VERSION ""

NS_ :

BS_:

BU_:

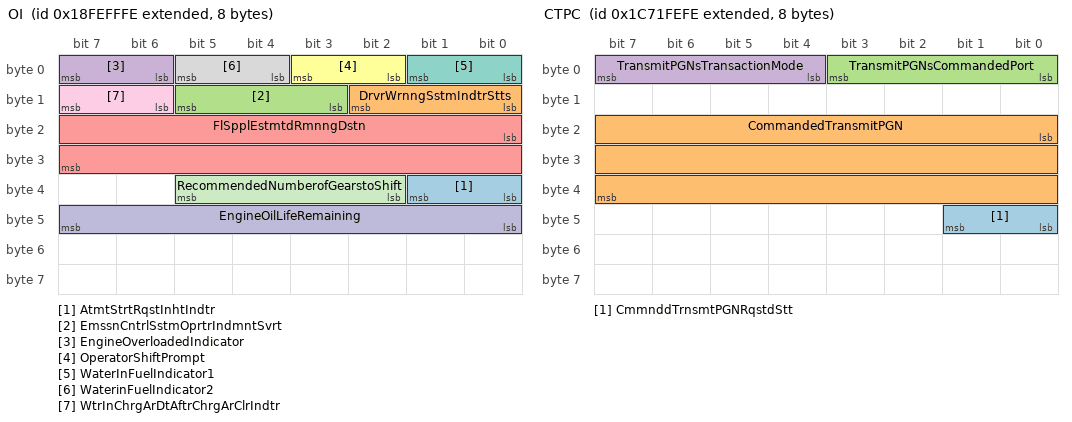
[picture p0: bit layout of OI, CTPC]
BO_ 2566848510 OI: 8 Vector__XXX
 SG_ AtmtStrtRqstInhtIndtr : 32|2@1+ (1,0) [0|3] "" Vector__XXX
 SG_ DrvrWrnngSstmIndtrStts : 8|3@1+ (1,0) [0|7] "" Vector__XXX
 SG_ EmssnCntrlSstmOprtrIndmntSvrt : 11|3@1+ (1,0) [0|7] "" Vector__XXX
 SG_ EngineOverloadedIndicator : 6|2@1+ (1,0) [0|3] "" Vector__XXX
 SG_ FlSpplEstmtdRmnngDstn : 16|16@1+ (1,0) [0|64255] "km" Vector__XXX
 SG_ OperatorShiftPrompt : 2|2@1+ (1,0) [0|3] "" Vector__XXX
 SG_ WaterInFuelIndicator1 : 0|2@1+ (1,0) [0|3] "" Vector__XXX
 SG_ WaterinFuelIndicator2 : 4|2@1+ (1,0) [0|3] "" Vector__XXX
 SG_ WtrInChrgArDtAftrChrgArClrIndtr : 14|2@1+ (1,0) [0|3] "" Vector__XXX
 SG_ EngineOilLifeRemaining : 40|8@1+ (0.4,0) [0|100] "%" Vector__XXX
 SG_ RecommendedNumberofGearstoShift : 34|4@1+ (1,0) [0|13] "count" Vector__XXX

BO_ 2624716542 CTPC: 8 Vector__XXX
 SG_ CmmnddTrnsmtPGNRqstdStt : 40|2@1+ (1,0) [0|3] "" Vector__XXX
 SG_ CommandedTransmitPGN : 16|24@1+ (1,0) [0|16777215] "binary" Vector__XXX
 SG_ TransmitPGNsCommandedPort : 0|4@1+ (1,0) [0|15] "" Vector__XXX
 SG_ TransmitPGNsTransactionMode : 4|4@1+ (1,0) [0|15] "" Vector__XXX

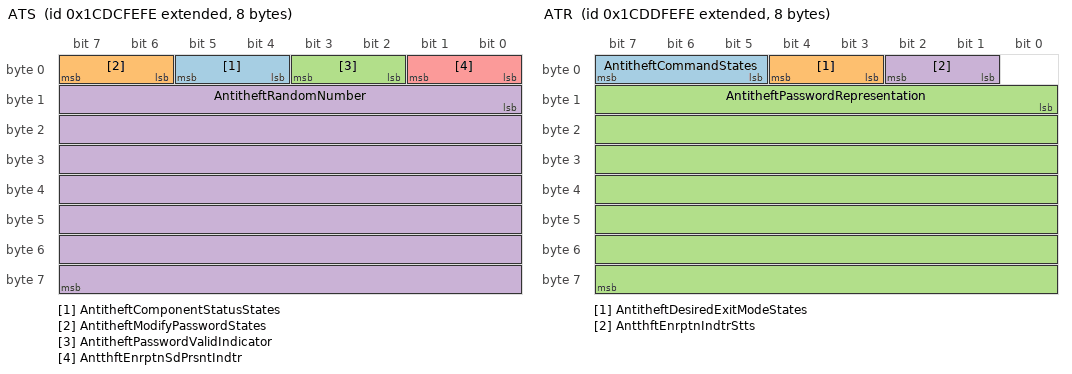
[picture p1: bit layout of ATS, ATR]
BO_ 2631728894 ATS: 8 Vector__XXX
 SG_ AntitheftComponentStatusStates : 4|2@1+ (1,0) [0|3] "" Vector__XXX
 SG_ AntitheftModifyPasswordStates : 6|2@1+ (1,0) [0|3] "" Vector__XXX
 SG_ AntitheftPasswordValidIndicator : 2|2@1+ (1,0) [0|3] "" Vector__XXX
 SG_ AntitheftRandomNumber : 8|56@1+ (1,0) [0|255] "ASCII" Vector__XXX
 SG_ AntthftEnrptnSdPrsntIndtr : 0|2@1+ (1,0) [0|3] "" Vector__XXX

BO_ 2631794430 ATR: 8 Vector__XXX
 SG_ AntitheftCommandStates : 5|3@1+ (1,0) [0|7] "" Vector__XXX
 SG_ AntitheftDesiredExitModeStates : 3|2@1+ (1,0) [0|3] "" Vector__XXX
 SG_ AntitheftPasswordRepresentation : 8|56@1+ (1,0) [0|255] "ASCII" Vector__XXX
 SG_ AntthftEnrptnIndtrStts : 1|2@1+ (1,0) [0|3] "" Vector__XXX

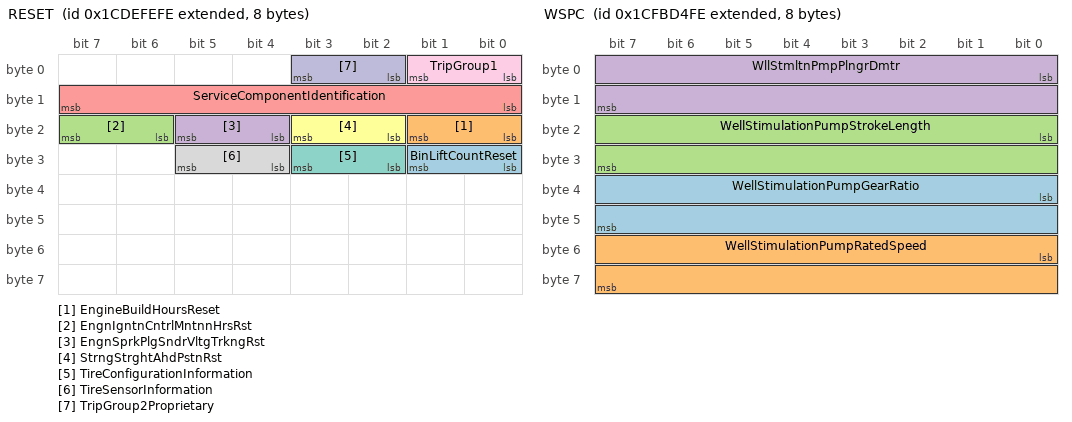
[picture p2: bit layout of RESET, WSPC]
BO_ 2631859966 RESET: 8 Vector__XXX
 SG_ BinLiftCountReset : 24|2@1+ (1,0) [0|3] "" Vector__XXX
 SG_ EngineBuildHoursReset : 16|2@1+ (1,0) [0|3] "" Vector__XXX
 SG_ EngnIgntnCntrlMntnnHrsRst : 22|2@1+ (1,0) [0|3] "" Vector__XXX
 SG_ EngnSprkPlgSndrVltgTrkngRst : 20|2@1+ (1,0) [0|3] "" Vector__XXX
 SG_ ServiceComponentIdentification : 8|8@1+ (1,0) [0|250] "ID" Vector__XXX
 SG_ StrngStrghtAhdPstnRst : 18|2@1+ (1,0) [0|3] "" Vector__XXX
 SG_ TireConfigurationInformation : 26|2@1+ (1,0) [0|3] "" Vector__XXX
 SG_ TireSensorInformation : 28|2@1+ (1,0) [0|3] "" Vector__XXX
 SG_ TripGroup1 : 0|2@1+ (1,0) [0|3] "" Vector__XXX
 SG_ TripGroup2Proprietary : 2|2@1+ (1,0) [0|3] "" Vector__XXX

BO_ 2633734398 EO2: 8 Vector__XXX
 SG_ EngineActualExhaust2Oxygen : 0|16@1+ (0.0025,0) [0|160.6375] "%" Vector__XXX

BO_ 2633749502 WSPT: 16 Vector__XXX
 SG_ WellStimulationPumpCycleCount : 96|32@1+ (1,0) [0|4211081215] "count" Vector__XXX
 SG_ WellStimulationPumpWorkingHours : 64|32@1+ (1,0) [0|4211081215] "s" Vector__XXX
 SG_ WllStmltnPmpFldEndWrkngHrs : 0|32@1+ (1,0) [0|4211081215] "s" Vector__XXX
 SG_ WllStmltnPmpPwrEndWrkngHrs : 32|32@1+ (1,0) [0|4211081215] "s" Vector__XXX

BO_ 2633749758 WSPC: 8 Vector__XXX
 SG_ WellStimulationPumpGearRatio : 32|16@1+ (0.001,0) [0|64.255] "Ratio" Vector__XXX
 SG_ WellStimulationPumpRatedSpeed : 48|16@1+ (0.125,0) [0|8031.875] "rpm" Vector__XXX
 SG_ WellStimulationPumpStrokeLength : 16|16@1+ (1,0) [0|64255] "mm" Vector__XXX
 SG_ WllStmltnPmpPlngrDmtr : 0|16@1+ (1,0) [0|64255] "mm" Vector__XXX

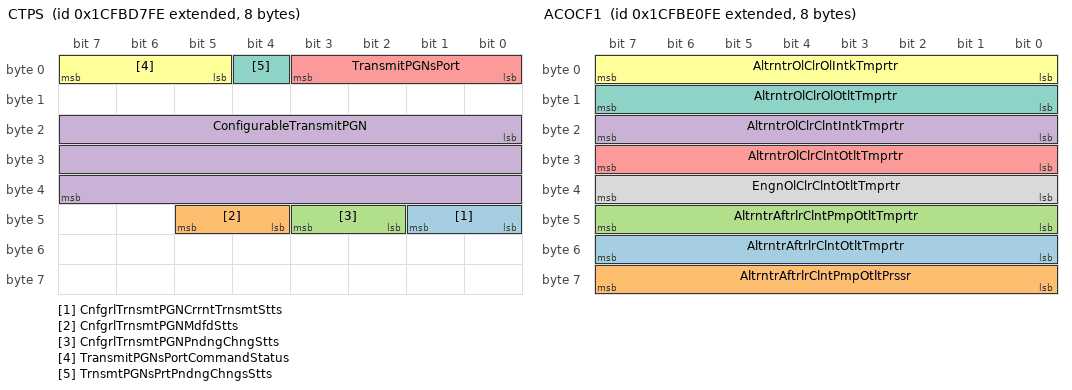
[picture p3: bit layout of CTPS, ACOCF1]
BO_ 2633750526 CTPS: 8 Vector__XXX
 SG_ CnfgrlTrnsmtPGNCrrntTrnsmtStts : 40|2@1+ (1,0) [0|3] "" Vector__XXX
 SG_ CnfgrlTrnsmtPGNMdfdStts : 44|2@1+ (1,0) [0|3] "" Vector__XXX
 SG_ CnfgrlTrnsmtPGNPndngChngStts : 42|2@1+ (1,0) [0|3] "" Vector__XXX
 SG_ ConfigurableTransmitPGN : 16|24@1+ (1,0) [0|16777215] "binary" Vector__XXX
 SG_ TransmitPGNsPort : 0|4@1+ (1,0) [0|15] "" Vector__XXX
 SG_ TransmitPGNsPortCommandStatus : 5|3@1+ (1,0) [0|7] "" Vector__XXX
 SG_ TrnsmtPGNsPrtPndngChngsStts : 4|1@1+ (1,0) [0|1] "" Vector__XXX

BO_ 2633752830 ACOCF1: 8 Vector__XXX
 SG_ AltrntrAftrlrClntOtltTmprtr : 48|8@1+ (1,-40) [-40|210] "degC" Vector__XXX
 SG_ AltrntrAftrlrClntPmpOtltPrssr : 56|8@1+ (2,0) [0|500] "kPa" Vector__XXX
 SG_ AltrntrAftrlrClntPmpOtltTmprtr : 40|8@1+ (1,-40) [-40|210] "degC" Vector__XXX
 SG_ AltrntrOlClrClntIntkTmprtr : 16|8@1+ (1,-40) [-40|210] "degC" Vector__XXX
 SG_ AltrntrOlClrClntOtltTmprtr : 24|8@1+ (1,-40) [-40|210] "degC" Vector__XXX
 SG_ AltrntrOlClrOlIntkTmprtr : 0|8@1+ (1,-40) [-40|210] "degC" Vector__XXX
 SG_ AltrntrOlClrOlOtltTmprtr : 8|8@1+ (1,-40) [-40|210] "degC" Vector__XXX
 SG_ EngnOlClrClntOtltTmprtr : 32|8@1+ (1,-40) [-40|210] "degC" Vector__XXX

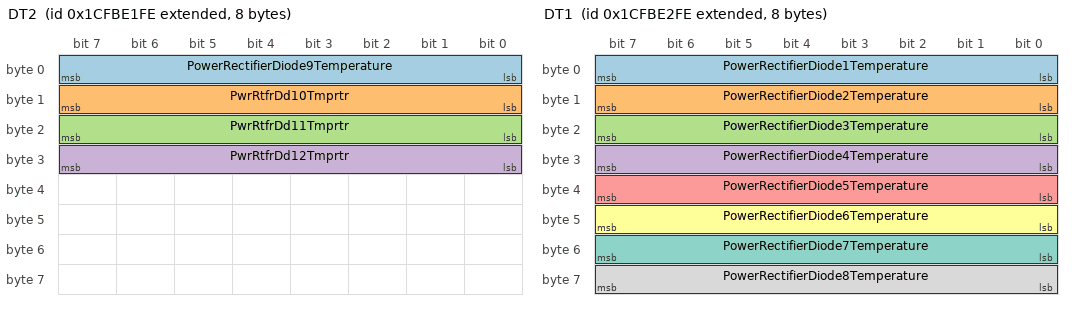
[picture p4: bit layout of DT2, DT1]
BO_ 2633753086 DT2: 8 Vector__XXX
 SG_ PowerRectifierDiode9Temperature : 0|8@1+ (1,-40) [-40|210] "degC" Vector__XXX
 SG_ PwrRtfrDd10Tmprtr : 8|8@1+ (1,-40) [-40|210] "degC" Vector__XXX
 SG_ PwrRtfrDd11Tmprtr : 16|8@1+ (1,-40) [-40|210] "degC" Vector__XXX
 SG_ PwrRtfrDd12Tmprtr : 24|8@1+ (1,-40) [-40|210] "degC" Vector__XXX

BO_ 2633753342 DT1: 8 Vector__XXX
 SG_ PowerRectifierDiode1Temperature : 0|8@1+ (1,-40) [-40|210] "degC" Vector__XXX
 SG_ PowerRectifierDiode2Temperature : 8|8@1+ (1,-40) [-40|210] "degC" Vector__XXX
 SG_ PowerRectifierDiode3Temperature : 16|8@1+ (1,-40) [-40|210] "degC" Vector__XXX
 SG_ PowerRectifierDiode4Temperature : 24|8@1+ (1,-40) [-40|210] "degC" Vector__XXX
 SG_ PowerRectifierDiode5Temperature : 32|8@1+ (1,-40) [-40|210] "degC" Vector__XXX
 SG_ PowerRectifierDiode6Temperature : 40|8@1+ (1,-40) [-40|210] "degC" Vector__XXX
 SG_ PowerRectifierDiode7Temperature : 48|8@1+ (1,-40) [-40|210] "degC" Vector__XXX
 SG_ PowerRectifierDiode8Temperature : 56|8@1+ (1,-40) [-40|210] "degC" Vector__XXX

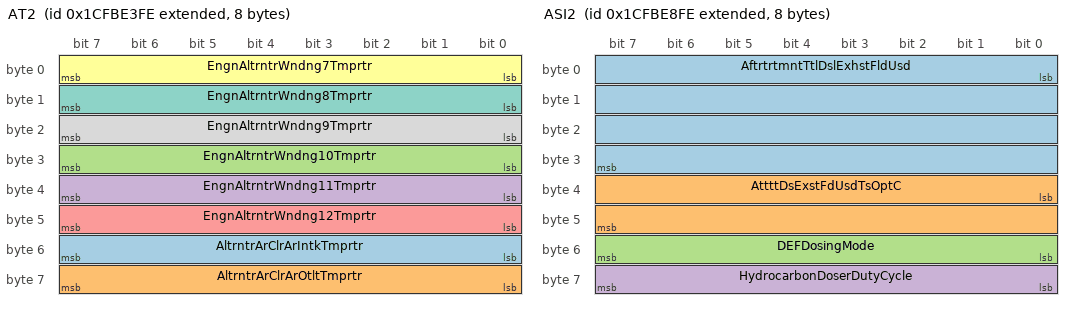
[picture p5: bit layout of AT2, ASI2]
BO_ 2633753598 AT2: 8 Vector__XXX
 SG_ AltrntrArClrArIntkTmprtr : 48|8@1+ (1,-40) [-40|210] "degC" Vector__XXX
 SG_ AltrntrArClrArOtltTmprtr : 56|8@1+ (1,-40) [-40|210] "degC" Vector__XXX
 SG_ EngnAltrntrWndng10Tmprtr : 24|8@1+ (1,-40) [-40|210] "degC" Vector__XXX
 SG_ EngnAltrntrWndng11Tmprtr : 32|8@1+ (1,-40) [-40|210] "degC" Vector__XXX
 SG_ EngnAltrntrWndng12Tmprtr : 40|8@1+ (1,-40) [-40|210] "degC" Vector__XXX
 SG_ EngnAltrntrWndng7Tmprtr : 0|8@1+ (1,-40) [-40|210] "degC" Vector__XXX
 SG_ EngnAltrntrWndng8Tmprtr : 8|8@1+ (1,-40) [-40|210] "degC" Vector__XXX
 SG_ EngnAltrntrWndng9Tmprtr : 16|8@1+ (1,-40) [-40|210] "degC" Vector__XXX

BO_ 2633754622 SCROII5: 8 Vector__XXX
 SG_ Aftrtrtmnt1SCRIntkHghTmprtrTm : 0|32@1+ (1,0) [0|4211081215] "s" Vector__XXX
 SG_ SCROptIdtEOvdTtAtvtT : 32|32@1+ (1,0) [0|4211081215] "s" Vector__XXX

BO_ 2633754878 ASI2: 8 Vector__XXX
 SG_ AftrtrtmntTtlDslExhstFldUsd : 0|32@1+ (0.5,0) [0|2105540607.5] "l" Vector__XXX
 SG_ AttttDsExstFdUsdTsOptC : 32|16@1+ (0.1,0) [0|6425.5] "l" Vector__XXX
 SG_ DEFDosingMode : 48|8@1+ (1,0) [0|250] "count" Vector__XXX
 SG_ HydrocarbonDoserDutyCycle : 56|8@1+ (0.4,0) [0|100] "%" Vector__XXX

BO_ 2633755390 E1NET1: 19 Vector__XXX
 SG_ DefaultGatewayOctet1 : 72|8@1+ (1,0) [0|255] "count" Vector__XXX
 SG_ DefaultGatewayOctet2 : 80|8@1+ (1,0) [0|255] "count" Vector__XXX
 SG_ DefaultGatewayOctet3 : 88|8@1+ (1,0) [0|255] "count" Vector__XXX
 SG_ DefaultGatewayOctet4 : 96|8@1+ (1,0) [0|255] "count" Vector__XXX
 SG_ DHCPStatus : 0|4@1+ (1,0) [0|15] "" Vector__XXX
 SG_ EthernetLinkStatus : 4|2@1+ (1,0) [0|3] "" Vector__XXX
 SG_ IPv4AddressOctet1 : 8|8@1+ (1,0) [0|255] "count" Vector__XXX
 SG_ IPv4AddressOctet2 : 16|8@1+ (1,0) [0|255] "count" Vector__XXX
 SG_ IPv4AddressOctet3 : 24|8@1+ (1,0) [0|255] "count" Vector__XXX
 SG_ IPv4AddressOctet4 : 32|8@1+ (1,0) [0|255] "count" Vector__XXX
 SG_ MACAddressOctet1 : 104|8@1+ (1,0) [0|255] "count" Vector__XXX
 SG_ MACAddressOctet2 : 112|8@1+ (1,0) [0|255] "count" Vector__XXX
 SG_ MACAddressOctet3 : 120|8@1+ (1,0) [0|255] "count" Vector__XXX
 SG_ MACAddressOctet4 : 128|8@1+ (1,0) [0|255] "count" Vector__XXX
 SG_ MACAddressOctet5 : 136|8@1+ (1,0) [0|255] "count" Vector__XXX
 SG_ MACAddressOctet6 : 144|8@1+ (1,0) [0|255] "count" Vector__XXX
 SG_ SubnetMaskOctet1 : 40|8@1+ (1,0) [0|255] "count" Vector__XXX
 SG_ SubnetMaskOctet2 : 48|8@1+ (1,0) [0|255] "count" Vector__XXX
 SG_ SubnetMaskOctet3 : 56|8@1+ (1,0) [0|255] "count" Vector__XXX
 SG_ SubnetMaskOctet4 : 64|8@1+ (1,0) [0|255] "count" Vector__XXX

BO_ 2633764094 EVAP2: 4 Vector__XXX
 SG_ CanisterPurgeValveCommand : 8|8@1+ (0.4,0) [0|100] "%" Vector__XXX
 SG_ CanisterVentValve : 0|2@1+ (1,0) [0|3] "" Vector__XXX
 SG_ GasolineFuelTankPressure : 16|16@1+ (0.1,-3212.7) [-3212.7|3212.8] "kPa" Vector__XXX

BO_ 2633764350 FPS1: 8 Vector__XXX
 SG_ FirePumpEngagementCycles : 32|16@1+ (1,0) [0|64255] "count" Vector__XXX
 SG_ FirePumpOperationTime : 0|32@1+ (1,0) [0|4211081215] "s" Vector__XXX

BO_ 2633769726 EEC19: 8 Vector__XXX
 SG_ EngnExhstFlwRtExtnddRng : 32|32@1+ (0.001,0) [0|4211081.215] "kg/h" Vector__XXX
 SG_ TotalEngineEnergy : 0|32@1+ (1,0) [0|4211081215] "kWh" Vector__XXX

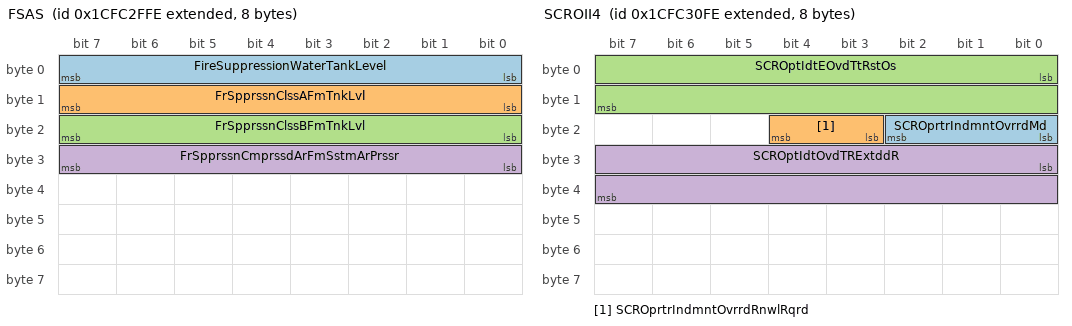
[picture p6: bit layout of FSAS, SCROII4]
BO_ 2633773054 FSAS: 8 Vector__XXX
 SG_ FireSuppressionWaterTankLevel : 0|8@1+ (0.4,0) [0|100] "%" Vector__XXX
 SG_ FrSpprssnClssAFmTnkLvl : 8|8@1+ (0.4,0) [0|100] "%" Vector__XXX
 SG_ FrSpprssnClssBFmTnkLvl : 16|8@1+ (0.4,0) [0|100] "%" Vector__XXX
 SG_ FrSpprssnCmprssdArFmSstmArPrssr : 24|8@1+ (8,0) [0|2000] "kPa" Vector__XXX

BO_ 2633773310 SCROII4: 8 Vector__XXX
 SG_ SCROprtrIndmntOvrrdMd : 16|3@1+ (1,0) [0|7] "" Vector__XXX
 SG_ SCROprtrIndmntOvrrdRnwlRqrd : 19|2@1+ (1,0) [0|3] "" Vector__XXX
 SG_ SCROptIdtEOvdTtRstOs : 0|16@1+ (1,0) [0|64255] "count" Vector__XXX
 SG_ SCROptIdtOvdTRExtddR : 24|16@1+ (1,0) [0|64255] "min" Vector__XXX

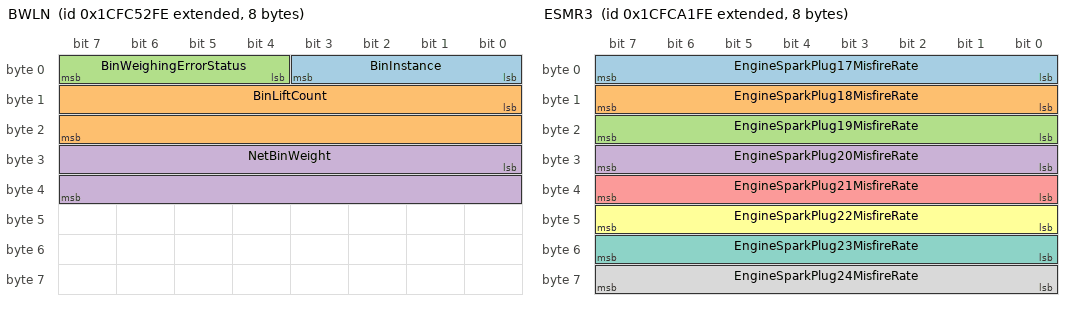
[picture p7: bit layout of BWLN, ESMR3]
BO_ 2633782014 BWLN: 8 Vector__XXX
 SG_ BinInstance : 0|4@1+ (1,0) [0|15] "count" Vector__XXX
 SG_ BinLiftCount : 8|16@1+ (1,0) [0|64255] "count" Vector__XXX
 SG_ BinWeighingErrorStatus : 4|4@1+ (1,0) [0|15] "" Vector__XXX
 SG_ NetBinWeight : 24|16@1+ (2,0) [0|128510] "kg" Vector__XXX

BO_ 2633785086 HVESSHIST: 19 Vector__XXX
 SG_ HVESSStateofHealth : 0|8@1+ (0.4,0) [0|100] "%" Vector__XXX
 SG_ HVESSCnttrOpnUndrLdCnt : 8|16@1+ (1,0) [0|64255] "count" Vector__XXX
 SG_ HVESSTotalEnergyThroughput : 24|32@1+ (100,0) [0|421108121500] "Watt-hour" Vector__XXX
 SG_ HVESSTotalAccumulatedCharge : 56|32@1+ (100,0) [0|421108121500] "Ah" Vector__XXX
 SG_ HVESSTotalLifetimeEnergyInput : 88|32@1+ (1,0) [0|4211081215] "kWh" Vector__XXX
 SG_ HVESSTotalLifetimeEnergyOutput : 120|32@1+ (1,0) [0|4211081215] "kWh" Vector__XXX

BO_ 2633801982 MFEH: 8 Vector__XXX
 SG_ EngnTtlHrsfDslFlOprtn : 32|32@1+ (0.05,0) [0|210554060.75] "h" Vector__XXX
 SG_ EngnTtlHrsfGssFlOprtn : 0|32@1+ (0.05,0) [0|210554060.75] "h" Vector__XXX

BO_ 2633802238 ESMR3: 8 Vector__XXX
 SG_ EngineSparkPlug17MisfireRate : 0|8@1+ (0.4,0) [0|100] "%" Vector__XXX
 SG_ EngineSparkPlug18MisfireRate : 8|8@1+ (0.4,0) [0|100] "%" Vector__XXX
 SG_ EngineSparkPlug19MisfireRate : 16|8@1+ (0.4,0) [0|100] "%" Vector__XXX
 SG_ EngineSparkPlug20MisfireRate : 24|8@1+ (0.4,0) [0|100] "%" Vector__XXX
 SG_ EngineSparkPlug21MisfireRate : 32|8@1+ (0.4,0) [0|100] "%" Vector__XXX
 SG_ EngineSparkPlug22MisfireRate : 40|8@1+ (0.4,0) [0|100] "%" Vector__XXX
 SG_ EngineSparkPlug23MisfireRate : 48|8@1+ (0.4,0) [0|100] "%" Vector__XXX
 SG_ EngineSparkPlug24MisfireRate : 56|8@1+ (0.4,0) [0|100] "%" Vector__XXX

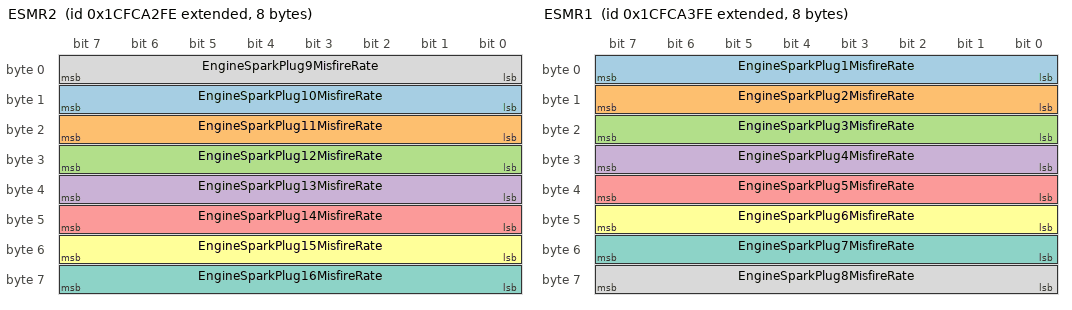
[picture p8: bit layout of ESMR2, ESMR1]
BO_ 2633802494 ESMR2: 8 Vector__XXX
 SG_ EngineSparkPlug10MisfireRate : 8|8@1+ (0.4,0) [0|100] "%" Vector__XXX
 SG_ EngineSparkPlug11MisfireRate : 16|8@1+ (0.4,0) [0|100] "%" Vector__XXX
 SG_ EngineSparkPlug12MisfireRate : 24|8@1+ (0.4,0) [0|100] "%" Vector__XXX
 SG_ EngineSparkPlug13MisfireRate : 32|8@1+ (0.4,0) [0|100] "%" Vector__XXX
 SG_ EngineSparkPlug14MisfireRate : 40|8@1+ (0.4,0) [0|100] "%" Vector__XXX
 SG_ EngineSparkPlug15MisfireRate : 48|8@1+ (0.4,0) [0|100] "%" Vector__XXX
 SG_ EngineSparkPlug16MisfireRate : 56|8@1+ (0.4,0) [0|100] "%" Vector__XXX
 SG_ EngineSparkPlug9MisfireRate : 0|8@1+ (0.4,0) [0|100] "%" Vector__XXX

BO_ 2633802750 ESMR1: 8 Vector__XXX
 SG_ EngineSparkPlug1MisfireRate : 0|8@1+ (0.4,0) [0|100] "%" Vector__XXX
 SG_ EngineSparkPlug2MisfireRate : 8|8@1+ (0.4,0) [0|100] "%" Vector__XXX
 SG_ EngineSparkPlug3MisfireRate : 16|8@1+ (0.4,0) [0|100] "%" Vector__XXX
 SG_ EngineSparkPlug4MisfireRate : 24|8@1+ (0.4,0) [0|100] "%" Vector__XXX
 SG_ EngineSparkPlug5MisfireRate : 32|8@1+ (0.4,0) [0|100] "%" Vector__XXX
 SG_ EngineSparkPlug6MisfireRate : 40|8@1+ (0.4,0) [0|100] "%" Vector__XXX
 SG_ EngineSparkPlug7MisfireRate : 48|8@1+ (0.4,0) [0|100] "%" Vector__XXX
 SG_ EngineSparkPlug8MisfireRate : 56|8@1+ (0.4,0) [0|100] "%" Vector__XXX

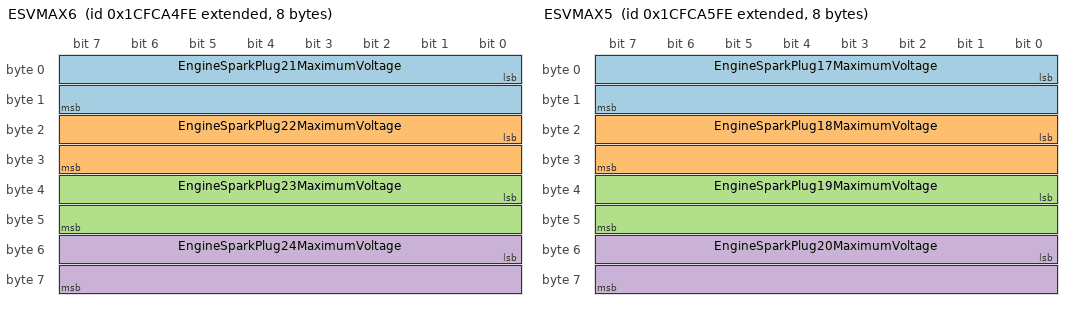
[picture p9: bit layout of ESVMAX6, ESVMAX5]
BO_ 2633803006 ESVMAX6: 8 Vector__XXX
 SG_ EngineSparkPlug21MaximumVoltage : 0|16@1+ (1,0) [0|64255] "V" Vector__XXX
 SG_ EngineSparkPlug22MaximumVoltage : 16|16@1+ (1,0) [0|64255] "V" Vector__XXX
 SG_ EngineSparkPlug23MaximumVoltage : 32|16@1+ (1,0) [0|64255] "V" Vector__XXX
 SG_ EngineSparkPlug24MaximumVoltage : 48|16@1+ (1,0) [0|64255] "V" Vector__XXX

BO_ 2633803262 ESVMAX5: 8 Vector__XXX
 SG_ EngineSparkPlug17MaximumVoltage : 0|16@1+ (1,0) [0|64255] "V" Vector__XXX
 SG_ EngineSparkPlug18MaximumVoltage : 16|16@1+ (1,0) [0|64255] "V" Vector__XXX
 SG_ EngineSparkPlug19MaximumVoltage : 32|16@1+ (1,0) [0|64255] "V" Vector__XXX
 SG_ EngineSparkPlug20MaximumVoltage : 48|16@1+ (1,0) [0|64255] "V" Vector__XXX

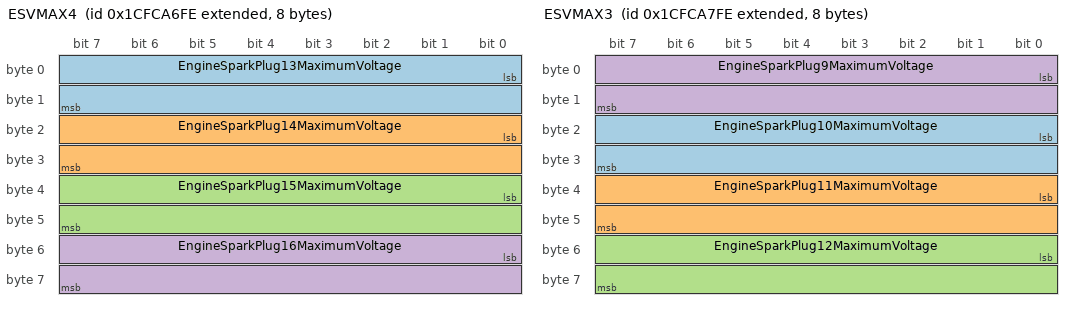
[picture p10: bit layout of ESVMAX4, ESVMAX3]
BO_ 2633803518 ESVMAX4: 8 Vector__XXX
 SG_ EngineSparkPlug13MaximumVoltage : 0|16@1+ (1,0) [0|64255] "V" Vector__XXX
 SG_ EngineSparkPlug14MaximumVoltage : 16|16@1+ (1,0) [0|64255] "V" Vector__XXX
 SG_ EngineSparkPlug15MaximumVoltage : 32|16@1+ (1,0) [0|64255] "V" Vector__XXX
 SG_ EngineSparkPlug16MaximumVoltage : 48|16@1+ (1,0) [0|64255] "V" Vector__XXX

BO_ 2633803774 ESVMAX3: 8 Vector__XXX
 SG_ EngineSparkPlug10MaximumVoltage : 16|16@1+ (1,0) [0|64255] "V" Vector__XXX
 SG_ EngineSparkPlug11MaximumVoltage : 32|16@1+ (1,0) [0|64255] "V" Vector__XXX
 SG_ EngineSparkPlug12MaximumVoltage : 48|16@1+ (1,0) [0|64255] "V" Vector__XXX
 SG_ EngineSparkPlug9MaximumVoltage : 0|16@1+ (1,0) [0|64255] "V" Vector__XXX

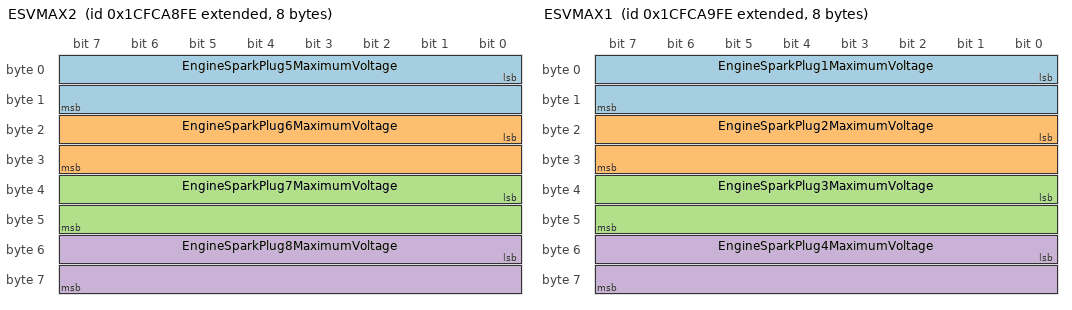
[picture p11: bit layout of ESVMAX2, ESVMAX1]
BO_ 2633804030 ESVMAX2: 8 Vector__XXX
 SG_ EngineSparkPlug5MaximumVoltage : 0|16@1+ (1,0) [0|64255] "V" Vector__XXX
 SG_ EngineSparkPlug6MaximumVoltage : 16|16@1+ (1,0) [0|64255] "V" Vector__XXX
 SG_ EngineSparkPlug7MaximumVoltage : 32|16@1+ (1,0) [0|64255] "V" Vector__XXX
 SG_ EngineSparkPlug8MaximumVoltage : 48|16@1+ (1,0) [0|64255] "V" Vector__XXX

BO_ 2633804286 ESVMAX1: 8 Vector__XXX
 SG_ EngineSparkPlug1MaximumVoltage : 0|16@1+ (1,0) [0|64255] "V" Vector__XXX
 SG_ EngineSparkPlug2MaximumVoltage : 16|16@1+ (1,0) [0|64255] "V" Vector__XXX
 SG_ EngineSparkPlug3MaximumVoltage : 32|16@1+ (1,0) [0|64255] "V" Vector__XXX
 SG_ EngineSparkPlug4MaximumVoltage : 48|16@1+ (1,0) [0|64255] "V" Vector__XXX

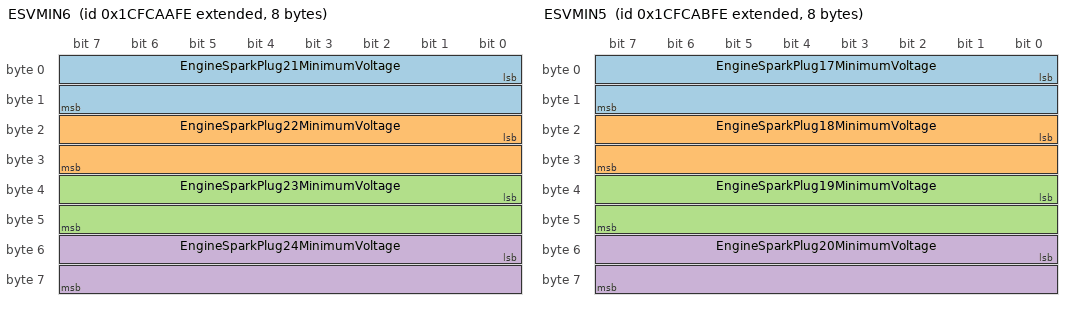
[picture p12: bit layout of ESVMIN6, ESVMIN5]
BO_ 2633804542 ESVMIN6: 8 Vector__XXX
 SG_ EngineSparkPlug21MinimumVoltage : 0|16@1+ (1,0) [0|64255] "V" Vector__XXX
 SG_ EngineSparkPlug22MinimumVoltage : 16|16@1+ (1,0) [0|64255] "V" Vector__XXX
 SG_ EngineSparkPlug23MinimumVoltage : 32|16@1+ (1,0) [0|64255] "V" Vector__XXX
 SG_ EngineSparkPlug24MinimumVoltage : 48|16@1+ (1,0) [0|64255] "V" Vector__XXX

BO_ 2633804798 ESVMIN5: 8 Vector__XXX
 SG_ EngineSparkPlug17MinimumVoltage : 0|16@1+ (1,0) [0|64255] "V" Vector__XXX
 SG_ EngineSparkPlug18MinimumVoltage : 16|16@1+ (1,0) [0|64255] "V" Vector__XXX
 SG_ EngineSparkPlug19MinimumVoltage : 32|16@1+ (1,0) [0|64255] "V" Vector__XXX
 SG_ EngineSparkPlug20MinimumVoltage : 48|16@1+ (1,0) [0|64255] "V" Vector__XXX

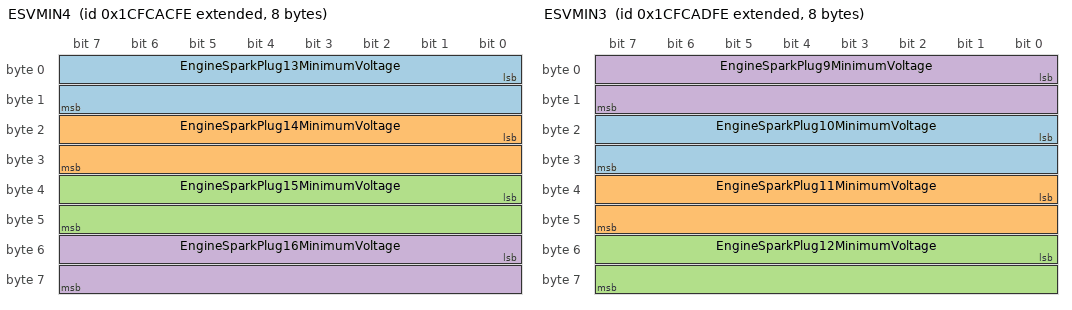
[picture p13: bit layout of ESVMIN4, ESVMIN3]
BO_ 2633805054 ESVMIN4: 8 Vector__XXX
 SG_ EngineSparkPlug13MinimumVoltage : 0|16@1+ (1,0) [0|64255] "V" Vector__XXX
 SG_ EngineSparkPlug14MinimumVoltage : 16|16@1+ (1,0) [0|64255] "V" Vector__XXX
 SG_ EngineSparkPlug15MinimumVoltage : 32|16@1+ (1,0) [0|64255] "V" Vector__XXX
 SG_ EngineSparkPlug16MinimumVoltage : 48|16@1+ (1,0) [0|64255] "V" Vector__XXX

BO_ 2633805310 ESVMIN3: 8 Vector__XXX
 SG_ EngineSparkPlug10MinimumVoltage : 16|16@1+ (1,0) [0|64255] "V" Vector__XXX
 SG_ EngineSparkPlug11MinimumVoltage : 32|16@1+ (1,0) [0|64255] "V" Vector__XXX
 SG_ EngineSparkPlug12MinimumVoltage : 48|16@1+ (1,0) [0|64255] "V" Vector__XXX
 SG_ EngineSparkPlug9MinimumVoltage : 0|16@1+ (1,0) [0|64255] "V" Vector__XXX

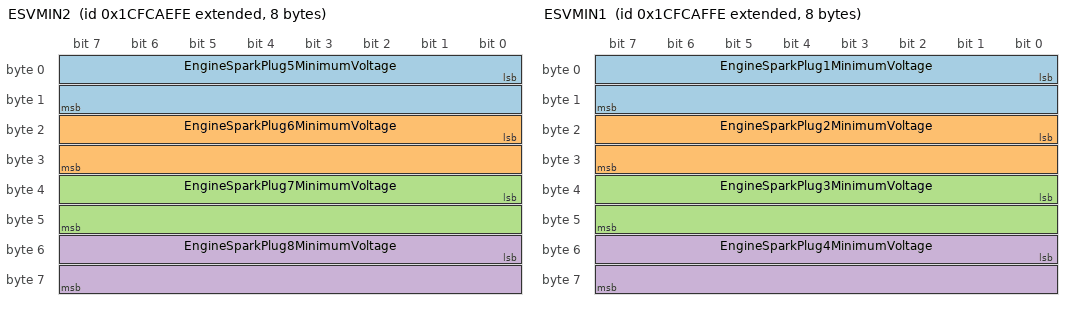
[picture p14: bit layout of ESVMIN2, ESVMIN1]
BO_ 2633805566 ESVMIN2: 8 Vector__XXX
 SG_ EngineSparkPlug5MinimumVoltage : 0|16@1+ (1,0) [0|64255] "V" Vector__XXX
 SG_ EngineSparkPlug6MinimumVoltage : 16|16@1+ (1,0) [0|64255] "V" Vector__XXX
 SG_ EngineSparkPlug7MinimumVoltage : 32|16@1+ (1,0) [0|64255] "V" Vector__XXX
 SG_ EngineSparkPlug8MinimumVoltage : 48|16@1+ (1,0) [0|64255] "V" Vector__XXX

BO_ 2633805822 ESVMIN1: 8 Vector__XXX
 SG_ EngineSparkPlug1MinimumVoltage : 0|16@1+ (1,0) [0|64255] "V" Vector__XXX
 SG_ EngineSparkPlug2MinimumVoltage : 16|16@1+ (1,0) [0|64255] "V" Vector__XXX
 SG_ EngineSparkPlug3MinimumVoltage : 32|16@1+ (1,0) [0|64255] "V" Vector__XXX
 SG_ EngineSparkPlug4MinimumVoltage : 48|16@1+ (1,0) [0|64255] "V" Vector__XXX

BO_ 2633806078 EICMH: 8 Vector__XXX
 SG_ EngnIgntnCntrlMdl1TmRmnng : 0|32@1+ (0.05,0) [0|210554060.75] "h" Vector__XXX
 SG_ EngnIgntnCntrlMdl2TmRmnng : 32|32@1+ (0.05,0) [0|210554060.75] "h" Vector__XXX

BO_ 2633825022 EEC11: 8 Vector__XXX
 SG_ EngnExhstGsRrltn2Vlv1Cntrl : 0|16@1+ (0.0025,0) [0|160.6375] "%" Vector__XXX
 SG_ EngnExhstGsRrltn2Vlv1PstnErrr : 32|16@1+ (0.004,-125) [-125|132.02] "%" Vector__XXX
 SG_ EngnExhstGsRrltn2Vlv2Cntrl : 16|16@1+ (0.0025,0) [0|160.6375] "%" Vector__XXX
 SG_ EngnExhstGsRrltn2Vlv2PstnErrr : 48|16@1+ (0.004,-125) [-125|132.02] "%" Vector__XXX

BO_ 2633825534 EMAC: 8 Vector__XXX
 SG_ EExstMdB1FwBVvAttCt : 0|16@1+ (0.0025,0) [0|160.6375] "%" Vector__XXX
 SG_ EExstMdB2FwBVvAttCt : 16|16@1+ (0.0025,0) [0|160.6375] "%" Vector__XXX

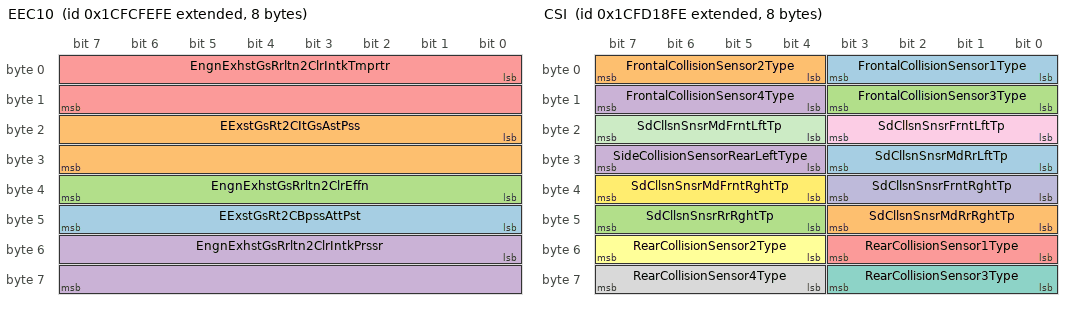
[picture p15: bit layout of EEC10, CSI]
BO_ 2633826046 EEC10: 8 Vector__XXX
 SG_ EExstGsRt2CBpssAttPst : 40|8@1+ (0.4,0) [0|100] "%" Vector__XXX
 SG_ EExstGsRt2CItGsAstPss : 16|16@1+ (0.5,0) [0|32127.5] "kPa" Vector__XXX
 SG_ EngnExhstGsRrltn2ClrEffn : 32|8@1+ (0.4,0) [0|100] "%" Vector__XXX
 SG_ EngnExhstGsRrltn2ClrIntkPrssr : 48|16@1+ (5,0) [0|321275] "kPa" Vector__XXX
 SG_ EngnExhstGsRrltn2ClrIntkTmprtr : 0|16@1+ (0.03125,-273) [-273|1734.96875] "degC" Vector__XXX

BO_ 2633828606 EOM: 8 Vector__XXX
 SG_ EngineOilDensity : 16|16@1+ (0.00003052,0) [0|1.961] "g/cc" Vector__XXX
 SG_ EngineOilTemperature3 : 48|16@1+ (0.03125,-273) [-273|1734.96875] "degC" Vector__XXX
 SG_ EngineOilViscosity : 0|16@1+ (0.015625,0) [0|1003.984375] "Cp" Vector__XXX
 SG_ EngnOlRltvDltrtHghRsltn : 32|16@1+ (0.0001220703125,0) [0|7.844] "" Vector__XXX

BO_ 2633832702 CSI: 8 Vector__XXX
 SG_ FrontalCollisionSensor1Type : 0|4@1+ (1,0) [0|15] "" Vector__XXX
 SG_ FrontalCollisionSensor2Type : 4|4@1+ (1,0) [0|15] "" Vector__XXX
 SG_ FrontalCollisionSensor3Type : 8|4@1+ (1,0) [0|15] "" Vector__XXX
 SG_ FrontalCollisionSensor4Type : 12|4@1+ (1,0) [0|15] "" Vector__XXX
 SG_ RearCollisionSensor1Type : 48|4@1+ (1,0) [0|15] "" Vector__XXX
 SG_ RearCollisionSensor2Type : 52|4@1+ (1,0) [0|15] "" Vector__XXX
 SG_ RearCollisionSensor3Type : 56|4@1+ (1,0) [0|15] "" Vector__XXX
 SG_ RearCollisionSensor4Type : 60|4@1+ (1,0) [0|15] "" Vector__XXX
 SG_ SdCllsnSnsrFrntLftTp : 16|4@1+ (1,0) [0|15] "" Vector__XXX
 SG_ SdCllsnSnsrFrntRghtTp : 32|4@1+ (1,0) [0|15] "" Vector__XXX
 SG_ SdCllsnSnsrMdFrntLftTp : 20|4@1+ (1,0) [0|15] "" Vector__XXX
 SG_ SdCllsnSnsrMdFrntRghtTp : 36|4@1+ (1,0) [0|15] "" Vector__XXX
 SG_ SdCllsnSnsrMdRrLftTp : 24|4@1+ (1,0) [0|15] "" Vector__XXX
 SG_ SdCllsnSnsrMdRrRghtTp : 40|4@1+ (1,0) [0|15] "" Vector__XXX
 SG_ SdCllsnSnsrRrRghtTp : 44|4@1+ (1,0) [0|15] "" Vector__XXX
 SG_ SideCollisionSensorRearLeftType : 28|4@1+ (1,0) [0|15] "" Vector__XXX

BO_ 2633832958 ILI: 200 Vector__XXX
 SG_ DrvrArgIgntrLp1stStgRsstn : 0|16@1+ (0.1,0) [0|6425.5] "ohm" Vector__XXX
 SG_ DrvrArgIgntrLp2ndStgRsstn : 32|16@1+ (0.1,0) [0|6425.5] "ohm" Vector__XXX
 SG_ DrvrBltTnsnrIgntrLpRsstn : 64|16@1+ (0.1,0) [0|6425.5] "ohm" Vector__XXX
 SG_ PssngrArgIgntrLp1stStgRsstn : 16|16@1+ (0.1,0) [0|6425.5] "ohm" Vector__XXX
 SG_ PssngrArgIgntrLp2ndStgRsstn : 48|16@1+ (0.1,0) [0|6425.5] "ohm" Vector__XXX
 SG_ PssngrBltTnsnrIgntrLpRsstn : 80|16@1+ (0.1,0) [0|6425.5] "ohm" Vector__XXX
 SG_ SdBgIgntrLp1LftRsstn : 96|16@1+ (0.1,0) [0|6425.5] "ohm" Vector__XXX
 SG_ SdBgIgntrLp1RghtRsstn : 128|16@1+ (0.1,0) [0|6425.5] "ohm" Vector__XXX
 SG_ SdBgIgntrLp2LftRsstn : 112|16@1+ (0.1,0) [0|6425.5] "ohm" Vector__XXX
 SG_ SdBgIgntrLp2RghtRsstn : 144|16@1+ (0.1,0) [0|6425.5] "ohm" Vector__XXX
 SG_ SpecialIgnitorLoop10Resistance : 304|16@1+ (0.1,0) [0|6425.5] "ohm" Vector__XXX
 SG_ SpecialIgnitorLoop11Resistance : 320|16@1+ (0.1,0) [0|6425.5] "ohm" Vector__XXX
 SG_ SpecialIgnitorLoop12Resistance : 336|16@1+ (0.1,0) [0|6425.5] "ohm" Vector__XXX
 SG_ SpecialIgnitorLoop13Resistance : 352|16@1+ (0.1,0) [0|6425.5] "ohm" Vector__XXX
 SG_ SpecialIgnitorLoop14Resistance : 368|16@1+ (0.1,0) [0|6425.5] "ohm" Vector__XXX
 SG_ SpecialIgnitorLoop15Resistance : 384|16@1+ (0.1,0) [0|6425.5] "ohm" Vector__XXX
 SG_ SpecialIgnitorLoop16Resistance : 400|16@1+ (0.1,0) [0|6425.5] "ohm" Vector__XXX
 SG_ SpecialIgnitorLoop17Resistance : 416|16@1+ (0.1,0) [0|6425.5] "ohm" Vector__XXX
 SG_ SpecialIgnitorLoop18Resistance : 432|16@1+ (0.1,0) [0|6425.5] "ohm" Vector__XXX
 SG_ SpecialIgnitorLoop19Resistance : 448|16@1+ (0.1,0) [0|6425.5] "ohm" Vector__XXX
 SG_ SpecialIgnitorLoop1Resistance : 160|16@1+ (0.1,0) [0|6425.5] "ohm" Vector__XXX
 SG_ SpecialIgnitorLoop20Resistance : 464|16@1+ (0.1,0) [0|6425.5] "ohm" Vector__XXX
 SG_ SpecialIgnitorLoop21Resistance : 480|16@1+ (0.1,0) [0|6425.5] "ohm" Vector__XXX
 SG_ SpecialIgnitorLoop22Resistance : 496|16@1+ (0.1,0) [0|6425.5] "ohm" Vector__XXX
 SG_ SpecialIgnitorLoop23Resistance : 512|16@1+ (0.1,0) [0|6425.5] "ohm" Vector__XXX
 SG_ SpecialIgnitorLoop24Resistance : 528|16@1+ (0.1,0) [0|6425.5] "ohm" Vector__XXX
 SG_ SpecialIgnitorLoop25Resistance : 544|16@1+ (0.1,0) [0|6425.5] "ohm" Vector__XXX
 SG_ SpecialIgnitorLoop26Resistance : 560|16@1+ (0.1,0) [0|6425.5] "ohm" Vector__XXX
 SG_ SpecialIgnitorLoop27Resistance : 576|16@1+ (0.1,0) [0|6425.5] "ohm" Vector__XXX
 SG_ SpecialIgnitorLoop28Resistance : 592|16@1+ (0.1,0) [0|6425.5] "ohm" Vector__XXX
 SG_ SpecialIgnitorLoop29Resistance : 608|16@1+ (0.1,0) [0|6425.5] "ohm" Vector__XXX
 SG_ SpecialIgnitorLoop2Resistance : 176|16@1+ (0.1,0) [0|6425.5] "ohm" Vector__XXX
 SG_ SpecialIgnitorLoop30Resistance : 624|16@1+ (0.1,0) [0|6425.5] "ohm" Vector__XXX
 SG_ SpecialIgnitorLoop31Resistance : 640|16@1+ (0.1,0) [0|6425.5] "ohm" Vector__XXX
 SG_ SpecialIgnitorLoop32Resistance : 656|16@1+ (0.1,0) [0|6425.5] "ohm" Vector__XXX
 SG_ SpecialIgnitorLoop33Resistance : 672|16@1+ (0.1,0) [0|6425.5] "ohm" Vector__XXX
 SG_ SpecialIgnitorLoop34Resistance : 688|16@1+ (0.1,0) [0|6425.5] "ohm" Vector__XXX
 SG_ SpecialIgnitorLoop35Resistance : 704|16@1+ (0.1,0) [0|6425.5] "ohm" Vector__XXX
 SG_ SpecialIgnitorLoop36Resistance : 720|16@1+ (0.1,0) [0|6425.5] "ohm" Vector__XXX
 SG_ SpecialIgnitorLoop37Resistance : 736|16@1+ (0.1,0) [0|6425.5] "ohm" Vector__XXX
 SG_ SpecialIgnitorLoop38Resistance : 752|16@1+ (0.1,0) [0|6425.5] "ohm" Vector__XXX
 SG_ SpecialIgnitorLoop39Resistance : 768|16@1+ (0.1,0) [0|6425.5] "ohm" Vector__XXX
 SG_ SpecialIgnitorLoop3Resistance : 192|16@1+ (0.1,0) [0|6425.5] "ohm" Vector__XXX
 SG_ SpecialIgnitorLoop40Resistance : 784|16@1+ (0.1,0) [0|6425.5] "ohm" Vector__XXX
 SG_ SpecialIgnitorLoop41Resistance : 800|16@1+ (0.1,0) [0|6425.5] "ohm" Vector__XXX
 SG_ SpecialIgnitorLoop42Resistance : 816|16@1+ (0.1,0) [0|6425.5] "ohm" Vector__XXX
 SG_ SpecialIgnitorLoop43Resistance : 832|16@1+ (0.1,0) [0|6425.5] "ohm" Vector__XXX
 SG_ SpecialIgnitorLoop44Resistance : 848|16@1+ (0.1,0) [0|6425.5] "ohm" Vector__XXX
 SG_ SpecialIgnitorLoop45Resistance : 864|16@1+ (0.1,0) [0|6425.5] "ohm" Vector__XXX
 SG_ SpecialIgnitorLoop46Resistance : 880|16@1+ (0.1,0) [0|6425.5] "ohm" Vector__XXX
 SG_ SpecialIgnitorLoop47Resistance : 896|16@1+ (0.1,0) [0|6425.5] "ohm" Vector__XXX
 SG_ SpecialIgnitorLoop48Resistance : 912|16@1+ (0.1,0) [0|6425.5] "ohm" Vector__XXX
 SG_ SpecialIgnitorLoop49Resistance : 928|16@1+ (0.1,0) [0|6425.5] "ohm" Vector__XXX
 SG_ SpecialIgnitorLoop4Resistance : 208|16@1+ (0.1,0) [0|6425.5] "ohm" Vector__XXX
 SG_ SpecialIgnitorLoop50Resistance : 944|16@1+ (0.1,0) [0|6425.5] "ohm" Vector__XXX
 SG_ SpecialIgnitorLoop51Resistance : 960|16@1+ (0.1,0) [0|6425.5] "ohm" Vector__XXX
 SG_ SpecialIgnitorLoop52Resistance : 976|16@1+ (0.1,0) [0|6425.5] "ohm" Vector__XXX
 SG_ SpecialIgnitorLoop53Resistance : 992|16@1+ (0.1,0) [0|6425.5] "ohm" Vector__XXX
 SG_ SpecialIgnitorLoop54Resistance : 1008|16@1+ (0.1,0) [0|6425.5] "ohm" Vector__XXX
 SG_ SpecialIgnitorLoop55Resistance : 1024|16@1+ (0.1,0) [0|6425.5] "ohm" Vector__XXX
 SG_ SpecialIgnitorLoop56Resistance : 1040|16@1+ (0.1,0) [0|6425.5] "ohm" Vector__XXX
 SG_ SpecialIgnitorLoop57Resistance : 1056|16@1+ (0.1,0) [0|6425.5] "ohm" Vector__XXX
 SG_ SpecialIgnitorLoop58Resistance : 1072|16@1+ (0.1,0) [0|6425.5] "ohm" Vector__XXX
 SG_ SpecialIgnitorLoop59Resistance : 1088|16@1+ (0.1,0) [0|6425.5] "ohm" Vector__XXX
 SG_ SpecialIgnitorLoop5Resistance : 224|16@1+ (0.1,0) [0|6425.5] "ohm" Vector__XXX
 SG_ SpecialIgnitorLoop60Resistance : 1104|16@1+ (0.1,0) [0|6425.5] "ohm" Vector__XXX
 SG_ SpecialIgnitorLoop61Resistance : 1120|16@1+ (0.1,0) [0|6425.5] "ohm" Vector__XXX
 SG_ SpecialIgnitorLoop62Resistance : 1136|16@1+ (0.1,0) [0|6425.5] "ohm" Vector__XXX
 SG_ SpecialIgnitorLoop63Resistance : 1152|16@1+ (0.1,0) [0|6425.5] "ohm" Vector__XXX
 SG_ SpecialIgnitorLoop64Resistance : 1168|16@1+ (0.1,0) [0|6425.5] "ohm" Vector__XXX
 SG_ SpecialIgnitorLoop65Resistance : 1184|16@1+ (0.1,0) [0|6425.5] "ohm" Vector__XXX
 SG_ SpecialIgnitorLoop66Resistance : 1200|16@1+ (0.1,0) [0|6425.5] "ohm" Vector__XXX
 SG_ SpecialIgnitorLoop67Resistance : 1216|16@1+ (0.1,0) [0|6425.5] "ohm" Vector__XXX
 SG_ SpecialIgnitorLoop68Resistance : 1232|16@1+ (0.1,0) [0|6425.5] "ohm" Vector__XXX
 SG_ SpecialIgnitorLoop69Resistance : 1248|16@1+ (0.1,0) [0|6425.5] "ohm" Vector__XXX
 SG_ SpecialIgnitorLoop6Resistance : 240|16@1+ (0.1,0) [0|6425.5] "ohm" Vector__XXX
 SG_ SpecialIgnitorLoop70Resistance : 1264|16@1+ (0.1,0) [0|6425.5] "ohm" Vector__XXX
 SG_ SpecialIgnitorLoop71Resistance : 1280|16@1+ (0.1,0) [0|6425.5] "ohm" Vector__XXX
 SG_ SpecialIgnitorLoop72Resistance : 1296|16@1+ (0.1,0) [0|6425.5] "ohm" Vector__XXX
 SG_ SpecialIgnitorLoop73Resistance : 1312|16@1+ (0.1,0) [0|6425.5] "ohm" Vector__XXX
 SG_ SpecialIgnitorLoop74Resistance : 1328|16@1+ (0.1,0) [0|6425.5] "ohm" Vector__XXX
 SG_ SpecialIgnitorLoop75Resistance : 1344|16@1+ (0.1,0) [0|6425.5] "ohm" Vector__XXX
 SG_ SpecialIgnitorLoop76Resistance : 1360|16@1+ (0.1,0) [0|6425.5] "ohm" Vector__XXX
 SG_ SpecialIgnitorLoop77Resistance : 1376|16@1+ (0.1,0) [0|6425.5] "ohm" Vector__XXX
 SG_ SpecialIgnitorLoop78Resistance : 1392|16@1+ (0.1,0) [0|6425.5] "ohm" Vector__XXX
 SG_ SpecialIgnitorLoop79Resistance : 1408|16@1+ (0.1,0) [0|6425.5] "ohm" Vector__XXX
 SG_ SpecialIgnitorLoop7Resistance : 256|16@1+ (0.1,0) [0|6425.5] "ohm" Vector__XXX
 SG_ SpecialIgnitorLoop80Resistance : 1424|16@1+ (0.1,0) [0|6425.5] "ohm" Vector__XXX
 SG_ SpecialIgnitorLoop81Resistance : 1440|16@1+ (0.1,0) [0|6425.5] "ohm" Vector__XXX
 SG_ SpecialIgnitorLoop82Resistance : 1456|16@1+ (0.1,0) [0|6425.5] "ohm" Vector__XXX
 SG_ SpecialIgnitorLoop83Resistance : 1472|16@1+ (0.1,0) [0|6425.5] "ohm" Vector__XXX
 SG_ SpecialIgnitorLoop84Resistance : 1488|16@1+ (0.1,0) [0|6425.5] "ohm" Vector__XXX
 SG_ SpecialIgnitorLoop85Resistance : 1504|16@1+ (0.1,0) [0|6425.5] "ohm" Vector__XXX
 SG_ SpecialIgnitorLoop86Resistance : 1520|16@1+ (0.1,0) [0|6425.5] "ohm" Vector__XXX
 SG_ SpecialIgnitorLoop87Resistance : 1536|16@1+ (0.1,0) [0|6425.5] "ohm" Vector__XXX
 SG_ SpecialIgnitorLoop88Resistance : 1552|16@1+ (0.1,0) [0|6425.5] "ohm" Vector__XXX
 SG_ SpecialIgnitorLoop89Resistance : 1568|16@1+ (0.1,0) [0|6425.5] "ohm" Vector__XXX
 SG_ SpecialIgnitorLoop8Resistance : 272|16@1+ (0.1,0) [0|6425.5] "ohm" Vector__XXX
 SG_ SpecialIgnitorLoop90Resistance : 1584|16@1+ (0.1,0) [0|6425.5] "ohm" Vector__XXX
 SG_ SpecialIgnitorLoop9Resistance : 288|16@1+ (0.1,0) [0|6425.5] "ohm" Vector__XXX

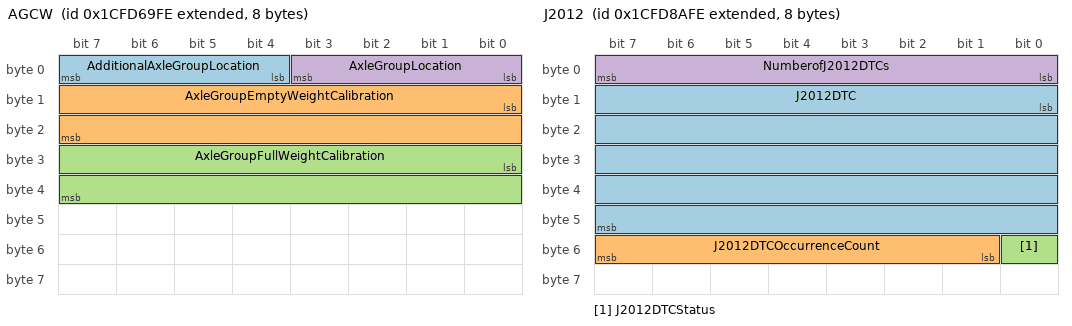
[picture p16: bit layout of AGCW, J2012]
BO_ 2633853438 AGCW: 8 Vector__XXX
 SG_ AdditionalAxleGroupLocation : 4|4@1+ (1,0) [0|15] "" Vector__XXX
 SG_ AxleGroupEmptyWeightCalibration : 8|16@1+ (2,0) [0|128510] "kg" Vector__XXX
 SG_ AxleGroupFullWeightCalibration : 24|16@1+ (2,0) [0|128510] "kg" Vector__XXX
 SG_ AxleGroupLocation : 0|4@1+ (1,0) [0|15] "" Vector__XXX

BO_ 2633861886 J2012: 8 Vector__XXX
 SG_ J2012DTC : 8|40@1+ (1,0) [0|255] "ASCII" Vector__XXX
 SG_ J2012DTCOccurrenceCount : 49|7@1+ (1,0) [0|127] "count" Vector__XXX
 SG_ J2012DTCStatus : 48|1@1+ (1,0) [0|1] "" Vector__XXX
 SG_ NumberofJ2012DTCs : 0|8@1+ (1,0) [0|250] "count" Vector__XXX

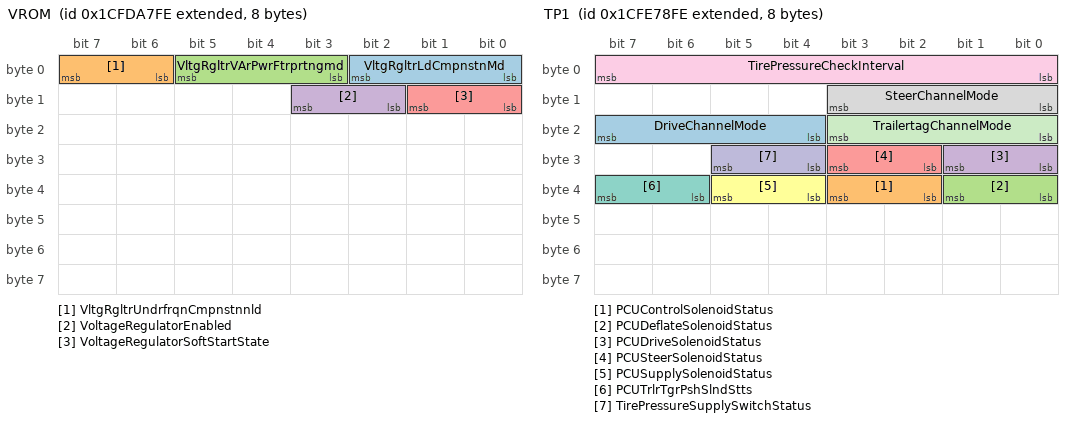
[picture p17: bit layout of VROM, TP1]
BO_ 2633869310 VROM: 8 Vector__XXX
 SG_ VltgRgltrLdCmpnstnMd : 0|3@1+ (1,0) [0|7] "" Vector__XXX
 SG_ VltgRgltrUndrfrqnCmpnstnnld : 6|2@1+ (1,0) [0|3] "" Vector__XXX
 SG_ VltgRgltrVArPwrFtrprtngmd : 3|3@1+ (1,0) [0|7] "" Vector__XXX
 SG_ VoltageRegulatorEnabled : 10|2@1+ (1,0) [0|3] "" Vector__XXX
 SG_ VoltageRegulatorSoftStartState : 8|2@1+ (1,0) [0|3] "" Vector__XXX

BO_ 2633878014 CMI: 8 Vector__XXX
 SG_ TtlCntfCnfgrtnChngsMd : 0|16@1+ (1,0) [0|64255] "count" Vector__XXX

BO_ 2633880062 FMS: 8 Vector__XXX
 SG_ FMSstandardDiagnosticsSupported : 0|2@1+ (1,0) [0|3] "" Vector__XXX
 SG_ FMSstandardRequestsSupported : 2|2@1+ (1,0) [0|3] "" Vector__XXX
 SG_ FMSstandardSWversionsupported : 8|32@1+ (1,0) [0|255] "ASCII" Vector__XXX

BO_ 2633883646 FWD: 8 Vector__XXX
 SG_ FrontWheelDriveActuatorStatus : 0|2@1+ (1,0) [0|3] "" Vector__XXX

BO_ 2633911806 TAVG: 8 Vector__XXX
 SG_ EngineTotalAverageFuelEconomy : 16|16@1+ (0.001953125,0) [0|125.498046875] "km/L" Vector__XXX
 SG_ EngineTotalAverageFuelRate : 0|16@1+ (0.05,0) [0|3212.75] "l/h" Vector__XXX

BO_ 2633922558 AP: 8 Vector__XXX
 SG_ AuxiliaryGagePressureReading1 : 16|16@1+ (0.5,0) [0|32127.5] "kPa" Vector__XXX
 SG_ AuxiliaryVacuumPressureReading : 0|16@1+ (0.5,0) [0|32127.5] "kPa" Vector__XXX
 SG_ AxlrAsltPrssrRdng : 32|16@1+ (0.5,0) [0|32127.5] "kPa" Vector__XXX

BO_ 2633922814 TP1: 8 Vector__XXX
 SG_ DriveChannelMode : 20|4@1+ (1,0) [0|15] "" Vector__XXX
 SG_ PCUControlSolenoidStatus : 34|2@1+ (1,0) [0|3] "" Vector__XXX
 SG_ PCUDeflateSolenoidStatus : 32|2@1+ (1,0) [0|3] "" Vector__XXX
 SG_ PCUDriveSolenoidStatus : 24|2@1+ (1,0) [0|3] "" Vector__XXX
 SG_ PCUSteerSolenoidStatus : 26|2@1+ (1,0) [0|3] "" Vector__XXX
 SG_ PCUSupplySolenoidStatus : 36|2@1+ (1,0) [0|3] "" Vector__XXX
 SG_ PCUTrlrTgrPshSlndStts : 38|2@1+ (1,0) [0|3] "" Vector__XXX
 SG_ SteerChannelMode : 8|4@1+ (1,0) [0|15] "" Vector__XXX
 SG_ TirePressureCheckInterval : 0|8@1+ (1,0) [0|250] "min" Vector__XXX
 SG_ TirePressureSupplySwitchStatus : 28|2@1+ (1,0) [0|3] "" Vector__XXX
 SG_ TrailertagChannelMode : 16|4@1+ (1,0) [0|15] "" Vector__XXX

BO_ 2633923070 TP2: 8 Vector__XXX
 SG_ DriveChannelTirePressureTarget : 16|16@1+ (0.5,0) [0|32127.5] "kPa" Vector__XXX
 SG_ SteerChannelTirePressureTarget : 32|16@1+ (0.5,0) [0|32127.5] "kPa" Vector__XXX
 SG_ TrlrTgOrPshChnnlTrPrssrTrgt : 0|16@1+ (0.5,0) [0|32127.5] "kPa" Vector__XXX

BO_ 2633923326 TP3: 8 Vector__XXX
 SG_ DriveChannelTirePressure : 16|16@1+ (0.5,0) [0|32127.5] "kPa" Vector__XXX
 SG_ SteerChannelTirePressure : 32|16@1+ (0.5,0) [0|32127.5] "kPa" Vector__XXX
 SG_ TrlrTgOrPshChnnlTrPrssr : 0|16@1+ (0.5,0) [0|32127.5] "kPa" Vector__XXX

BO_ 2633923582 CT1: 8 Vector__XXX
 SG_ EngineCylinder1CombustionTime : 0|16@1+ (0.01,0) [0|642.55] "ms" Vector__XXX
 SG_ EngineCylinder2CombustionTime : 16|16@1+ (0.01,0) [0|642.55] "ms" Vector__XXX
 SG_ EngineCylinder3CombustionTime : 32|16@1+ (0.01,0) [0|642.55] "ms" Vector__XXX
 SG_ EngineCylinder4CombustionTime : 48|16@1+ (0.01,0) [0|642.55] "ms" Vector__XXX

BO_ 2633923838 CT2: 8 Vector__XXX
 SG_ EngineCylinder5CombustionTime : 0|16@1+ (0.01,0) [0|642.55] "ms" Vector__XXX
 SG_ EngineCylinder6CombustionTime : 16|16@1+ (0.01,0) [0|642.55] "ms" Vector__XXX
 SG_ EngineCylinder7CombustionTime : 32|16@1+ (0.01,0) [0|642.55] "ms" Vector__XXX
 SG_ EngineCylinder8CombustionTime : 48|16@1+ (0.01,0) [0|642.55] "ms" Vector__XXX

BO_ 2633924094 CT3: 8 Vector__XXX
 SG_ EngineCylinder10CombustionTime : 16|16@1+ (0.01,0) [0|642.55] "ms" Vector__XXX
 SG_ EngineCylinder11CombustionTime : 32|16@1+ (0.01,0) [0|642.55] "ms" Vector__XXX
 SG_ EngineCylinder12CombustionTime : 48|16@1+ (0.01,0) [0|642.55] "ms" Vector__XXX
 SG_ EngineCylinder9CombustionTime : 0|16@1+ (0.01,0) [0|642.55] "ms" Vector__XXX

BO_ 2633924350 CT4: 8 Vector__XXX
 SG_ EngineCylinder13CombustionTime : 0|16@1+ (0.01,0) [0|642.55] "ms" Vector__XXX
 SG_ EngineCylinder14CombustionTime : 16|16@1+ (0.01,0) [0|642.55] "ms" Vector__XXX
 SG_ EngineCylinder15CombustionTime : 32|16@1+ (0.01,0) [0|642.55] "ms" Vector__XXX
 SG_ EngineCylinder16CombustionTime : 48|16@1+ (0.01,0) [0|642.55] "ms" Vector__XXX

BO_ 2633924606 CT5: 8 Vector__XXX
 SG_ EngineCylinder17CombustionTime : 0|16@1+ (0.01,0) [0|642.55] "ms" Vector__XXX
 SG_ EngineCylinder18CombustionTime : 16|16@1+ (0.01,0) [0|642.55] "ms" Vector__XXX
 SG_ EngineCylinder19CombustionTime : 32|16@1+ (0.01,0) [0|642.55] "ms" Vector__XXX
 SG_ EngineCylinder20CombustionTime : 48|16@1+ (0.01,0) [0|642.55] "ms" Vector__XXX

BO_ 2633924862 CT6: 8 Vector__XXX
 SG_ EngineAverageCombustionTime : 16|16@1+ (0.01,0) [0|642.55] "ms" Vector__XXX
 SG_ EngineDesiredCombustionTime : 0|16@1+ (0.01,0) [0|642.55] "ms" Vector__XXX

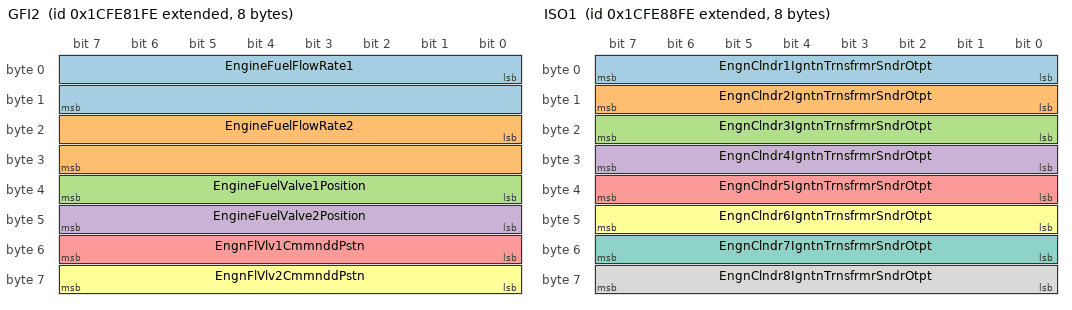
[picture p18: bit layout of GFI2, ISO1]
BO_ 2633925118 GFI2: 8 Vector__XXX
 SG_ EngineFuelFlowRate1 : 0|16@1+ (0.1,0) [0|6425.5] "(m*m*m)/h" Vector__XXX
 SG_ EngineFuelFlowRate2 : 16|16@1+ (0.1,0) [0|6425.5] "(m*m*m)/h" Vector__XXX
 SG_ EngineFuelValve1Position : 32|8@1+ (0.4,0) [0|100] "%" Vector__XXX
 SG_ EngineFuelValve2Position : 40|8@1+ (0.4,0) [0|100] "%" Vector__XXX
 SG_ EngnFlVlv1CmmnddPstn : 48|8@1+ (0.4,0) [0|100] "%" Vector__XXX
 SG_ EngnFlVlv2CmmnddPstn : 56|8@1+ (0.4,0) [0|100] "%" Vector__XXX

BO_ 2633925374 IT1: 8 Vector__XXX
 SG_ EngineCylinder1IgnitionTiming : 0|16@1+ (0.0078125,-200) [-200|301.99] "deg" Vector__XXX
 SG_ EngineCylinder2IgnitionTiming : 16|16@1+ (0.0078125,-200) [-200|301.99] "deg" Vector__XXX
 SG_ EngineCylinder3IgnitionTiming : 32|16@1+ (0.0078125,-200) [-200|301.99] "deg" Vector__XXX
 SG_ EngineCylinder4IgnitionTiming : 48|16@1+ (0.0078125,-200) [-200|301.99] "deg" Vector__XXX

BO_ 2633925630 IT2: 8 Vector__XXX
 SG_ EngineCylinder5IgnitionTiming : 0|16@1+ (0.0078125,-200) [-200|301.99] "deg" Vector__XXX
 SG_ EngineCylinder6IgnitionTiming : 16|16@1+ (0.0078125,-200) [-200|301.99] "deg" Vector__XXX
 SG_ EngineCylinder7IgnitionTiming : 32|16@1+ (0.0078125,-200) [-200|301.99] "deg" Vector__XXX
 SG_ EngineCylinder8IgnitionTiming : 48|16@1+ (0.0078125,-200) [-200|301.99] "deg" Vector__XXX

BO_ 2633925886 IT3: 8 Vector__XXX
 SG_ EngineCylinder10IgnitionTiming : 16|16@1+ (0.0078125,-200) [-200|301.99] "deg" Vector__XXX
 SG_ EngineCylinder11IgnitionTiming : 32|16@1+ (0.0078125,-200) [-200|301.99] "deg" Vector__XXX
 SG_ EngineCylinder12IgnitionTiming : 48|16@1+ (0.0078125,-200) [-200|301.99] "deg" Vector__XXX
 SG_ EngineCylinder9IgnitionTiming : 0|16@1+ (0.0078125,-200) [-200|301.99] "deg" Vector__XXX

BO_ 2633926142 IT4: 8 Vector__XXX
 SG_ EngineCylinder13IgnitionTiming : 0|16@1+ (0.0078125,-200) [-200|301.99] "deg" Vector__XXX
 SG_ EngineCylinder14IgnitionTiming : 16|16@1+ (0.0078125,-200) [-200|301.99] "deg" Vector__XXX
 SG_ EngineCylinder15IgnitionTiming : 32|16@1+ (0.0078125,-200) [-200|301.99] "deg" Vector__XXX
 SG_ EngineCylinder16IgnitionTiming : 48|16@1+ (0.0078125,-200) [-200|301.99] "deg" Vector__XXX

BO_ 2633926398 IT5: 8 Vector__XXX
 SG_ EngineCylinder17IgnitionTiming : 0|16@1+ (0.0078125,-200) [-200|301.99] "deg" Vector__XXX
 SG_ EngineCylinder18IgnitionTiming : 16|16@1+ (0.0078125,-200) [-200|301.99] "deg" Vector__XXX
 SG_ EngineCylinder19IgnitionTiming : 32|16@1+ (0.0078125,-200) [-200|301.99] "deg" Vector__XXX
 SG_ EngineCylinder20IgnitionTiming : 48|16@1+ (0.0078125,-200) [-200|301.99] "deg" Vector__XXX

BO_ 2633926654 IT6: 8 Vector__XXX
 SG_ EngineActualIgnitionTiming : 48|16@1+ (0.0078125,-200) [-200|301.99] "deg" Vector__XXX
 SG_ EngineDesiredIgnitionTiming1 : 0|16@1+ (0.0078125,-200) [-200|301.99] "deg" Vector__XXX
 SG_ EngineDesiredIgnitionTiming2 : 16|16@1+ (0.0078125,-200) [-200|301.99] "deg" Vector__XXX
 SG_ EngineDesiredIgnitionTiming3 : 32|16@1+ (0.0078125,-200) [-200|301.99] "deg" Vector__XXX

BO_ 2633926910 ISO1: 8 Vector__XXX
 SG_ EngnClndr1IgntnTrnsfrmrSndrOtpt : 0|8@1+ (1,-125) [-125|125] "%" Vector__XXX
 SG_ EngnClndr2IgntnTrnsfrmrSndrOtpt : 8|8@1+ (1,-125) [-125|125] "%" Vector__XXX
 SG_ EngnClndr3IgntnTrnsfrmrSndrOtpt : 16|8@1+ (1,-125) [-125|125] "%" Vector__XXX
 SG_ EngnClndr4IgntnTrnsfrmrSndrOtpt : 24|8@1+ (1,-125) [-125|125] "%" Vector__XXX
 SG_ EngnClndr5IgntnTrnsfrmrSndrOtpt : 32|8@1+ (1,-125) [-125|125] "%" Vector__XXX
 SG_ EngnClndr6IgntnTrnsfrmrSndrOtpt : 40|8@1+ (1,-125) [-125|125] "%" Vector__XXX
 SG_ EngnClndr7IgntnTrnsfrmrSndrOtpt : 48|8@1+ (1,-125) [-125|125] "%" Vector__XXX
 SG_ EngnClndr8IgntnTrnsfrmrSndrOtpt : 56|8@1+ (1,-125) [-125|125] "%" Vector__XXX

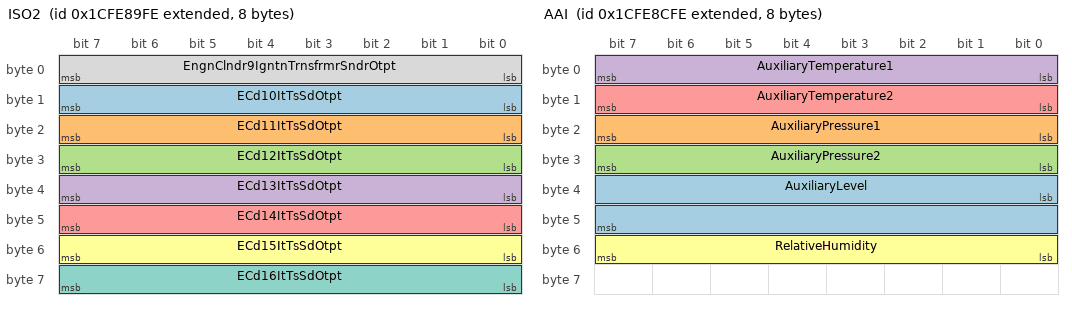
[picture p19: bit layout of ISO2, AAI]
BO_ 2633927166 ISO2: 8 Vector__XXX
 SG_ ECd10ItTsSdOtpt : 8|8@1+ (1,-125) [-125|125] "%" Vector__XXX
 SG_ ECd11ItTsSdOtpt : 16|8@1+ (1,-125) [-125|125] "%" Vector__XXX
 SG_ ECd12ItTsSdOtpt : 24|8@1+ (1,-125) [-125|125] "%" Vector__XXX
 SG_ ECd13ItTsSdOtpt : 32|8@1+ (1,-125) [-125|125] "%" Vector__XXX
 SG_ ECd14ItTsSdOtpt : 40|8@1+ (1,-125) [-125|125] "%" Vector__XXX
 SG_ ECd15ItTsSdOtpt : 48|8@1+ (1,-125) [-125|125] "%" Vector__XXX
 SG_ ECd16ItTsSdOtpt : 56|8@1+ (1,-125) [-125|125] "%" Vector__XXX
 SG_ EngnClndr9IgntnTrnsfrmrSndrOtpt : 0|8@1+ (1,-125) [-125|125] "%" Vector__XXX

BO_ 2633927422 ISO3: 8 Vector__XXX
 SG_ ECd17ItTsSdOtpt : 0|8@1+ (1,-125) [-125|125] "%" Vector__XXX
 SG_ ECd18ItTsSdOtpt : 8|8@1+ (1,-125) [-125|125] "%" Vector__XXX
 SG_ ECd19ItTsSdOtpt : 16|8@1+ (1,-125) [-125|125] "%" Vector__XXX
 SG_ ECd20ItTsSdOtpt : 24|8@1+ (1,-125) [-125|125] "%" Vector__XXX

BO_ 2633927678 GFP1: 8 Vector__XXX
 SG_ EngnArtFlDffrntlPrssr : 32|16@1+ (0.1,0) [0|6425.5] "kPa" Vector__XXX
 SG_ EngnFlVlv1DffrntlPrssr : 16|16@1+ (0.1,0) [0|6425.5] "kPa" Vector__XXX
 SG_ EngnFlVlv1IntkAsltPrssr : 0|16@1+ (0.1,0) [0|6425.5] "kPa" Vector__XXX
 SG_ EngnFlVlv1OtltAsltPrssr : 48|16@1+ (0.1,0) [0|6425.5] "kPa" Vector__XXX

BO_ 2633927934 AAI: 8 Vector__XXX
 SG_ AuxiliaryLevel : 32|16@1+ (0.1,0) [0|6425.5] "mm" Vector__XXX
 SG_ AuxiliaryPressure1 : 16|8@1+ (16,0) [0|4000] "kPa" Vector__XXX
 SG_ AuxiliaryPressure2 : 24|8@1+ (16,0) [0|4000] "kPa" Vector__XXX
 SG_ AuxiliaryTemperature1 : 0|8@1+ (1,-40) [-40|210] "degC" Vector__XXX
 SG_ AuxiliaryTemperature2 : 8|8@1+ (1,-40) [-40|210] "degC" Vector__XXX
 SG_ RelativeHumidity : 48|8@1+ (0.4,0) [0|100] "%" Vector__XXX

BO_ 2633928446 S2: 8 Vector__XXX
 SG_ ServiceComponentIdentification : 0|8@1+ (1,0) [0|250] "ID" Vector__XXX
 SG_ TimeSinceLastService : 8|16@1+ (1,-32127) [-32127|32128] "h" Vector__XXX

BO_ 2633929214 FL: 8 Vector__XXX
 SG_ EngineFluidBundLevel : 8|8@1+ (0.4,0) [0|100] "%" Vector__XXX
 SG_ EngineFuelLeakage1 : 0|2@1+ (1,0) [0|3] "" Vector__XXX
 SG_ EngineFuelLeakage2 : 2|2@1+ (1,0) [0|3] "" Vector__XXX

CM_ BO_ 2566848510 "Operator indicators";
CM_ SG_ 2566848510 AtmtStrtRqstInhtIndtr "Automatic Start Request Inhibit Indicator: State signal indicating an engine request for the Automatic Start Request Inhibit Indicator to be active or inactive. The start inhibit indicator can be of lamp or text form, located on (but not limited to) ...";
CM_ SG_ 2566848510 DrvrWrnngSstmIndtrStts "Driver Warning System Indicator Status: The desired illumination of the Euro VI defined driver warning system indicator for relevant malfunctions and diesel exhaust fluid (reagent) tank low level.  Used for Euro VI implementations.  See Euro VI imple...";
CM_ SG_ 2566848510 EmssnCntrlSstmOprtrIndmntSvrt "Emission Control System Operator Inducement Severity: Severity status of the operator inducement system for anomalies with the emission control system, such as tampering, low diesel exhaust fluid (reagent) quality, diesel exhaust fluid (reagent) tank...";
CM_ SG_ 2566848510 EngineOverloadedIndicator "Engine Overloaded Indicator: Signal which indicates that the engine is overloaded.00b = No01b = Yes10b = Error11b = Not available";
CM_ SG_ 2566848510 FlSpplEstmtdRmnngDstn "Fuel Supply Estimated Remaining Distance: Estimated remaining distance based on existing fuel supply.";
CM_ SG_ 2566848510 OperatorShiftPrompt "Operator Shift Prompt: Command to activate an indicator that advises the operator to shift to a different gear.  Typically this would be used as part of a fuel economy improvement or drivability aid.00b = indicator(s) inactive01b = upshift indicator ...";
CM_ SG_ 2566848510 WaterInFuelIndicator1 "Water In Fuel Indicator 1: Signal which indicates the presence of water in the fuel.00b = No01b = Yes10b = Error11b = Not available";
CM_ SG_ 2566848510 WaterinFuelIndicator2 "Water in Fuel Indicator 2: A second indicator of the presense of water in the fuel.  See also SPN 97.00b = No01b = Yes10b = Error11b = Not available";
CM_ SG_ 2566848510 WtrInChrgArDtAftrChrgArClrIndtr "Water In Charge Air Duct After Charge Air Cooler Indicator: Signal which indicates the presence of water in charge air duct after charge air cooler.00b = No01b = Yes10b = Error11b = Not available";
CM_ SG_ 2566848510 EngineOilLifeRemaining "Engine Oil Life Remaining: Signal which indicates the actual oil life remaining in percent. 100% means the engine oil is brand new, and 0% means the engine oil is at the end of its life.";
CM_ SG_ 2566848510 RecommendedNumberofGearstoShift "Recommended Number of Gears to Shift: Recommended number of gears to shift relative to current gear. Operator Shift Prompt (SPN 5675) indicates whether to shift up or down.";
CM_ BO_ 2624716542 "Configurable Transmit PGNs Command";
CM_ SG_ 2624716542 CmmnddTrnsmtPGNRqstdStt "Commanded Transmit PGN Requested State: Identifies the transmit enable state being commanded for the specified PG on the port identified in SPN 8595.  This parameter is only valid when SPN 8596 is set to 'Configure Port Transmit State' (1).  For tran...";
CM_ SG_ 2624716542 CommandedTransmitPGN "Commanded Transmit PGN: Identifies the PG to be acted on by the associated SPN 8598.";
CM_ SG_ 2624716542 TransmitPGNsCommandedPort "Transmit PGNs Commanded Port: Identifies the ECU communication port of the target Configurable ECU for this instance of PGN 28928.  The identification of each ECU communication port is ECU specific.  The correlation of ECU communication port to a phy...";
CM_ SG_ 2624716542 TransmitPGNsTransactionMode "Transmit PGNs Transaction Mode: Identifies the command or action being commanded to the target Configurable ECU of this instance of PGN 28928.0000b = Request Port Transmit Status – Identifies the message as a request for the list of configurable tran...";
CM_ BO_ 2631728894 "Anti-theft Status";
CM_ SG_ 2631728894 AntitheftComponentStatusStates "Anti-theft Component Status States: Indicates whether or not the component can be started.  00b = Unlocked01b = Locked10b = Blocked11b = Not defined00b -  Unlocked = This state indicates that the component can be started without the end user being re...";
CM_ SG_ 2631728894 AntitheftModifyPasswordStates "Anti-theft Modify Password States: This parameter is used to indicate whether a password request was successfully performed, or if the request could not be perform due to system constraints or if the request was not a valid request.  00b = Ok01b = Fu...";
CM_ SG_ 2631728894 AntitheftPasswordValidIndicator "Anti-theft Password Valid Indicator: Indicates the presence of a validated password.00b = Password is not a validated password01b = Password is a validated password10b = Error11b = Not available";
CM_ SG_ 2631728894 AntitheftRandomNumber "Anti-theft Random Number: A seven byte random numeric code provided by the component in response to an anti-theft request.  This parameter is sent as a numeric value utilizing the full range of 0 to FFFFFFFFFFFFFFh.  The most significant byte is sent...";
CM_ SG_ 2631728894 AntthftEnrptnSdPrsntIndtr "Anti-theft Encryption Seed Present Indicator: Indicates the presence of the encryption seed random number.00b = Random number is not present01b = Random number is present10b = Error11b = Not available";
CM_ BO_ 2631794430 "Anti-theft Request";
CM_ SG_ 2631794430 AntitheftCommandStates "Anti-theft Command States: This parameter is used to identify the specific requests being sent to the component. 000b = Add_Password001b = Delete_Password010b = Change_Password011b = Lock_or_Unlock100b = Check_Status101b = Login110b = Not defined111b...";
CM_ SG_ 2631794430 AntitheftDesiredExitModeStates "Anti-theft Desired Exit Mode States: This parameter is used to specify the desired triggers that are to be used by the component in deciding when to transition to the Locked state. 00b = Lock_Upon_Operator_Request01b = Lock_When_Key_Off10b = Not defi...";
CM_ SG_ 2631794430 AntitheftPasswordRepresentation "Anti-theft Password Representation: This parameter is the seven byte numeric code (i.e., 'encrypted password' or 'key') that is generated based on the encryption algorithm, the password supplied by the end user, and the random number seed given by th...";
CM_ SG_ 2631794430 AntthftEnrptnIndtrStts "Anti-theft Encryption Indicator States: This parameter is used to indicate if a random number seed is being requested, or if an encrypted password is being provided to the component. 00b = Encryption_Seed_Request01b = Encrypted_Code_Present10b = Not ...";
CM_ BO_ 2631859966 "Reset";
CM_ SG_ 2631859966 BinLiftCountReset "Bin Lift Count Reset: Used to reset the bin lift count as reported in PGN 64594.00b = Do not reset01b = Reset10b = Reserved11b = Take no action";
CM_ SG_ 2631859966 EngineBuildHoursReset "Engine Build Hours Reset: Command signal used to reset the engine rebuild hours.00b = Do not reset01b = Reset10b = Reserved11b = Take no action";
CM_ SG_ 2631859966 EngnIgntnCntrlMntnnHrsRst "Engine Ignition Control Maintenance Hours Reset: Used to reset the maintenance hour counter for an engine ignition control module.  The hours remaining until required maintenance is performed are reported in PGN 64688.00b = Do not reset01b = Reset10b...";
CM_ SG_ 2631859966 EngnSprkPlgSndrVltgTrkngRst "Engine Spark Plug Secondary Voltage Tracking Reset: Command signal used to reset the ignition controller average, maximum, and minimum level tracking of the spark plug secondary voltages and to reset the learned misfire rate.  Average secondary volta...";
CM_ SG_ 2631859966 ServiceComponentIdentification "Service Component Identification: Identification of component needing service.  See Table SPN911_A.";
CM_ SG_ 2631859966 StrngStrghtAhdPstnRst "Steering Straight Ahead Position Reset: Used to reset the straight ahead position for a steering sensor in the steering column or a steering controller's straight ahead position on any steerable axle.00b = Take no action - Do not Reset01b = Reset10b ...";
CM_ SG_ 2631859966 TireConfigurationInformation "Tire Configuration Information: Command signal used to initiate change in the tire configuration of the vehicle system. On receipt of this reset, necessary changes will be made in the tire configuration command information.00b = Take No Action01b = R...";
CM_ SG_ 2631859966 TireSensorInformation "Tire Sensor Information: Command signal used to initiate change in the tire sensor identification information.00b = Take no action01b = Reset10b = Reserved11b = Not applicable";
CM_ SG_ 2631859966 TripGroup1 "Trip Group 1: Command signal used to reset the PGs and parameters as defined in Table SPN988_A.00b = Take no action01b = Reset10b = Reserved11b = Not applicable";
CM_ SG_ 2631859966 TripGroup2Proprietary "Trip Group 2 - Proprietary: Command signal used to reset proprietary parameters associated with a trip but not defined within this document.00b = Take no action01b = Reset10b = Reserved11b = Not applicable";
CM_ BO_ 2633734398 "Exhaust Oxygen 2";
CM_ SG_ 2633734398 EngineActualExhaust2Oxygen "Engine Actual Exhaust 2 Oxygen: The actual amount of oxygen in the second exhaust represented as a percentage by volume with respect to the total volume of exhaust gases leaving the engine.";
CM_ BO_ 2633749502 "Well Stimulation Pump System Lifetime Totals";
CM_ SG_ 2633749502 WellStimulationPumpCycleCount "Well Stimulation Pump Cycle Count: The total number of cycles on the well stimulation pump. A cycle is defined as a working stage from start to finish.";
CM_ SG_ 2633749502 WellStimulationPumpWorkingHours "Well Stimulation Pump Working Hours: The accumulated amount of time the Well Stimulation Pump has spent working.";
CM_ SG_ 2633749502 WllStmltnPmpFldEndWrkngHrs "Well Stimulation Pump Fluid End Working Hours: The accumulated time of operation of the fluid end of the pump while under operating conditions.";
CM_ SG_ 2633749502 WllStmltnPmpPwrEndWrkngHrs "Well Stimulation Pump Power End Working Hours: The accumulated time of operation of the power end of the pump while under operating conditions.";
CM_ BO_ 2633749758 "Well Stimulation Pump System Configuration";
CM_ SG_ 2633749758 WellStimulationPumpGearRatio "Well Stimulation Pump Gear Ratio: Actual ratio of input shaft speed to output shaft speed.";
CM_ SG_ 2633749758 WellStimulationPumpRatedSpeed "Well Stimulation Pump Rated Speed: The rated speed of the well stimulation pump.";
CM_ SG_ 2633749758 WellStimulationPumpStrokeLength "Well Stimulation Pump Stroke Length: The stroke length of the plunger in a well stimulation pump.";
CM_ SG_ 2633749758 WllStmltnPmpPlngrDmtr "Well Stimulation Pump Plunger Diameter: The diameter of the well stimulation pump plungers";
CM_ BO_ 2633750526 "Configurable Transmit PGNs Status";
CM_ SG_ 2633750526 CnfgrlTrnsmtPGNCrrntTrnsmtStts "Configurable Transmit PGN Current Transmit Status: Indicates the current transmit status of the associated PG on the port identified in SPN 8599.00b = PG is currently configured for transmit on the port identified in SPN 8599.01b = PG is not currentl...";
CM_ SG_ 2633750526 CnfgrlTrnsmtPGNMdfdStts "Configurable Transmit PGN Modified Status: Indicates if able to honor the transmit status change request issued in the triggering PGN 28928 message for the associated PG on the port identified in SPN 8595.  This parameter is reported as '0' only if t...";
CM_ SG_ 2633750526 CnfgrlTrnsmtPGNPndngChngStts "Configurable Transmit PGN Pending Change Status: Indicates if there is a pending change to the transmit capability of the associated PG on the port identified in SPN 8599.00b = Pending transmit change to disable for the port identified in SPN 8599.01...";
CM_ SG_ 2633750526 ConfigurableTransmitPGN "Configurable Transmit PGN: Identifies the PG for which the associated SPNs 8603, 8604, & 8605 apply.";
CM_ SG_ 2633750526 TransmitPGNsPort "Transmit PGNs Port: Identifies the ECU communications port of the responding Configurable ECU that is in context for this instance of PGN 64471.  If changes are accepted by the Configurable ECU, then this is the port affected.  The identification of ...";
CM_ SG_ 2633750526 TransmitPGNsPortCommandStatus "Transmit PGNs Port Command Status: Indicates the overall success in performing the commanded transaction in PGN 28928.  000b = Positive Acknowledgment – PGN 28928 commanded transaction was processed without issue.001b = Negative Acknowledgment – PGN ...";
CM_ SG_ 2633750526 TrnsmtPGNsPrtPndngChngsStts "Transmit PGNs Port Pending Changes Status: Indicates if there are any pending transmit changes for the specified ECU communication port. 0b = No pending changes to the transmit status for any supported PGs for the port identified in SPN 8599.1b = Tra...";
CM_ BO_ 2633752830 "Aftercooler and Oil Cooler Fluids 1";
CM_ SG_ 2633752830 AltrntrAftrlrClntOtltTmprtr "Alternator Aftercooler Coolant Outlet Temperature: Temperature of liquid at the aftercooler outlet.";
CM_ SG_ 2633752830 AltrntrAftrlrClntPmpOtltPrssr "Alternator Aftercooler Coolant Pump Outlet Pressure: Pressure of liquid at the aftercooler pump outlet";
CM_ SG_ 2633752830 AltrntrAftrlrClntPmpOtltTmprtr "Alternator Aftercooler Coolant Pump Outlet Temperature: Temperature of liquid at the aftercooler coolant pump outlet.";
CM_ SG_ 2633752830 AltrntrOlClrClntIntkTmprtr "Alternator Oil Cooler Coolant Intake Temperature: Temperature of liquid as it enters the oil cooler of an alternator.";
CM_ SG_ 2633752830 AltrntrOlClrClntOtltTmprtr "Alternator Oil Cooler Coolant Outlet Temperature: Temperature of liquid after it exits the oil cooler of an alternator.";
CM_ SG_ 2633752830 AltrntrOlClrOlIntkTmprtr "Alternator Oil Cooler Oil Intake Temperature: Temperature of lubricant as it enters the oil cooler of an alternator.";
CM_ SG_ 2633752830 AltrntrOlClrOlOtltTmprtr "Alternator Oil Cooler Oil Outlet Temperature: Temperature of lubricant after it exits the oil cooler of an alternator.";
CM_ SG_ 2633752830 EngnOlClrClntOtltTmprtr "Engine Oil Cooler Coolant Outlet Temperature: Temperature of liquid after it exits the engine oil cooler.";
CM_ BO_ 2633753086 "Diode Temperature 2";
CM_ SG_ 2633753086 PowerRectifierDiode9Temperature "Power Rectifier Diode 9 Temperature: Temperature of this diode used in power rectifier.";
CM_ SG_ 2633753086 PwrRtfrDd10Tmprtr "Power Rectifier Diode 10 Temperature: Temperature of this diode used in power rectifier.";
CM_ SG_ 2633753086 PwrRtfrDd11Tmprtr "Power Rectifier Diode 11 Temperature: Temperature of this diode used in power rectifier.";
CM_ SG_ 2633753086 PwrRtfrDd12Tmprtr "Power Rectifier Diode 12 Temperature: Temperature of this diode used in power rectifier.";
CM_ BO_ 2633753342 "Diode Temperature 1";
CM_ SG_ 2633753342 PowerRectifierDiode1Temperature "Power Rectifier Diode 1 Temperature: Temperature of this diode used in power rectifier.";
CM_ SG_ 2633753342 PowerRectifierDiode2Temperature "Power Rectifier Diode 2 Temperature: Temperature of this diode used in power rectifier.";
CM_ SG_ 2633753342 PowerRectifierDiode3Temperature "Power Rectifier Diode 3 Temperature: Temperature of this diode used in power rectifier.";
CM_ SG_ 2633753342 PowerRectifierDiode4Temperature "Power Rectifier Diode 4 Temperature: Temperature of this diode used in power rectifier.";
CM_ SG_ 2633753342 PowerRectifierDiode5Temperature "Power Rectifier Diode 5 Temperature: Temperature of this diode used in power rectifier.";
CM_ SG_ 2633753342 PowerRectifierDiode6Temperature "Power Rectifier Diode 6 Temperature: Temperature of this diode used in power rectifier.";
CM_ SG_ 2633753342 PowerRectifierDiode7Temperature "Power Rectifier Diode 7 Temperature: Temperature of this diode used in power rectifier.";
CM_ SG_ 2633753342 PowerRectifierDiode8Temperature "Power Rectifier Diode 8 Temperature: Temperature of this diode used in power rectifier.";
CM_ BO_ 2633753598 "Alternator Temperature 2";
CM_ SG_ 2633753598 AltrntrArClrArIntkTmprtr "Alternator Air Cooler Air Intake Temperature: Temperature of air entering the air cooler in an alternator";
CM_ SG_ 2633753598 AltrntrArClrArOtltTmprtr "Alternator Air Cooler Air Outlet Temperature: Temperature of air after it exits from the air cooler in an alternator.";
CM_ SG_ 2633753598 EngnAltrntrWndng10Tmprtr "Engine Alternator Winding 10 Temperature: Temperature of this winding inside the alternator.";
CM_ SG_ 2633753598 EngnAltrntrWndng11Tmprtr "Engine Alternator Winding 11 Temperature: Temperature of this winding inside the alternator.";
CM_ SG_ 2633753598 EngnAltrntrWndng12Tmprtr "Engine Alternator Winding 12 Temperature: Temperature of this winding inside the alternator.";
CM_ SG_ 2633753598 EngnAltrntrWndng7Tmprtr "Engine Alternator Winding 7 Temperature: Temperature of this winding inside the alternator.";
CM_ SG_ 2633753598 EngnAltrntrWndng8Tmprtr "Engine Alternator Winding 8 Temperature: Temperature of this winding inside the alternator.";
CM_ SG_ 2633753598 EngnAltrntrWndng9Tmprtr "Engine Alternator Winding 9 Temperature: Temperature of this winding inside the alternator.";
CM_ BO_ 2633754622 "SCR Operator Inducement Information 5";
CM_ SG_ 2633754622 Aftrtrtmnt1SCRIntkHghTmprtrTm "Aftertreatment 1 SCR Intake High Temperature Time: Indicates the time the aftertreatment 1 SCR intake temperature is above a manufacturer specified threshold. This is the temperature of engine combustion byproducts entering the SCR in exhaust bank 1....";
CM_ SG_ 2633754622 SCROptIdtEOvdTtAtvtT "SCR Operator Inducement Emergency Override Total Activation Time: The total time duration the SCR Operator Inducement Override Mode (SPN 7342) has been active.Note:  Euro Stage V states this timer can not be reset.";
CM_ BO_ 2633754878 "Aftertreatment System Information 2";
CM_ SG_ 2633754878 AftrtrtmntTtlDslExhstFldUsd "Aftertreatment Total Diesel Exhaust Fluid Used: Total amount of DEF used by aftertreatment device 1 and aftertreatment device 2 over the lifetime of the system.See SPNs 5963 and 5964 for individual device accumulation.";
CM_ SG_ 2633754878 AttttDsExstFdUsdTsOptC "Aftertreatment Diesel Exhaust Fluid Used This Operating Cycle: Total amount of DEF used by aftertreatment device 1 and aftertreatment device 2 over the current operating cycle (from engine start to engine start).  See SPNs 5963 and 5964 for individua...";
CM_ SG_ 2633754878 DEFDosingMode "DEF Dosing Mode : The present operating state of the DEF doser as described by the appropriate regulatory body with the Manufacturer.00h = Off, not dosing01h - Fah = Manufacturer Defined, assign from 1 up or from 250 down.FBh = ReservedFCh = Reserved...";
CM_ SG_ 2633754878 HydrocarbonDoserDutyCycle "Hydrocarbon Doser Duty Cycle: The commanded relative postion of the proportioning valve in the Hydrocarbon (HC) Doser System controlling the delivery of fuel to the aftertreatment system.  This SP does not apply to system designs that employ shuttle ...";
CM_ BO_ 2633755390 "Ethernet 1 Connection Information 1";
CM_ SG_ 2633755390 DefaultGatewayOctet1 "Default Gateway Octet 1: This value is the first of 4 octets in the ECU's configured or assigned Default Gateway IP address.  The Default Gateway IP address is separated into 4 bytes, 1 per octet of the address Byte 1 is the first octet of the addres...";
CM_ SG_ 2633755390 DefaultGatewayOctet2 "Default Gateway Octet 2: This value is the second of 4 octets in the ECU's configured or assigned Default Gateway IP address.  The Default Gateway IP address is separated into 4 bytes, 1 per octet of the address Byte 1 is the first octet of the addre...";
CM_ SG_ 2633755390 DefaultGatewayOctet3 "Default Gateway Octet 3: This value is the third of 4 octets in the ECU's configured or assigned Default Gateway IP address.  The Default Gateway IP address is separated into 4 bytes, 1 per octet of the address Byte 1 is the first octet of the addres...";
CM_ SG_ 2633755390 DefaultGatewayOctet4 "Default Gateway Octet 4: This value is the fourth of 4 octets in the ECU's configured or assigned Default Gateway IP address.  The Default Gateway IP address is separated into 4 bytes, 1 per octet of the address Byte 1 is the first octet of the addre...";
CM_ SG_ 2633755390 DHCPStatus "DHCP Status: DHCP Client Status. This parameter is intended to provide feedback on the status of obtaining an IP address. When no physical link is available and DHCP is enabled, an Error response is appropriate.0000b = Not Configured (static IP)0001b...";
CM_ SG_ 2633755390 EthernetLinkStatus "Ethernet Link Status: Ethernet Link Status. When there is no physical connection, the status shall report 00. 00b = Ethernet Link Down01b = Ethernet Link Up10b = Error11b = Not Supported";
CM_ SG_ 2633755390 IPv4AddressOctet1 "IPv4 Address Octet 1: This value is the first of 4 octets in the ECU's assigned Internet Protocol (IP) address. The address is separated into 4 bytes, 1 per octet of the address. Byte 1 is the first octet of the address. Byte 2 is the second and so f...";
CM_ SG_ 2633755390 IPv4AddressOctet2 "IPv4 Address Octet 2: This value is the second of 4 octets in the ECU's assigned Internet Protocol (IP) address. The address is separated into 4 bytes, 1 per octet of the address. Byte 1 is the first octet of the address. Byte 2 is the second and so ...";
CM_ SG_ 2633755390 IPv4AddressOctet3 "IPv4 Address Octet 3: This value is the third of 4 octets in the ECU's assigned Internet Protocol (IP) address. The address is separated into 4 bytes, 1 per octet of the address. Byte 1 is the first octet of the address. Byte 2 is the second and so f...";
CM_ SG_ 2633755390 IPv4AddressOctet4 "IPv4 Address Octet 4: This value is the fourth of 4 octets in the ECU's assigned Internet Protocol (IP) address. The address is separated into 4 bytes, 1 per octet of the address. Byte 1 is the first octet of the address. Byte 2 is the second and so ...";
CM_ SG_ 2633755390 MACAddressOctet1 "MAC Address Octet 1: This value is the first of 6 octets in the ECU's assigned MAC address. The address is separated into 6 bytes, 1 per octet of the address. Byte 1 is the first octet of the address. Byte 2 is the second and so forth. If the MAC add...";
CM_ SG_ 2633755390 MACAddressOctet2 "MAC Address Octet 2: This value is the second of 6 octets in the ECU's assigned MAC address. The address is separated into 6 bytes, 1 per octet of the address. Byte 1 is the first octet of the address. Byte 2 is the second and so forth. If the MAC ad...";
CM_ SG_ 2633755390 MACAddressOctet3 "MAC Address Octet 3: This value is the third of 6 octets in the ECU's assigned MAC address. The address is separated into 6 bytes, 1 per octet of the address. Byte 1 is the first octet of the address. Byte 2 is the second and so forth. If the MAC add...";
CM_ SG_ 2633755390 MACAddressOctet4 "MAC Address Octet 4: This value is the fourth of 6 octets in the ECU's assigned MAC address. The address is separated into 6 bytes, 1 per octet of the address. Byte 1 is the first octet of the address. Byte 2 is the second and so forth. If the MAC ad...";
CM_ SG_ 2633755390 MACAddressOctet5 "MAC Address Octet 5: This value is the fifth of 6 octets in the ECU's assigned MAC address. The address is separated into 6 bytes, 1 per octet of the address. Byte 1 is the first octet of the address. Byte 2 is the second and so forth. If the MAC add...";
CM_ SG_ 2633755390 MACAddressOctet6 "MAC Address Octet 6: This value is the sixth of 6 octets in the ECU's assigned MAC address. The address is separated into 6 bytes, 1 per octet of the address. Byte 1 is the first octet of the address. Byte 2 is the second and so forth. If the MAC add...";
CM_ SG_ 2633755390 SubnetMaskOctet1 "Subnet Mask Octet 1: This value is the first of 4 octets in the ECU's configured Subnet mask. The subnet mask is separated into 4 bytes, 1 per octet of the mask. Byte 1 is the first octet of the mask. Byte 2 is the second and so forth. If the Subnet ...";
CM_ SG_ 2633755390 SubnetMaskOctet2 "Subnet Mask Octet 2: This value is the second of 4 octets in the ECU's configured Subnet mask. The subnet mask is separated into 4 bytes, 1 per octet of the mask. Byte 1 is the first octet of the mask. Byte 2 is the second and so forth. If the Subnet...";
CM_ SG_ 2633755390 SubnetMaskOctet3 "Subnet Mask Octet 3: This value is the third of 4 octets in the ECU's configured Subnet mask. The subnet mask is separated into 4 bytes, 1 per octet of the mask. Byte 1 is the first octet of the mask. Byte 2 is the second and so forth. If the Subnet ...";
CM_ SG_ 2633755390 SubnetMaskOctet4 "Subnet Mask Octet 4: This value is the fourth of 4 octets in the ECU's configured Subnet mask. The subnet mask is separated into 4 bytes, 1 per octet of the mask. Byte 1 is the first octet of the mask. Byte 2 is the second and so forth. If the Subnet...";
CM_ BO_ 2633764094 "Evaporative Systems";
CM_ SG_ 2633764094 CanisterPurgeValveCommand "Canister Purge Valve Command: The commanded positon of the canister purge valve used to allow fuel vapors from the charcoal canister into the intake manifold.A value of 0 % indicates fully closed, a value of 100 % indicates fully open.";
CM_ SG_ 2633764094 CanisterVentValve "Canister Vent Valve: The state of the canister vent value used to allow fresh air into the charcoal vapor canister.00b = Vent Valve is Closed01b = Vent Valve is Open10b = Error11b = Not Available";
CM_ SG_ 2633764094 GasolineFuelTankPressure "Gasoline Fuel Tank Pressure: The gage pressure of the vapor in the gasoline fuel tank.";
CM_ BO_ 2633764350 "Fire Pump Statistics 1";
CM_ SG_ 2633764350 FirePumpEngagementCycles "Fire Pump Engagement Cycles: Accumulated number of times the fire pump has been engaged.";
CM_ SG_ 2633764350 FirePumpOperationTime "Fire Pump Operation Time: Accumulated time that the fire pump is enaged.";
CM_ BO_ 2633769726 "Electronic Engine Controller 19";
CM_ SG_ 2633769726 EngnExhstFlwRtExtnddRng "Engine Exhaust Flow Rate (Extended Range): Engine Exhaust Flow Rate shall indicate the measured/calculated exhaust gas mass flow upstream of the aftertreatment system.See SPN 6895 for alternative range.";
CM_ SG_ 2633769726 TotalEngineEnergy "Total Engine Energy: The total amount of energy delivered by the engine. It is accumulated over the life of the engine.";
CM_ BO_ 2633773054 "Fire Suppression Agent Status";
CM_ SG_ 2633773054 FireSuppressionWaterTankLevel "Fire Suppression Water Tank Level: Liquid level of the fire apparatus water tank.";
CM_ SG_ 2633773054 FrSpprssnClssAFmTnkLvl "Fire Suppression Class-A Foam Tank Level: Liquid level of the Class-A foam agent tank.";
CM_ SG_ 2633773054 FrSpprssnClssBFmTnkLvl "Fire Suppression Class-B Foam Tank Level: Liquid level of the Class-B foam agent tank.";
CM_ SG_ 2633773054 FrSpprssnCmprssdArFmSstmArPrssr "Fire Suppression Compressed Air Foam System Air Pressure: Compressed Air Foam System (CAFS) air compressor pressure.";
CM_ BO_ 2633773310 "SCR Operator Inducement Information 4";
CM_ SG_ 2633773310 SCROprtrIndmntOvrrdMd "SCR Operator Inducement Override Mode: Indicates the functional mode of SCR operator inducement override.000b = Not Available001b = Available - Not Active010b = Active011b = Active Extended100b = Expired101b to 110b = Not Defined111b = Not AvailableN...";
CM_ SG_ 2633773310 SCROprtrIndmntOvrrdRnwlRqrd "SCR Operator Inducement Override Renewal Required: Indicates the required operator inducement override renewal state.00b = Not Required01b = Required10b = Error11b = Not Available";
CM_ SG_ 2633773310 SCROptIdtEOvdTtRstOs "SCR Operator Inducement Emergency Override Total Reset Occurrences: The total number of times the feature, which allows the operator to override the inducement strategies (as described in SPN 6880) during emergencies, such as hurricanes, has been res...";
CM_ SG_ 2633773310 SCROptIdtOvdTRExtddR "SCR Operator Inducement Override Time Remaining (Extended Range): Used to indicate the time remaining during an operator inducement override event.  When an operator inducement is active this parameter indicates the remaining time that the currently ...";
CM_ BO_ 2633782014 "Bin Weight and Lift Count";
CM_ SG_ 2633782014 BinInstance "Bin Instance: Gives the instance of the bin on the vehicle whose parameters are transmitted in the remainder of the PG, with the first or only bin as instance 1.";
CM_ SG_ 2633782014 BinLiftCount "Bin Lift Count: Increments with each lift, whether or not net bin weight changes.  The count rolls over at data range limit.The count can be reset using SPN 6898 in PGN 56832.";
CM_ SG_ 2633782014 BinWeighingErrorStatus "Bin Weighing Error Status: Bin weighing error status0 = No error1 = Bad lift cycle2 = Weighing error: bin lifted, not emptied3 = Weighing error: empty bin lifted, emptied4 to 14 = Reserved15 = Not available / not applicable";
CM_ SG_ 2633782014 NetBinWeight "Net Bin Weight: Mass of bin contents at most recent unload";
CM_ BO_ 2633785086 "High Voltage Energy Storage System History";
CM_ SG_ 2633785086 HVESSStateofHealth "HVESS State of Health: This signal represents the expected remaining Life of the High Voltage Energy Storage System (or Pack 1 in systems with only one pack), in percent.  Battery life is a manufacturer-specific measure of how well the energy storage...";
CM_ SG_ 2633785086 HVESSCnttrOpnUndrLdCnt "HVESS Contactor Open Under Load Count: This signal represents the number of times the contactors inside the High Voltage Energy Storage System (or Pack 1 in systems with only one pack) have opened while current is flowing through them.  The current l...";
CM_ SG_ 2633785086 HVESSTotalEnergyThroughput "HVESS Total Energy Throughput: The total energy throughput which has flowed through High Voltage Energy Storage System (or Pack 1 in systems with only one pack).  This parameter is the sum of the absolute values of the Energy into and out of this HVE...";
CM_ SG_ 2633785086 HVESSTotalAccumulatedCharge "HVESS Total Accumulated Charge: The total accumulated amp hours which have flowed through High Voltage Energy Storage System (or Pack 1 in systems with only one pack).  This parameter is the sum of the absolute values of the Ampere hours into and out...";
CM_ SG_ 2633785086 HVESSTotalLifetimeEnergyInput "HVESS Total Lifetime Energy Input: The cumulative energy which has flowed into the High Voltage Energy Storage System over the lifetime of the battery system (or Pack 1 in systems with only one pack). In multipack systems this parameter is the sum of...";
CM_ SG_ 2633785086 HVESSTotalLifetimeEnergyOutput "HVESS Total Lifetime Energy Output: The cumulative energy which has flowed out of the High Voltage Energy Storage System over the lifetime of the battery system (or Pack 1 in systems with only one pack). In multipack systems this parameter is the sum...";
CM_ BO_ 2633801982 "Multi-fuel Engine Hours";
CM_ SG_ 2633801982 EngnTtlHrsfDslFlOprtn "Engine Total Hours of Diesel Fuel Operation: Accumulated time of operation of engine when diesel fuel is used.  This parameter should be used only in multi-fuel engines.  See SPN 247 for single fuel engines and for total hours for multi-fuel engines.";
CM_ SG_ 2633801982 EngnTtlHrsfGssFlOprtn "Engine Total Hours of Gaseous Fuel Operation: Accumulated time of operation of engine when gaseous fuel is used.  This parameter should be used only in multi-fuel engines.  See SPN 247 for single fuel engines and for total hours for multi-fuel engine...";
CM_ BO_ 2633802238 "Engine Spark Misfire Rate 3";
CM_ SG_ 2633802238 EngineSparkPlug17MisfireRate "Engine Spark Plug 17 Misfire Rate: The spark misfire rate for Cylinder #17. The misfire rate is conveyed as the percentage of total cylinder spark misfires compared to the total number of ignition events on Cylinder #17 since the last time this track...";
CM_ SG_ 2633802238 EngineSparkPlug18MisfireRate "Engine Spark Plug 18 Misfire Rate: The spark misfire rate for Cylinder #18. The misfire rate is conveyed as the percentage of total cylinder spark misfires compared to the total number of ignition events on Cylinder #18 since the last time this track...";
CM_ SG_ 2633802238 EngineSparkPlug19MisfireRate "Engine Spark Plug 19 Misfire Rate: The spark misfire rate for Cylinder #19. The misfire rate is conveyed as the percentage of total cylinder spark misfires compared to the total number of ignition events on Cylinder #19 since the last time this track...";
CM_ SG_ 2633802238 EngineSparkPlug20MisfireRate "Engine Spark Plug 20 Misfire Rate: The spark misfire rate for Cylinder #20. The misfire rate is conveyed as the percentage of total cylinder spark misfires compared to the total number of ignition events on Cylinder #20 since the last time this track...";
CM_ SG_ 2633802238 EngineSparkPlug21MisfireRate "Engine Spark Plug 21 Misfire Rate: The spark misfire rate for Cylinder #21. The misfire rate is conveyed as the percentage of total cylinder spark misfires compared to the total number of ignition events on Cylinder #21 since the last time this track...";
CM_ SG_ 2633802238 EngineSparkPlug22MisfireRate "Engine Spark Plug 22 Misfire Rate: The spark misfire rate for Cylinder #22. The misfire rate is conveyed as the percentage of total cylinder spark misfires compared to the total number of ignition events on Cylinder #22 since the last time this track...";
CM_ SG_ 2633802238 EngineSparkPlug23MisfireRate "Engine Spark Plug 23 Misfire Rate: The spark misfire rate for Cylinder #23. The misfire rate is conveyed as the percentage of total cylinder spark misfires compared to the total number of ignition events on Cylinder #23 since the last time this track...";
CM_ SG_ 2633802238 EngineSparkPlug24MisfireRate "Engine Spark Plug 24 Misfire Rate: The spark misfire rate for Cylinder #24. The misfire rate is conveyed as the percentage of total cylinder spark misfires compared to the total number of ignition events on Cylinder #24 since the last time this track...";
CM_ BO_ 2633802494 "Engine Spark Misfire Rate 2";
CM_ SG_ 2633802494 EngineSparkPlug10MisfireRate "Engine Spark Plug 10 Misfire Rate: The spark misfire rate for Cylinder #10. The misfire rate is conveyed as the percentage of total cylinder spark misfires compared to the total number of ignition events on Cylinder #10 since the last time this track...";
CM_ SG_ 2633802494 EngineSparkPlug11MisfireRate "Engine Spark Plug 11 Misfire Rate: The spark misfire rate for Cylinder #11. The misfire rate is conveyed as the percentage of total cylinder spark misfires compared to the total number of ignition events on Cylinder #11 since the last time this track...";
CM_ SG_ 2633802494 EngineSparkPlug12MisfireRate "Engine Spark Plug 12 Misfire Rate: The spark misfire rate for Cylinder #12. The misfire rate is conveyed as the percentage of total cylinder spark misfires compared to the total number of ignition events on Cylinder #12 since the last time this track...";
CM_ SG_ 2633802494 EngineSparkPlug13MisfireRate "Engine Spark Plug 13 Misfire Rate: The spark misfire rate for Cylinder #13. The misfire rate is conveyed as the percentage of total cylinder spark misfires compared to the total number of ignition events on Cylinder #13 since the last time this track...";
CM_ SG_ 2633802494 EngineSparkPlug14MisfireRate "Engine Spark Plug 14 Misfire Rate: The spark misfire rate for Cylinder #14. The misfire rate is conveyed as the percentage of total cylinder spark misfires compared to the total number of ignition events on Cylinder #14 since the last time this track...";
CM_ SG_ 2633802494 EngineSparkPlug15MisfireRate "Engine Spark Plug 15 Misfire Rate: The spark misfire rate for Cylinder #15. The misfire rate is conveyed as the percentage of total cylinder spark misfires compared to the total number of ignition events on Cylinder #15 since the last time this track...";
CM_ SG_ 2633802494 EngineSparkPlug16MisfireRate "Engine Spark Plug 16 Misfire Rate: The spark misfire rate for Cylinder #16. The misfire rate is conveyed as the percentage of total cylinder spark misfires compared to the total number of ignition events on Cylinder #16 since the last time this track...";
CM_ SG_ 2633802494 EngineSparkPlug9MisfireRate "Engine Spark Plug 9 Misfire Rate: The spark misfire rate for Cylinder #9. The misfire rate is conveyed as the percentage of total cylinder spark misfires compared to the total number of ignition events on Cylinder #9 since the last time this tracking...";
CM_ BO_ 2633802750 "Engine Spark Misfire Rate 1";
CM_ SG_ 2633802750 EngineSparkPlug1MisfireRate "Engine Spark Plug 1 Misfire Rate: The spark misfire rate for Cylinder #1. The misfire rate is conveyed as the percentage of total cylinder spark misfires compared to the total number of ignition events on Cylinder #1 since the last time this tracking...";
CM_ SG_ 2633802750 EngineSparkPlug2MisfireRate "Engine Spark Plug 2 Misfire Rate: The spark misfire rate for Cylinder #2. The misfire rate is conveyed as the percentage of total cylinder spark misfires compared to the total number of ignition events on Cylinder #2 since the last time this tracking...";
CM_ SG_ 2633802750 EngineSparkPlug3MisfireRate "Engine Spark Plug 3 Misfire Rate: The spark misfire rate for Cylinder #3. The misfire rate is conveyed as the percentage of total cylinder spark misfires compared to the total number of ignition events on Cylinder #3 since the last time this tracking...";
CM_ SG_ 2633802750 EngineSparkPlug4MisfireRate "Engine Spark Plug 4 Misfire Rate: The spark misfire rate for Cylinder #4. The misfire rate is conveyed as the percentage of total cylinder spark misfires compared to the total number of ignition events on Cylinder #4 since the last time this tracking...";
CM_ SG_ 2633802750 EngineSparkPlug5MisfireRate "Engine Spark Plug 5 Misfire Rate: The spark misfire rate for Cylinder #5. The misfire rate is conveyed as the percentage of total cylinder spark misfires compared to the total number of ignition events on Cylinder #5 since the last time this tracking...";
CM_ SG_ 2633802750 EngineSparkPlug6MisfireRate "Engine Spark Plug 6 Misfire Rate: The spark misfire rate for Cylinder #6. The misfire rate is conveyed as the percentage of total cylinder spark misfires compared to the total number of ignition events on Cylinder #6 since the last time this tracking...";
CM_ SG_ 2633802750 EngineSparkPlug7MisfireRate "Engine Spark Plug 7 Misfire Rate: The spark misfire rate for Cylinder #7. The misfire rate is conveyed as the percentage of total cylinder spark misfires compared to the total number of ignition events on Cylinder #7 since the last time this tracking...";
CM_ SG_ 2633802750 EngineSparkPlug8MisfireRate "Engine Spark Plug 8 Misfire Rate: The spark misfire rate for Cylinder #8. The misfire rate is conveyed as the percentage of total cylinder spark misfires compared to the total number of ignition events on Cylinder #8 since the last time this tracking...";
CM_ BO_ 2633803006 "Engine Spark Maximum Voltage 6";
CM_ SG_ 2633803006 EngineSparkPlug21MaximumVoltage "Engine Spark Plug 21 Maximum Voltage: The largest measured spark voltage of all measured spark events on Cylinder #21 since the last time this tracking data was reset.  It is reset using Reset PG (PGN 56832), Engine Spark Plug Secondary Voltage Track...";
CM_ SG_ 2633803006 EngineSparkPlug22MaximumVoltage "Engine Spark Plug 22 Maximum Voltage: The largest measured spark voltage of all measured spark events on Cylinder #22 since the last time this tracking data was reset.  It is reset using Reset PG (PGN 56832), Engine Spark Plug Secondary Voltage Track...";
CM_ SG_ 2633803006 EngineSparkPlug23MaximumVoltage "Engine Spark Plug 23 Maximum Voltage: The largest measured spark voltage of all measured spark events on Cylinder #23 since the last time this tracking data was reset.  It is reset using Reset PG (PGN 56832), Engine Spark Plug Secondary Voltage Track...";
CM_ SG_ 2633803006 EngineSparkPlug24MaximumVoltage "Engine Spark Plug 24 Maximum Voltage: The largest measured spark voltage of all measured spark events on Cylinder #24 since the last time this tracking data was reset.  It is reset using Reset PG (PGN 56832), Engine Spark Plug Secondary Voltage Track...";
CM_ BO_ 2633803262 "Engine Spark Maximum Voltage 5";
CM_ SG_ 2633803262 EngineSparkPlug17MaximumVoltage "Engine Spark Plug 17 Maximum Voltage: The largest measured spark voltage of all measured spark events on Cylinder #17 since the last time this tracking data was reset.  It is reset using Reset PG (PGN 56832), Engine Spark Plug Secondary Voltage Track...";
CM_ SG_ 2633803262 EngineSparkPlug18MaximumVoltage "Engine Spark Plug 18 Maximum Voltage: The largest measured spark voltage of all measured spark events on Cylinder #18 since the last time this tracking data was reset.  It is reset using Reset PG (PGN 56832), Engine Spark Plug Secondary Voltage Track...";
CM_ SG_ 2633803262 EngineSparkPlug19MaximumVoltage "Engine Spark Plug 19 Maximum Voltage: The largest measured spark voltage of all measured spark events on Cylinder #19 since the last time this tracking data was reset.  It is reset using Reset PG (PGN 56832), Engine Spark Plug Secondary Voltage Track...";
CM_ SG_ 2633803262 EngineSparkPlug20MaximumVoltage "Engine Spark Plug 20 Maximum Voltage: The largest measured spark voltage of all measured spark events on Cylinder #20 since the last time this tracking data was reset.  It is reset using Reset PG (PGN 56832), Engine Spark Plug Secondary Voltage Track...";
CM_ BO_ 2633803518 "Engine Spark Maximum Voltage 4";
CM_ SG_ 2633803518 EngineSparkPlug13MaximumVoltage "Engine Spark Plug 13 Maximum Voltage: The largest measured spark voltage of all measured spark events on Cylinder #13 since the last time this tracking data was reset.  It is reset using Reset PG (PGN 56832), Engine Spark Plug Secondary Voltage Track...";
CM_ SG_ 2633803518 EngineSparkPlug14MaximumVoltage "Engine Spark Plug 14 Maximum Voltage: The largest measured spark voltage of all measured spark events on Cylinder #14 since the last time this tracking data was reset.  It is reset using Reset PG (PGN 56832), Engine Spark Plug Secondary Voltage Track...";
CM_ SG_ 2633803518 EngineSparkPlug15MaximumVoltage "Engine Spark Plug 15 Maximum Voltage: The largest measured spark voltage of all measured spark events on Cylinder #15 since the last time this tracking data was reset.  It is reset using Reset PG (PGN 56832), Engine Spark Plug Secondary Voltage Track...";
CM_ SG_ 2633803518 EngineSparkPlug16MaximumVoltage "Engine Spark Plug 16 Maximum Voltage: The largest measured spark voltage of all measured spark events on Cylinder #16 since the last time this tracking data was reset.  It is reset using Reset PG (PGN 56832), Engine Spark Plug Secondary Voltage Track...";
CM_ BO_ 2633803774 "Engine Spark Maximum Voltage 3";
CM_ SG_ 2633803774 EngineSparkPlug10MaximumVoltage "Engine Spark Plug 10 Maximum Voltage: The largest measured spark voltage of all measured spark events on Cylinder #10 since the last time this tracking data was reset.  It is reset using Reset PG (PGN 56832), Engine Spark Plug Secondary Voltage Track...";
CM_ SG_ 2633803774 EngineSparkPlug11MaximumVoltage "Engine Spark Plug 11 Maximum Voltage: The largest measured spark voltage of all measured spark events on Cylinder #11 since the last time this tracking data was reset.  It is reset using Reset PG (PGN 56832), Engine Spark Plug Secondary Voltage Track...";
CM_ SG_ 2633803774 EngineSparkPlug12MaximumVoltage "Engine Spark Plug 12 Maximum Voltage: The largest measured spark voltage of all measured spark events on Cylinder #12 since the last time this tracking data was reset.  It is reset using Reset PG (PGN 56832), Engine Spark Plug Secondary Voltage Track...";
CM_ SG_ 2633803774 EngineSparkPlug9MaximumVoltage "Engine Spark Plug 9 Maximum Voltage: The largest measured spark voltage of all measured spark events on Cylinder #9 since the last time this tracking data was reset.  It is reset using Reset PG (PGN 56832), Engine Spark Plug Secondary Voltage Trackin...";
CM_ BO_ 2633804030 "Engine Spark Maximum Voltage 2";
CM_ SG_ 2633804030 EngineSparkPlug5MaximumVoltage "Engine Spark Plug 5 Maximum Voltage: The largest measured spark voltage of all measured spark events on Cylinder #5 since the last time this tracking data was reset.  It is reset using Reset PG (PGN 56832), Engine Spark Plug Secondary Voltage Trackin...";
CM_ SG_ 2633804030 EngineSparkPlug6MaximumVoltage "Engine Spark Plug 6 Maximum Voltage: The largest measured spark voltage of all measured spark events on Cylinder #6 since the last time this tracking data was reset.  It is reset using Reset PG (PGN 56832), Engine Spark Plug Secondary Voltage Trackin...";
CM_ SG_ 2633804030 EngineSparkPlug7MaximumVoltage "Engine Spark Plug 7 Maximum Voltage: The largest measured spark voltage of all measured spark events on Cylinder #7 since the last time this tracking data was reset.  It is reset using Reset PG (PGN 56832), Engine Spark Plug Secondary Voltage Trackin...";
CM_ SG_ 2633804030 EngineSparkPlug8MaximumVoltage "Engine Spark Plug 8 Maximum Voltage: The largest measured spark voltage of all measured spark events on Cylinder #8 since the last time this tracking data was reset.  It is reset using Reset PG (PGN 56832), Engine Spark Plug Secondary Voltage Trackin...";
CM_ BO_ 2633804286 "Engine Spark Maximum Voltage 1";
CM_ SG_ 2633804286 EngineSparkPlug1MaximumVoltage "Engine Spark Plug 1 Maximum Voltage: The largest measured spark voltage of all measured spark events on Cylinder #1 since the last time this tracking data was reset.  It is reset using Reset PG (PGN 56832), Engine Spark Plug Secondary Voltage Trackin...";
CM_ SG_ 2633804286 EngineSparkPlug2MaximumVoltage "Engine Spark Plug 2 Maximum Voltage: The largest measured spark voltage of all measured spark events on Cylinder #2 since the last time this tracking data was reset.  It is reset using Reset PG (PGN 56832), Engine Spark Plug Secondary Voltage Trackin...";
CM_ SG_ 2633804286 EngineSparkPlug3MaximumVoltage "Engine Spark Plug 3 Maximum Voltage: The largest measured spark voltage of all measured spark events on Cylinder #3 since the last time this tracking data was reset.  It is reset using Reset PG (PGN 56832), Engine Spark Plug Secondary Voltage Trackin...";
CM_ SG_ 2633804286 EngineSparkPlug4MaximumVoltage "Engine Spark Plug 4 Maximum Voltage: The largest measured spark voltage of all measured spark events on Cylinder #4 since the last time this tracking data was reset.  It is reset using Reset PG (PGN 56832), Engine Spark Plug Secondary Voltage Trackin...";
CM_ BO_ 2633804542 "Engine Spark Minimum Voltage 6";
CM_ SG_ 2633804542 EngineSparkPlug21MinimumVoltage "Engine Spark Plug 21 Minimum Voltage: The smallest measured spark voltage of all measured spark events on Cylinder #21 since the last time this tracking data was reset.  It is reset using Reset PG (PGN 56832), Engine Spark Plug Secondary Voltage Trac...";
CM_ SG_ 2633804542 EngineSparkPlug22MinimumVoltage "Engine Spark Plug 22 Minimum Voltage: The smallest measured spark voltage of all measured spark events on Cylinder #22 since the last time this tracking data was reset.  It is reset using Reset PG (PGN 56832), Engine Spark Plug Secondary Voltage Trac...";
CM_ SG_ 2633804542 EngineSparkPlug23MinimumVoltage "Engine Spark Plug 23 Minimum Voltage: The smallest measured spark voltage of all measured spark events on Cylinder #23 since the last time this tracking data was reset.  It is reset using Reset PG (PGN 56832), Engine Spark Plug Secondary Voltage Trac...";
CM_ SG_ 2633804542 EngineSparkPlug24MinimumVoltage "Engine Spark Plug 24 Minimum Voltage: The smallest measured spark voltage of all measured spark events on Cylinder #24 since the last time this tracking data was reset.  It is reset using Reset PG (PGN 56832), Engine Spark Plug Secondary Voltage Trac...";
CM_ BO_ 2633804798 "Engine Spark Minimum Voltage 5";
CM_ SG_ 2633804798 EngineSparkPlug17MinimumVoltage "Engine Spark Plug 17 Minimum Voltage: The smallest measured spark voltage of all measured spark events on Cylinder #17 since the last time this tracking data was reset.  It is reset using Reset PG (PGN 56832), Engine Spark Plug Secondary Voltage Trac...";
CM_ SG_ 2633804798 EngineSparkPlug18MinimumVoltage "Engine Spark Plug 18 Minimum Voltage: The smallest measured spark voltage of all measured spark events on Cylinder #18 since the last time this tracking data was reset.  It is reset using Reset PG (PGN 56832), Engine Spark Plug Secondary Voltage Trac...";
CM_ SG_ 2633804798 EngineSparkPlug19MinimumVoltage "Engine Spark Plug 19 Minimum Voltage: The smallest measured spark voltage of all measured spark events on Cylinder #19 since the last time this tracking data was reset.  It is reset using Reset PG (PGN 56832), Engine Spark Plug Secondary Voltage Trac...";
CM_ SG_ 2633804798 EngineSparkPlug20MinimumVoltage "Engine Spark Plug 20 Minimum Voltage: The smallest measured spark voltage of all measured spark events on Cylinder #20 since the last time this tracking data was reset.  It is reset using Reset PG (PGN 56832), Engine Spark Plug Secondary Voltage Trac...";
CM_ BO_ 2633805054 "Engine Spark Minimum Voltage 4";
CM_ SG_ 2633805054 EngineSparkPlug13MinimumVoltage "Engine Spark Plug 13 Minimum Voltage: The smallest measured spark voltage of all measured spark events on Cylinder #13 since the last time this tracking data was reset.  It is reset using Reset PG (PGN 56832), Engine Spark Plug Secondary Voltage Trac...";
CM_ SG_ 2633805054 EngineSparkPlug14MinimumVoltage "Engine Spark Plug 14 Minimum Voltage: The smallest measured spark voltage of all measured spark events on Cylinder #14 since the last time this tracking data was reset.  It is reset using Reset PG (PGN 56832), Engine Spark Plug Secondary Voltage Trac...";
CM_ SG_ 2633805054 EngineSparkPlug15MinimumVoltage "Engine Spark Plug 15 Minimum Voltage: The smallest measured spark voltage of all measured spark events on Cylinder #15 since the last time this tracking data was reset.  It is reset using Reset PG (PGN 56832), Engine Spark Plug Secondary Voltage Trac...";
CM_ SG_ 2633805054 EngineSparkPlug16MinimumVoltage "Engine Spark Plug 16 Minimum Voltage: The smallest measured spark voltage of all measured spark events on Cylinder #16 since the last time this tracking data was reset.  It is reset using Reset PG (PGN 56832), Engine Spark Plug Secondary Voltage Trac...";
CM_ BO_ 2633805310 "Engine Spark Minimum Voltage 3";
CM_ SG_ 2633805310 EngineSparkPlug10MinimumVoltage "Engine Spark Plug 10 Minimum Voltage: The smallest measured spark voltage of all measured spark events on Cylinder #10 since the last time this tracking data was reset.  It is reset using Reset PG (PGN 56832), Engine Spark Plug Secondary Voltage Trac...";
CM_ SG_ 2633805310 EngineSparkPlug11MinimumVoltage "Engine Spark Plug 11 Minimum Voltage: The smallest measured spark voltage of all measured spark events on Cylinder #11 since the last time this tracking data was reset.  It is reset using Reset PG (PGN 56832), Engine Spark Plug Secondary Voltage Trac...";
CM_ SG_ 2633805310 EngineSparkPlug12MinimumVoltage "Engine Spark Plug 12 Minimum Voltage: The smallest measured spark voltage of all measured spark events on Cylinder #12 since the last time this tracking data was reset.  It is reset using Reset PG (PGN 56832), Engine Spark Plug Secondary Voltage Trac...";
CM_ SG_ 2633805310 EngineSparkPlug9MinimumVoltage "Engine Spark Plug 9 Minimum Voltage: The smallest measured spark voltage of all measured spark events on Cylinder #9 since the last time this tracking data was reset.  It is reset using Reset PG (PGN 56832), Engine Spark Plug Secondary Voltage Tracki...";
CM_ BO_ 2633805566 "Engine Spark Minimum Voltage 2";
CM_ SG_ 2633805566 EngineSparkPlug5MinimumVoltage "Engine Spark Plug 5 Minimum Voltage: The smallest measured spark voltage of all measured spark events on Cylinder #5 since the last time this tracking data was reset.  It is reset using Reset PG (PGN 56832), Engine Spark Plug Secondary Voltage Tracki...";
CM_ SG_ 2633805566 EngineSparkPlug6MinimumVoltage "Engine Spark Plug 6 Minimum Voltage: The smallest measured spark voltage of all measured spark events on Cylinder #6 since the last time this tracking data was reset.  It is reset using Reset PG (PGN 56832), Engine Spark Plug Secondary Voltage Tracki...";
CM_ SG_ 2633805566 EngineSparkPlug7MinimumVoltage "Engine Spark Plug 7 Minimum Voltage: The smallest measured spark voltage of all measured spark events on Cylinder #7 since the last time this tracking data was reset.  It is reset using Reset PG (PGN 56832), Engine Spark Plug Secondary Voltage Tracki...";
CM_ SG_ 2633805566 EngineSparkPlug8MinimumVoltage "Engine Spark Plug 8 Minimum Voltage: The smallest measured spark voltage of all measured spark events on Cylinder #8 since the last time this tracking data was reset.  It is reset using Reset PG (PGN 56832), Engine Spark Plug Secondary Voltage Tracki...";
CM_ BO_ 2633805822 "Engine Spark Minimum Voltage 1";
CM_ SG_ 2633805822 EngineSparkPlug1MinimumVoltage "Engine Spark Plug 1 Minimum Voltage: The smallest measured spark voltage of all measured spark events on Cylinder #1 since the last time this tracking data was reset.  It is reset using Reset PG (PGN 56832), Engine Spark Plug Secondary Voltage Tracki...";
CM_ SG_ 2633805822 EngineSparkPlug2MinimumVoltage "Engine Spark Plug 2 Minimum Voltage: The smallest measured spark voltage of all measured spark events on Cylinder #2 since the last time this tracking data was reset.  It is reset using Reset PG (PGN 56832), Engine Spark Plug Secondary Voltage Tracki...";
CM_ SG_ 2633805822 EngineSparkPlug3MinimumVoltage "Engine Spark Plug 3 Minimum Voltage: The smallest measured spark voltage of all measured spark events on Cylinder #3 since the last time this tracking data was reset.  It is reset using Reset PG (PGN 56832), Engine Spark Plug Secondary Voltage Tracki...";
CM_ SG_ 2633805822 EngineSparkPlug4MinimumVoltage "Engine Spark Plug 4 Minimum Voltage: The smallest measured spark voltage of all measured spark events on Cylinder #4 since the last time this tracking data was reset.  It is reset using Reset PG (PGN 56832), Engine Spark Plug Secondary Voltage Tracki...";
CM_ BO_ 2633806078 "Engine Ignition Controller Maintenance Hours";
CM_ SG_ 2633806078 EngnIgntnCntrlMdl1TmRmnng "Engine Ignition Control Module 1 Time Remaining: This parameter reports the time remaining before maintenance should be performed on engine ignition control module instance 1.  Upon maintenance, the time is reset to its starting value using Reset PG ...";
CM_ SG_ 2633806078 EngnIgntnCntrlMdl2TmRmnng "Engine Ignition Control Module 2 Time Remaining: This parameter reports the time remaining before maintenance should be performed on engine ignition control module instance 2.  Upon maintenance, the time is reset to its starting value using Reset PG ...";
CM_ BO_ 2633825022 "Electronic Engine Controller 11";
CM_ SG_ 2633825022 EngnExhstGsRrltn2Vlv1Cntrl "Engine Exhaust Gas Recirculation 2 Valve 1 Control: Desired percentage of maximum Exhaust Gas Recirculation 2 (EGR2) valve opening. 0% means the valve is closed. 100% means maximum opening (full gas flow).";
CM_ SG_ 2633825022 EngnExhstGsRrltn2Vlv1PstnErrr "Engine Exhaust Gas Recirculation 2 Valve 1 Position Error: The position error of the Exhaust Gas Recirculation 2 valve, determined as the actual position (SPN 5264) minus the commanded position (SPN 5262).";
CM_ SG_ 2633825022 EngnExhstGsRrltn2Vlv2Cntrl "Engine Exhaust Gas Recirculation 2 Valve 2 Control: Desired percentage of maximum Exhaust Gas Recirculation 2 (EGR2) valve 2 opening. 0% means the valve is closed. 100% means maximum opening (full gas flow).";
CM_ SG_ 2633825022 EngnExhstGsRrltn2Vlv2PstnErrr "Engine Exhaust Gas Recirculation 2 Valve 2 Position Error: The position error of the Exhaust Gas Recirculation 2 valve 2, determined as the actual position (SPN 5265) minus the commanded position (SPN 5263).";
CM_ BO_ 2633825534 "Engine Manifold Actuator Control";
CM_ SG_ 2633825534 EExstMdB1FwBVvAttCt "Engine Exhaust Manifold Bank 1 Flow Balance Valve Actuator Control: Commanded percentage of maximum Engine Exhaust Manifold Bank 1 Balance valve opening. 0% means valve is closed. 100% means maximum valve opening (full gas flow).";
CM_ SG_ 2633825534 EExstMdB2FwBVvAttCt "Engine Exhaust Manifold Bank 2 Flow Balance Valve Actuator Control: Commanded percentage of maximum Engine Ehaust Manifold Bank 2 Balance valve opening. 0% means valve is closed. 100% means maximum valve opening (full gas flow).";
CM_ BO_ 2633826046 "Electronic Engine Controller 10";
CM_ SG_ 2633826046 EExstGsRt2CBpssAttPst "Engine Exhaust Gas Recirculation 2 Cooler Bypass Actuator Position: EGR2 Cooler Bypass Actuator position, where 0% = Fully Closed (no gas flowing through the bypass), and 100% = Fully Open..";
CM_ SG_ 2633826046 EExstGsRt2CItGsAstPss "Engine Exhaust Gas Recirculation 2 Cooler Intake Gas Absolute Pressure: Exhaust Gas Recirculation 2 gas absolute pressure is measured at EGR2 cooler intake. See SPN 5253 for EGR2 pressure measured at the EGR2 cooler outlet before the valve.";
CM_ SG_ 2633826046 EngnExhstGsRrltn2ClrEffn "Engine Exhaust Gas Recirculation 2 Cooler Efficiency: Exhaust Gas Recirculation 2 cooler efficiency is an indication of the cooler’s ability to reduce the temperature of the exhaust gas that is being recirculated back to the intake. 0% = no reduction...";
CM_ SG_ 2633826046 EngnExhstGsRrltn2ClrIntkPrssr "Engine Exhaust Gas Recirculation 2 Cooler Intake Pressure: Exhaust gas recirculation 2 (EGR2) gage pressure is measured at the EGR2 cooler intake.";
CM_ SG_ 2633826046 EngnExhstGsRrltn2ClrIntkTmprtr "Engine Exhaust Gas Recirculation 2 Cooler Intake Temperature: Exhaust Gas Recirculation 2 (EGR2) Temperature measured at EGR2 cooler intake. See SPN 5255 for Engine EGR2 temperature.";
CM_ BO_ 2633828606 "Engine oil message";
CM_ SG_ 2633828606 EngineOilDensity "Engine Oil Density: Density of the engine oil";
CM_ SG_ 2633828606 EngineOilTemperature3 "Engine Oil Temperature 3: Temperature of the engine lubricant.Note:  If there is only one engine oil temperature measurement, SPN 175 should be used. See also SPNs 175 and 1135 for additional engine oil temperature measurements.";
CM_ SG_ 2633828606 EngineOilViscosity "Engine Oil Viscosity: Dynamic viscosity of the engine oil";
CM_ SG_ 2633828606 EngnOlRltvDltrtHghRsltn "Engine Oil Relative Dielectricity (High Resolution): Engine oil relative dielectricity used to describe the engine oil quality.";
CM_ BO_ 2633832702 "Collision Sensor Information";
CM_ SG_ 2633832702 FrontalCollisionSensor1Type "Frontal Collision Sensor 1 - Type: Type of Frontal Collision Sensor 1.0000b = acceleration sensor0001b = pressure sensor0010b = rollrate sensor0011b = sonic sensor0100b = fiber-optic sensor0101b = radar sensor0110b = lidar sensor0111b = optical senso...";
CM_ SG_ 2633832702 FrontalCollisionSensor2Type "Frontal Collision Sensor 2 - Type: Type of Frontal Collision Sensor 2.0000b = acceleration sensor0001b = pressure sensor0010b = rollrate sensor0011b = sonic sensor0100b = fiber-optic sensor0101b = radar sensor0110b = lidar sensor0111b = optical senso...";
CM_ SG_ 2633832702 FrontalCollisionSensor3Type "Frontal Collision Sensor 3 - Type: Type of Frontal Collision Sensor 3.0000b = acceleration sensor0001b = pressure sensor0010b = rollrate sensor0011b = sonic sensor0100b = fiber-optic sensor0101b = radar sensor0110b = lidar sensor0111b = optical senso...";
CM_ SG_ 2633832702 FrontalCollisionSensor4Type "Frontal Collision Sensor 4 - Type: Type of Frontal Collision Sensor 4.0000b = acceleration sensor0001b = pressure sensor0010b = rollrate sensor0011b = sonic sensor0100b = fiber-optic sensor0101b = radar sensor0110b = lidar sensor0111b = optical senso...";
CM_ SG_ 2633832702 RearCollisionSensor1Type "Rear Collision Sensor 1 - Type: Type of Rear Collision Sensor 1.0000b = acceleration sensor0001b = pressure sensor0010b = rollrate sensor0011b = sonic sensor0100b = fiber-optic sensor0101b = radar sensor0110b = lidar sensor0111b = optical sensor1000b...";
CM_ SG_ 2633832702 RearCollisionSensor2Type "Rear Collision Sensor 2 - Type: Type of Rear Collision Sensor 2.0000b = acceleration sensor0001b = pressure sensor0010b = rollrate sensor0011b = sonic sensor0100b = fiber-optic sensor0101b = radar sensor0110b = lidar sensor0111b = optical sensor1000b...";
CM_ SG_ 2633832702 RearCollisionSensor3Type "Rear Collision Sensor 3 - Type: Type of Rear Collision Sensor 3.0000b = acceleration sensor0001b = pressure sensor0010b = rollrate sensor0011b = sonic sensor0100b = fiber-optic sensor0101b = radar sensor0110b = lidar sensor0111b = optical sensor1000b...";
CM_ SG_ 2633832702 RearCollisionSensor4Type "Rear Collision Sensor 4 - Type: Type of Rear Collision Sensor 4.0000b = acceleration sensor0001b = pressure sensor0010b = rollrate sensor0011b = sonic sensor0100b = fiber-optic sensor0101b = radar sensor0110b = lidar sensor0111b = optical sensor1000b...";
CM_ SG_ 2633832702 SdCllsnSnsrFrntLftTp "Side Collision Sensor Front Left - Type: Type of Side Collision Sensor Front - Left.0000b = acceleration sensor0001b = pressure sensor0010b = rollrate sensor0011b = sonic sensor0100b = fiber-optic sensor0101b = radar sensor0110b = lidar sensor0111b =...";
CM_ SG_ 2633832702 SdCllsnSnsrFrntRghtTp "Side Collision Sensor Front Right - Type: Type of Side Collision Sensor Front - Right.0000b = acceleration sensor0001b = pressure sensor0010b = rollrate sensor0011b = sonic sensor0100b = fiber-optic sensor0101b = radar sensor0110b = lidar sensor0111b...";
CM_ SG_ 2633832702 SdCllsnSnsrMdFrntLftTp "Side Collision Sensor Mid Front Left - Type: Type of Side Collision Sensor Mid Front - Left.0000b = acceleration sensor0001b = pressure sensor0010b = rollrate sensor0011b = sonic sensor0100b = fiber-optic sensor0101b = radar sensor0110b = lidar senso...";
CM_ SG_ 2633832702 SdCllsnSnsrMdFrntRghtTp "Side Collision Sensor Mid Front Right - Type: Type of Side Collision Sensor Mid Front - Right.0000b = acceleration sensor0001b = pressure sensor0010b = rollrate sensor0011b = sonic sensor0100b = fiber-optic sensor0101b = radar sensor0110b = lidar sen...";
CM_ SG_ 2633832702 SdCllsnSnsrMdRrLftTp "Side Collision Sensor Mid Rear Left - Type: Type of Side Collision Sensor Mid Rear - Left.0000b = acceleration sensor0001b = pressure sensor0010b = rollrate sensor0011b = sonic sensor0100b = fiber-optic sensor0101b = radar sensor0110b = lidar sensor0...";
CM_ SG_ 2633832702 SdCllsnSnsrMdRrRghtTp "Side Collision Sensor Mid Rear Right - Type: Type of Side Collision Sensor Mid Rear - Right.0000b = acceleration sensor0001b = pressure sensor0010b = rollrate sensor0011b = sonic sensor0100b = fiber-optic sensor0101b = radar sensor0110b = lidar senso...";
CM_ SG_ 2633832702 SdCllsnSnsrRrRghtTp "Side Collision Sensor Rear Right - Type: Type of Side Collision Sensor Rear - Right.0000b = acceleration sensor0001b = pressure sensor0010b = rollrate sensor0011b = sonic sensor0100b = fiber-optic sensor0101b = radar sensor0110b = lidar sensor0111b =...";
CM_ SG_ 2633832702 SideCollisionSensorRearLeftType "Side Collision Sensor Rear Left - Type: Type of Side Collision Sensor Rear - Left.0000b = acceleration sensor0001b = pressure sensor0010b = rollrate sensor0011b = sonic sensor0100b = fiber-optic sensor0101b = radar sensor0110b = lidar sensor0111b = o...";
CM_ BO_ 2633832958 "Ignitor Loop Information";
CM_ SG_ 2633832958 DrvrArgIgntrLp1stStgRsstn "Driver Airbag Ignitor Loop 1st Stage - Resistance: Resistance of Driver Airbag Ignitor Loop 1st Stage.";
CM_ SG_ 2633832958 DrvrArgIgntrLp2ndStgRsstn "Driver Airbag Ignitor Loop 2nd Stage - Resistance: Resistance of Driver Airbag Ignitor Loop 2nd Stage.";
CM_ SG_ 2633832958 DrvrBltTnsnrIgntrLpRsstn "Driver Belt Tensioner Ignitior Loop - Resistance: Resistance of Driver Belt Tensioner Ignitor Loop 1st Stage.";
CM_ SG_ 2633832958 PssngrArgIgntrLp1stStgRsstn "Passenger Airbag Ignitor Loop 1st Stage - Resistance: Resistance of Passenger Airbag Ignitor Loop 1st Stage.";
CM_ SG_ 2633832958 PssngrArgIgntrLp2ndStgRsstn "Passenger Airbag Ignitor Loop 2nd Stage - Resistance: Resistance of Passenger Airbag Ignitor Loop 2nd Stage.";
CM_ SG_ 2633832958 PssngrBltTnsnrIgntrLpRsstn "Passenger Belt Tensioner Ignitor Loop - Resistance: Resistance of Passenger Belt Tensioner Ignitor Loop 1st Stage.";
CM_ SG_ 2633832958 SdBgIgntrLp1LftRsstn "Side Bag Ignitor Loop 1 - Left - Resistance: Resistance of Side Bag Ignitor Loop 1 - Left.";
CM_ SG_ 2633832958 SdBgIgntrLp1RghtRsstn "Side Bag Ignitor Loop 1 - Right - Resistance: Resistance of Side Bag Ignitor Loop 1 - Right.";
CM_ SG_ 2633832958 SdBgIgntrLp2LftRsstn "Side Bag Ignitor Loop 2 - Left - Resistance: Resistance of Side Bag Ignitor Loop 2 - Left.";
CM_ SG_ 2633832958 SdBgIgntrLp2RghtRsstn "Side Bag Ignitor Loop 2 - Right - Resistance: Resistance of Side Bag Ignitor Loop 2 - Right.";
CM_ SG_ 2633832958 SpecialIgnitorLoop10Resistance "Special Ignitor Loop 10 - Resistance: Resistance of Special Ignitor Loop 10.   Since there are many different vehicle types (e.g. truck, bus, firetruck or ambulance), the ignitor loop configuration has a wide variation. ";
CM_ SG_ 2633832958 SpecialIgnitorLoop11Resistance "Special Ignitor Loop 11 - Resistance: Resistance of Special Ignitor Loop 11.   Since there are many different vehicle types (e.g. truck, bus, firetruck or ambulance), the ignitor loop configuration has a wide variation. ";
CM_ SG_ 2633832958 SpecialIgnitorLoop12Resistance "Special Ignitor Loop 12 - Resistance: Resistance of Special Ignitor Loop 12.   Since there are many different vehicle types (e.g. truck, bus, firetruck or ambulance), the ignitor loop configuration has a wide variation. ";
CM_ SG_ 2633832958 SpecialIgnitorLoop13Resistance "Special Ignitor Loop 13 - Resistance: Resistance of Special Ignitor Loop 13.   Since there are many different vehicle types (e.g. truck, bus, firetruck or ambulance), the ignitor loop configuration has a wide variation. ";
CM_ SG_ 2633832958 SpecialIgnitorLoop14Resistance "Special Ignitor Loop 14 - Resistance: Resistance of Special Ignitor Loop 14.   Since there are many different vehicle types (e.g. truck, bus, firetruck or ambulance), the ignitor loop configuration has a wide variation. ";
CM_ SG_ 2633832958 SpecialIgnitorLoop15Resistance "Special Ignitor Loop 15 - Resistance: Resistance of Special Ignitor Loop 15.   Since there are many different vehicle types (e.g. truck, bus, firetruck or ambulance), the ignitor loop configuration has a wide variation. ";
CM_ SG_ 2633832958 SpecialIgnitorLoop16Resistance "Special Ignitor Loop 16 - Resistance: Resistance of Special Ignitor Loop 16.   Since there are many different vehicle types (e.g. truck, bus, firetruck or ambulance), the ignitor loop configuration has a wide variation. ";
CM_ SG_ 2633832958 SpecialIgnitorLoop17Resistance "Special Ignitor Loop 17 - Resistance: Resistance of Special Ignitor Loop 17.   Since there are many different vehicle types (e.g. truck, bus, firetruck or ambulance), the ignitor loop configuration has a wide variation. ";
CM_ SG_ 2633832958 SpecialIgnitorLoop18Resistance "Special Ignitor Loop 18 - Resistance: Resistance of Special Ignitor Loop 18.   Since there are many different vehicle types (e.g. truck, bus, firetruck or ambulance), the ignitor loop configuration has a wide variation. ";
CM_ SG_ 2633832958 SpecialIgnitorLoop19Resistance "Special Ignitor Loop 19 - Resistance: Resistance of Special Ignitor Loop 19.   Since there are many different vehicle types (e.g. truck, bus, firetruck or ambulance), the ignitor loop configuration has a wide variation. ";
CM_ SG_ 2633832958 SpecialIgnitorLoop1Resistance "Special Ignitor Loop 1 - Resistance: Resistance of Special Ignitor Loop 1.   Since there are many different vehicle types (e.g. truck, bus, firetruck or ambulance), the ignitor loop configuration has a wide variation.";
CM_ SG_ 2633832958 SpecialIgnitorLoop20Resistance "Special Ignitor Loop 20 - Resistance: Resistance of Special Ignitor Loop 20.   Since there are many different vehicle types (e.g. truck, bus, firetruck or ambulance), the ignitor loop configuration has a wide variation. ";
CM_ SG_ 2633832958 SpecialIgnitorLoop21Resistance "Special Ignitor Loop 21 - Resistance: Resistance of Special Ignitor Loop 21.   Since there are many different vehicle types (e.g. truck, bus, firetruck or ambulance), the ignitor loop configuration has a wide variation. ";
CM_ SG_ 2633832958 SpecialIgnitorLoop22Resistance "Special Ignitor Loop 22 - Resistance: Resistance of Special Ignitor Loop 22.   Since there are many different vehicle types (e.g. truck, bus, firetruck or ambulance), the ignitor loop configuration has a wide variation. ";
CM_ SG_ 2633832958 SpecialIgnitorLoop23Resistance "Special Ignitor Loop 23 - Resistance: Resistance of Special Ignitor Loop 23.   Since there are many different vehicle types (e.g. truck, bus, firetruck or ambulance), the ignitor loop configuration has a wide variation. ";
CM_ SG_ 2633832958 SpecialIgnitorLoop24Resistance "Special Ignitor Loop 24 - Resistance: Resistance of Special Ignitor Loop 24.   Since there are many different vehicle types (e.g. truck, bus, firetruck or ambulance), the ignitor loop configuration has a wide variation. ";
CM_ SG_ 2633832958 SpecialIgnitorLoop25Resistance "Special Ignitor Loop 25 - Resistance: Resistance of Special Ignitor Loop 25.   Since there are many different vehicle types (e.g. truck, bus, firetruck or ambulance), the ignitor loop configuration has a wide variation. ";
CM_ SG_ 2633832958 SpecialIgnitorLoop26Resistance "Special Ignitor Loop 26 - Resistance: Resistance of Special Ignitor Loop 26.   Since there are many different vehicle types (e.g. truck, bus, firetruck or ambulance), the ignitor loop configuration has a wide variation. ";
CM_ SG_ 2633832958 SpecialIgnitorLoop27Resistance "Special Ignitor Loop 27 - Resistance: Resistance of Special Ignitor Loop 27.   Since there are many different vehicle types (e.g. truck, bus, firetruck or ambulance), the ignitor loop configuration has a wide variation. ";
CM_ SG_ 2633832958 SpecialIgnitorLoop28Resistance "Special Ignitor Loop 28 - Resistance: Resistance of Special Ignitor Loop 28.   Since there are many different vehicle types (e.g. truck, bus, firetruck or ambulance), the ignitor loop configuration has a wide variation. ";
CM_ SG_ 2633832958 SpecialIgnitorLoop29Resistance "Special Ignitor Loop 29 - Resistance: Resistance of Special Ignitor Loop 29.   Since there are many different vehicle types (e.g. truck, bus, firetruck or ambulance), the ignitor loop configuration has a wide variation. ";
CM_ SG_ 2633832958 SpecialIgnitorLoop2Resistance "Special Ignitor Loop 2 - Resistance: Resistance of Special Ignitor Loop 2.   Since there are many different vehicle types (e.g. truck, bus, firetruck or ambulance), the ignitor loop configuration has a wide variation. ";
CM_ SG_ 2633832958 SpecialIgnitorLoop30Resistance "Special Ignitor Loop 30 - Resistance: Resistance of Special Ignitor Loop 30.   Since there are many different vehicle types (e.g. truck, bus, firetruck or ambulance), the ignitor loop configuration has a wide variation. ";
CM_ SG_ 2633832958 SpecialIgnitorLoop31Resistance "Special Ignitor Loop 31 - Resistance: Resistance of Special Ignitor Loop 31.   Since there are many different vehicle types (e.g. truck, bus, firetruck or ambulance), the ignitor loop configuration has a wide variation. ";
CM_ SG_ 2633832958 SpecialIgnitorLoop32Resistance "Special Ignitor Loop 32 - Resistance: Resistance of Special Ignitor Loop 32.   Since there are many different vehicle types (e.g. truck, bus, firetruck or ambulance), the ignitor loop configuration has a wide variation. ";
CM_ SG_ 2633832958 SpecialIgnitorLoop33Resistance "Special Ignitor Loop 33 - Resistance: Resistance of Special Ignitor Loop 33.   Since there are many different vehicle types (e.g. truck, bus, firetruck or ambulance), the ignitor loop configuration has a wide variation. ";
CM_ SG_ 2633832958 SpecialIgnitorLoop34Resistance "Special Ignitor Loop 34 - Resistance: Resistance of Special Ignitor Loop 34.   Since there are many different vehicle types (e.g. truck, bus, firetruck or ambulance), the ignitor loop configuration has a wide variation. ";
CM_ SG_ 2633832958 SpecialIgnitorLoop35Resistance "Special Ignitor Loop 35 - Resistance: Resistance of Special Ignitor Loop 35.   Since there are many different vehicle types (e.g. truck, bus, firetruck or ambulance), the ignitor loop configuration has a wide variation. ";
CM_ SG_ 2633832958 SpecialIgnitorLoop36Resistance "Special Ignitor Loop 36 - Resistance: Resistance of Special Ignitor Loop 36.   Since there are many different vehicle types (e.g. truck, bus, firetruck or ambulance), the ignitor loop configuration has a wide variation. ";
CM_ SG_ 2633832958 SpecialIgnitorLoop37Resistance "Special Ignitor Loop 37 - Resistance: Resistance of Special Ignitor Loop 37.   Since there are many different vehicle types (e.g. truck, bus, firetruck or ambulance), the ignitor loop configuration has a wide variation. ";
CM_ SG_ 2633832958 SpecialIgnitorLoop38Resistance "Special Ignitor Loop 38 - Resistance: Resistance of Special Ignitor Loop 38.   Since there are many different vehicle types (e.g. truck, bus, firetruck or ambulance), the ignitor loop configuration has a wide variation. ";
CM_ SG_ 2633832958 SpecialIgnitorLoop39Resistance "Special Ignitor Loop 39 - Resistance: Resistance of Special Ignitor Loop 39.   Since there are many different vehicle types (e.g. truck, bus, firetruck or ambulance), the ignitor loop configuration has a wide variation. ";
CM_ SG_ 2633832958 SpecialIgnitorLoop3Resistance "Special Ignitor Loop 3 - Resistance: Resistance of Special Ignitor Loop 3.   Since there are many different vehicle types (e.g. truck, bus, firetruck or ambulance), the ignitor loop configuration has a wide variation. ";
CM_ SG_ 2633832958 SpecialIgnitorLoop40Resistance "Special Ignitor Loop 40 - Resistance: Resistance of Special Ignitor Loop 40.   Since there are many different vehicle types (e.g. truck, bus, firetruck or ambulance), the ignitor loop configuration has a wide variation. ";
CM_ SG_ 2633832958 SpecialIgnitorLoop41Resistance "Special Ignitor Loop 41 - Resistance: Resistance of Special Ignitor Loop 41.   Since there are many different vehicle types (e.g. truck, bus, firetruck or ambulance), the ignitor loop configuration has a wide variation. ";
CM_ SG_ 2633832958 SpecialIgnitorLoop42Resistance "Special Ignitor Loop 42 - Resistance: Resistance of Special Ignitor Loop 42.   Since there are many different vehicle types (e.g. truck, bus, firetruck or ambulance), the ignitor loop configuration has a wide variation. ";
CM_ SG_ 2633832958 SpecialIgnitorLoop43Resistance "Special Ignitor Loop 43 - Resistance: Resistance of Special Ignitor Loop 43.   Since there are many different vehicle types (e.g. truck, bus, firetruck or ambulance), the ignitor loop configuration has a wide variation. ";
CM_ SG_ 2633832958 SpecialIgnitorLoop44Resistance "Special Ignitor Loop 44 - Resistance: Resistance of Special Ignitor Loop 44.   Since there are many different vehicle types (e.g. truck, bus, firetruck or ambulance), the ignitor loop configuration has a wide variation. ";
CM_ SG_ 2633832958 SpecialIgnitorLoop45Resistance "Special Ignitor Loop 45 - Resistance: Resistance of Special Ignitor Loop 45.   Since there are many different vehicle types (e.g. truck, bus, firetruck or ambulance), the ignitor loop configuration has a wide variation. ";
CM_ SG_ 2633832958 SpecialIgnitorLoop46Resistance "Special Ignitor Loop 46 - Resistance: Resistance of Special Ignitor Loop 46.   Since there are many different vehicle types (e.g. truck, bus, firetruck or ambulance), the ignitor loop configuration has a wide variation. ";
CM_ SG_ 2633832958 SpecialIgnitorLoop47Resistance "Special Ignitor Loop 47 - Resistance: Resistance of Special Ignitor Loop 47.   Since there are many different vehicle types (e.g. truck, bus, firetruck or ambulance), the ignitor loop configuration has a wide variation. ";
CM_ SG_ 2633832958 SpecialIgnitorLoop48Resistance "Special Ignitor Loop 48 - Resistance: Resistance of Special Ignitor Loop 48.   Since there are many different vehicle types (e.g. truck, bus, firetruck or ambulance), the ignitor loop configuration has a wide variation. ";
CM_ SG_ 2633832958 SpecialIgnitorLoop49Resistance "Special Ignitor Loop 49 - Resistance: Resistance of Special Ignitor Loop 49.   Since there are many different vehicle types (e.g. truck, bus, firetruck or ambulance), the ignitor loop configuration has a wide variation. ";
CM_ SG_ 2633832958 SpecialIgnitorLoop4Resistance "Special Ignitor Loop 4 - Resistance: Resistance of Special Ignitor Loop 4.   Since there are many different vehicle types (e.g. truck, bus, firetruck or ambulance), the ignitor loop configuration has a wide variation. ";
CM_ SG_ 2633832958 SpecialIgnitorLoop50Resistance "Special Ignitor Loop 50 - Resistance: Resistance of Special Ignitor Loop 50.   Since there are many different vehicle types (e.g. truck, bus, firetruck or ambulance), the ignitor loop configuration has a wide variation. ";
CM_ SG_ 2633832958 SpecialIgnitorLoop51Resistance "Special Ignitor Loop 51 - Resistance: Resistance of Special Ignitor Loop 51.   Since there are many different vehicle types (e.g. truck, bus, firetruck or ambulance), the ignitor loop configuration has a wide variation. ";
CM_ SG_ 2633832958 SpecialIgnitorLoop52Resistance "Special Ignitor Loop 52 - Resistance: Resistance of Special Ignitor Loop 52.   Since there are many different vehicle types (e.g. truck, bus, firetruck or ambulance), the ignitor loop configuration has a wide variation. ";
CM_ SG_ 2633832958 SpecialIgnitorLoop53Resistance "Special Ignitor Loop 53 - Resistance: Resistance of Special Ignitor Loop 53.   Since there are many different vehicle types (e.g. truck, bus, firetruck or ambulance), the ignitor loop configuration has a wide variation. ";
CM_ SG_ 2633832958 SpecialIgnitorLoop54Resistance "Special Ignitor Loop 54 - Resistance: Resistance of Special Ignitor Loop 54.   Since there are many different vehicle types (e.g. truck, bus, firetruck or ambulance), the ignitor loop configuration has a wide variation. ";
CM_ SG_ 2633832958 SpecialIgnitorLoop55Resistance "Special Ignitor Loop 55 - Resistance: Resistance of Special Ignitor Loop 55.   Since there are many different vehicle types (e.g. truck, bus, firetruck or ambulance), the ignitor loop configuration has a wide variation. ";
CM_ SG_ 2633832958 SpecialIgnitorLoop56Resistance "Special Ignitor Loop 56 - Resistance: Resistance of Special Ignitor Loop 56.   Since there are many different vehicle types (e.g. truck, bus, firetruck or ambulance), the ignitor loop configuration has a wide variation. ";
CM_ SG_ 2633832958 SpecialIgnitorLoop57Resistance "Special Ignitor Loop 57 - Resistance: Resistance of Special Ignitor Loop 57.   Since there are many different vehicle types (e.g. truck, bus, firetruck or ambulance), the ignitor loop configuration has a wide variation. ";
CM_ SG_ 2633832958 SpecialIgnitorLoop58Resistance "Special Ignitor Loop 58 - Resistance: Resistance of Special Ignitor Loop 58.   Since there are many different vehicle types (e.g. truck, bus, firetruck or ambulance), the ignitor loop configuration has a wide variation. ";
CM_ SG_ 2633832958 SpecialIgnitorLoop59Resistance "Special Ignitor Loop 59 - Resistance: Resistance of Special Ignitor Loop 59.   Since there are many different vehicle types (e.g. truck, bus, firetruck or ambulance), the ignitor loop configuration has a wide variation. ";
CM_ SG_ 2633832958 SpecialIgnitorLoop5Resistance "Special Ignitor Loop 5 - Resistance: Resistance of Special Ignitor Loop 5.   Since there are many different vehicle types (e.g. truck, bus, firetruck or ambulance), the ignitor loop configuration has a wide variation. ";
CM_ SG_ 2633832958 SpecialIgnitorLoop60Resistance "Special Ignitor Loop 60 - Resistance: Resistance of Special Ignitor Loop 60.   Since there are many different vehicle types (e.g. truck, bus, firetruck or ambulance), the ignitor loop configuration has a wide variation. ";
CM_ SG_ 2633832958 SpecialIgnitorLoop61Resistance "Special Ignitor Loop 61 - Resistance: Resistance of Special Ignitor Loop 61.   Since there are many different vehicle types (e.g. truck, bus, firetruck or ambulance), the ignitor loop configuration has a wide variation. ";
CM_ SG_ 2633832958 SpecialIgnitorLoop62Resistance "Special Ignitor Loop 62 - Resistance: Resistance of Special Ignitor Loop 62.   Since there are many different vehicle types (e.g. truck, bus, firetruck or ambulance), the ignitor loop configuration has a wide variation. ";
CM_ SG_ 2633832958 SpecialIgnitorLoop63Resistance "Special Ignitor Loop 63 - Resistance: Resistance of Special Ignitor Loop 63.   Since there are many different vehicle types (e.g. truck, bus, firetruck or ambulance), the ignitor loop configuration has a wide variation. ";
CM_ SG_ 2633832958 SpecialIgnitorLoop64Resistance "Special Ignitor Loop 64 - Resistance: Resistance of Special Ignitor Loop 64.   Since there are many different vehicle types (e.g. truck, bus, firetruck or ambulance), the ignitor loop configuration has a wide variation. ";
CM_ SG_ 2633832958 SpecialIgnitorLoop65Resistance "Special Ignitor Loop 65 - Resistance: Resistance of Special Ignitor Loop 65.   Since there are many different vehicle types (e.g. truck, bus, firetruck or ambulance), the ignitor loop configuration has a wide variation. ";
CM_ SG_ 2633832958 SpecialIgnitorLoop66Resistance "Special Ignitor Loop 66 - Resistance: Resistance of Special Ignitor Loop 66.   Since there are many different vehicle types (e.g. truck, bus, firetruck or ambulance), the ignitor loop configuration has a wide variation. ";
CM_ SG_ 2633832958 SpecialIgnitorLoop67Resistance "Special Ignitor Loop 67 - Resistance: Resistance of Special Ignitor Loop 67.   Since there are many different vehicle types (e.g. truck, bus, firetruck or ambulance), the ignitor loop configuration has a wide variation. ";
CM_ SG_ 2633832958 SpecialIgnitorLoop68Resistance "Special Ignitor Loop 68 - Resistance: Resistance of Special Ignitor Loop 68.   Since there are many different vehicle types (e.g. truck, bus, firetruck or ambulance), the ignitor loop configuration has a wide variation. ";
CM_ SG_ 2633832958 SpecialIgnitorLoop69Resistance "Special Ignitor Loop 69 - Resistance: Resistance of Special Ignitor Loop 69.   Since there are many different vehicle types (e.g. truck, bus, firetruck or ambulance), the ignitor loop configuration has a wide variation. ";
CM_ SG_ 2633832958 SpecialIgnitorLoop6Resistance "Special Ignitor Loop 6 - Resistance: Resistance of Special Ignitor Loop 6.   Since there are many different vehicle types (e.g. truck, bus, firetruck or ambulance), the ignitor loop configuration has a wide variation. ";
CM_ SG_ 2633832958 SpecialIgnitorLoop70Resistance "Special Ignitor Loop 70 - Resistance: Resistance of Special Ignitor Loop 70.   Since there are many different vehicle types (e.g. truck, bus, firetruck or ambulance), the ignitor loop configuration has a wide variation. ";
CM_ SG_ 2633832958 SpecialIgnitorLoop71Resistance "Special Ignitor Loop 71 - Resistance: Resistance of Special Ignitor Loop 71.   Since there are many different vehicle types (e.g. truck, bus, firetruck or ambulance), the ignitor loop configuration has a wide variation. ";
CM_ SG_ 2633832958 SpecialIgnitorLoop72Resistance "Special Ignitor Loop 72 - Resistance: Resistance of Special Ignitor Loop 72.   Since there are many different vehicle types (e.g. truck, bus, firetruck or ambulance), the ignitor loop configuration has a wide variation. ";
CM_ SG_ 2633832958 SpecialIgnitorLoop73Resistance "Special Ignitor Loop 73 - Resistance: Resistance of Special Ignitor Loop 73.   Since there are many different vehicle types (e.g. truck, bus, firetruck or ambulance), the ignitor loop configuration has a wide variation. ";
CM_ SG_ 2633832958 SpecialIgnitorLoop74Resistance "Special Ignitor Loop 74 - Resistance: Resistance of Special Ignitor Loop 74.   Since there are many different vehicle types (e.g. truck, bus, firetruck or ambulance), the ignitor loop configuration has a wide variation. ";
CM_ SG_ 2633832958 SpecialIgnitorLoop75Resistance "Special Ignitor Loop 75 - Resistance: Resistance of Special Ignitor Loop 75.   Since there are many different vehicle types (e.g. truck, bus, firetruck or ambulance), the ignitor loop configuration has a wide variation. ";
CM_ SG_ 2633832958 SpecialIgnitorLoop76Resistance "Special Ignitor Loop 76 - Resistance: Resistance of Special Ignitor Loop 76.   Since there are many different vehicle types (e.g. truck, bus, firetruck or ambulance), the ignitor loop configuration has a wide variation. ";
CM_ SG_ 2633832958 SpecialIgnitorLoop77Resistance "Special Ignitor Loop 77 - Resistance: Resistance of Special Ignitor Loop 77.   Since there are many different vehicle types (e.g. truck, bus, firetruck or ambulance), the ignitor loop configuration has a wide variation. ";
CM_ SG_ 2633832958 SpecialIgnitorLoop78Resistance "Special Ignitor Loop 78 - Resistance: Resistance of Special Ignitor Loop 78.   Since there are many different vehicle types (e.g. truck, bus, firetruck or ambulance), the ignitor loop configuration has a wide variation. ";
CM_ SG_ 2633832958 SpecialIgnitorLoop79Resistance "Special Ignitor Loop 79 - Resistance: Resistance of Special Ignitor Loop 79.   Since there are many different vehicle types (e.g. truck, bus, firetruck or ambulance), the ignitor loop configuration has a wide variation. ";
CM_ SG_ 2633832958 SpecialIgnitorLoop7Resistance "Special Ignitor Loop 7 - Resistance: Resistance of Special Ignitor Loop 7.   Since there are many different vehicle types (e.g. truck, bus, firetruck or ambulance), the ignitor loop configuration has a wide variation. ";
CM_ SG_ 2633832958 SpecialIgnitorLoop80Resistance "Special Ignitor Loop 80 - Resistance: Resistance of Special Ignitor Loop 80.   Since there are many different vehicle types (e.g. truck, bus, firetruck or ambulance), the ignitor loop configuration has a wide variation. ";
CM_ SG_ 2633832958 SpecialIgnitorLoop81Resistance "Special Ignitor Loop 81 - Resistance: Resistance of Special Ignitor Loop 81.   Since there are many different vehicle types (e.g. truck, bus, firetruck or ambulance), the ignitor loop configuration has a wide variation. ";
CM_ SG_ 2633832958 SpecialIgnitorLoop82Resistance "Special Ignitor Loop 82 - Resistance: Resistance of Special Ignitor Loop 82.   Since there are many different vehicle types (e.g. truck, bus, firetruck or ambulance), the ignitor loop configuration has a wide variation. ";
CM_ SG_ 2633832958 SpecialIgnitorLoop83Resistance "Special Ignitor Loop 83 - Resistance: Resistance of Special Ignitor Loop 83.   Since there are many different vehicle types (e.g. truck, bus, firetruck or ambulance), the ignitor loop configuration has a wide variation. ";
CM_ SG_ 2633832958 SpecialIgnitorLoop84Resistance "Special Ignitor Loop 84 - Resistance: Resistance of Special Ignitor Loop 84.   Since there are many different vehicle types (e.g. truck, bus, firetruck or ambulance), the ignitor loop configuration has a wide variation. ";
CM_ SG_ 2633832958 SpecialIgnitorLoop85Resistance "Special Ignitor Loop 85 - Resistance: Resistance of Special Ignitor Loop 85.   Since there are many different vehicle types (e.g. truck, bus, firetruck or ambulance), the ignitor loop configuration has a wide variation. ";
CM_ SG_ 2633832958 SpecialIgnitorLoop86Resistance "Special Ignitor Loop 86 - Resistance: Resistance of Special Ignitor Loop 86.   Since there are many different vehicle types (e.g. truck, bus, firetruck or ambulance), the ignitor loop configuration has a wide variation. ";
CM_ SG_ 2633832958 SpecialIgnitorLoop87Resistance "Special Ignitor Loop 87 - Resistance: Resistance of Special Ignitor Loop 87.   Since there are many different vehicle types (e.g. truck, bus, firetruck or ambulance), the ignitor loop configuration has a wide variation. ";
CM_ SG_ 2633832958 SpecialIgnitorLoop88Resistance "Special Ignitor Loop 88 - Resistance: Resistance of Special Ignitor Loop 88.   Since there are many different vehicle types (e.g. truck, bus, firetruck or ambulance), the ignitor loop configuration has a wide variation. ";
CM_ SG_ 2633832958 SpecialIgnitorLoop89Resistance "Special Ignitor Loop 89 - Resistance: Resistance of Special Ignitor Loop 89.   Since there are many different vehicle types (e.g. truck, bus, firetruck or ambulance), the ignitor loop configuration has a wide variation. ";
CM_ SG_ 2633832958 SpecialIgnitorLoop8Resistance "Special Ignitor Loop 8 - Resistance: Resistance of Special Ignitor Loop 8.   Since there are many different vehicle types (e.g. truck, bus, firetruck or ambulance), the ignitor loop configuration has a wide variation. ";
CM_ SG_ 2633832958 SpecialIgnitorLoop90Resistance "Special Ignitor Loop 90 - Resistance: Resistance of Special Ignitor Loop 90.   Since there are many different vehicle types (e.g. truck, bus, firetruck or ambulance), the ignitor loop configuration has a wide variation. ";
CM_ SG_ 2633832958 SpecialIgnitorLoop9Resistance "Special Ignitor Loop 9 - Resistance: Resistance of Special Ignitor Loop 9.   Since there are many different vehicle types (e.g. truck, bus, firetruck or ambulance), the ignitor loop configuration has a wide variation. ";
CM_ BO_ 2633853438 "Axle Group Calibration Weights";
CM_ SG_ 2633853438 AdditionalAxleGroupLocation "Additional Axle Group Location: Location of the axle group, listed from front of the vehicle to rear.  If the value of SPN 4074 is 15, then this SP is used to indicate the axle group referred to by this PG. Otherwise, this SP should be broadcast as 1...";
CM_ SG_ 2633853438 AxleGroupEmptyWeightCalibration "Axle Group Empty Weight Calibration: The empty weight calibration measurement of an axle group";
CM_ SG_ 2633853438 AxleGroupFullWeightCalibration "Axle Group Full Weight Calibration: The full weight calibration measurement of an axle group";
CM_ SG_ 2633853438 AxleGroupLocation "Axle Group Location: Specific axle group used in conjunction with and when communicating the axle group calibration, listed from the front of the vehicle to the rear.If the value of SPN 5936 is 1111b, then this SP is used to indicate the axle group r...";
CM_ BO_ 2633861886 "SAE J2012 DTC Display";
CM_ SG_ 2633861886 J2012DTC "J2012 DTC: Five character ASCII SAE J2012 DTC, sent most significant byte first.";
CM_ SG_ 2633861886 J2012DTCOccurrenceCount "J2012 DTC Occurrence Count: Number of occurrences of the respective SAE J2012 DTC being conveyed.If more than 126 occurrences happen the value shall be set to 126.If the occurrence count is not available to be sent then this value shall be set to 127...";
CM_ SG_ 2633861886 J2012DTCStatus "J2012 DTC Status: Indicates if the respective SAE J2012 DTC is active or previously active.0b = DTC is previously active1b = DTC is active";
CM_ SG_ 2633861886 NumberofJ2012DTCs "Number of J2012 DTCs: The number J2012 DTCs being conveyed in PGN 64906.  If the value of this parameter is zero, the device broadcasting PGN 64906 has no active or previously active J2012 DTCs.";
CM_ BO_ 2633869310 "Voltage Regulator Operating Mode";
CM_ SG_ 2633869310 VltgRgltrLdCmpnstnMd "Voltage Regulator Load Compensation Mode: State signal indicating the voltage regulator load compensation mode.  Load compensation is when the voltage is adjusted based on the magnitude of load current000b = load compensation disabled001b = Voltage d...";
CM_ SG_ 2633869310 VltgRgltrUndrfrqnCmpnstnnld "Voltage Regulator Underfrequency Compensation enabled: State signal indicating the operating mode for underfrequency compensation.00b = Underfrequency compensation disabled01b = Underfrequency compensation enabled10b = Reserved11b = Not availableNote...";
CM_ SG_ 2633869310 VltgRgltrVArPwrFtrprtngmd "Voltage Regulator VAr/Power Factor operating mode: State signal indicating the operating mode for the Voltage regulator VAr/Power Factor 000b = VAr/Power Factor regulation disabled001b = Power factor regulation enabled010b = VAr regulation enabled011...";
CM_ SG_ 2633869310 VoltageRegulatorEnabled "Voltage Regulator Enabled: State signal indicating the Voltage Regulator is enabled.  This parameter indicates whether the regulator is regulating or not regulating generator output voltage.00b = Not regulating voltage - unit disabled01b = Regulating...";
CM_ SG_ 2633869310 VoltageRegulatorSoftStartState "Voltage Regulator Soft Start State: State signal indicating the mode of the Voltage regulator soft start function.  Soft start controls the generator voltage overshoot by controlling the rate of rise of the generator output voltage at generator start...";
CM_ BO_ 2633878014 "Electronic Control Module Information";
CM_ SG_ 2633878014 TtlCntfCnfgrtnChngsMd "Total Count of Configuration Changes Made: Total number of times changes have been made to any of the configurable parameters.";
CM_ BO_ 2633880062 "FMS-standard Interface Identity/Capabilities";
CM_ SG_ 2633880062 FMSstandardDiagnosticsSupported "FMS-standard Diagnostics Supported: Status signal which indicates if the FMS Vehicle Interface (FMS Gateway) supports the handling of diagnostic messages from the vehicle network onto the FMS network.The FMS gateway does NOT support the re-broadcast ...";
CM_ SG_ 2633880062 FMSstandardRequestsSupported "FMS-standard Requests Supported: Status signal which indicates if the FMS Vehicle Interface (FMS Gateway) will respond to requests from the FMS device for the PGs listed in the FMS Interface Specification.This mode is to support FMS  gateway devices ...";
CM_ SG_ 2633880062 FMSstandardSWversionsupported "FMS-standard SW-version supported.: Information that identifies which issue level of the FMS-standard document the software included in the FMS gateway supports. Four bytes, representing xx.yy type revision level identification.Information to be ASCI...";
CM_ BO_ 2633883646 "Front Wheel Drive Status";
CM_ SG_ 2633883646 FrontWheelDriveActuatorStatus "Front Wheel Drive Actuator Status: Feedback on the front wheel drive actuator.00b = Front Wheel Drive Actuator not engaged01b = Front Wheel Drive Actuator engaged10b = Error11b = Not Available";
CM_ BO_ 2633911806 "Total Averaged Information";
CM_ SG_ 2633911806 EngineTotalAverageFuelEconomy "Engine Total Average Fuel Economy: Average fuel economy, equal to total vehicle distance divided by total fuel used, over the life of the engine";
CM_ SG_ 2633911806 EngineTotalAverageFuelRate "Engine Total Average Fuel Rate: Average fuel rate, equal to total fuel used divided by total engine hours, over the life of the engine";
CM_ BO_ 2633922558 "Auxiliary Pressures";
CM_ SG_ 2633922558 AuxiliaryGagePressureReading1 "Auxiliary Gage Pressure Reading 1: Identifies the current gage pressure (relative to atmosphere) that is configured uniquely per application.  Not to be used in place of defined parameters.";
CM_ SG_ 2633922558 AuxiliaryVacuumPressureReading "Auxiliary Vacuum Pressure Reading: Identifies the current vacuum pressure (relative to atmosphere) that is configured uniquely per application.  Not to be used in place of defined parameters.";
CM_ SG_ 2633922558 AxlrAsltPrssrRdng "Auxiliary Absolute Pressure Reading: Identifies the current absolute pressure (relative to 0 pressure) that is configured uniquely per application.  Not to be used in place of defined parameters.";
CM_ BO_ 2633922814 "Tire Pressure Control Unit Mode and Status";
CM_ SG_ 2633922814 DriveChannelMode "Drive Channel Mode: Indicates the functional mode of trailer/tag channel of the tire pressure control system.  0000b = Maintain0001b = Inflate0010b = Deflate0011b = Confirm0100b = Inflate Wait – System will inflate when conditions allow0101b = Deflat...";
CM_ SG_ 2633922814 PCUControlSolenoidStatus "PCU Control Solenoid Status: Current state of the control solenoid used to implement a tire pressure control system in its pneumatic control unit (PCU).00b = Off01b = On10b = Error11b = Not available";
CM_ SG_ 2633922814 PCUDeflateSolenoidStatus "PCU Deflate Solenoid Status: Current state of the deflate solenoid used to implement a tire pressure control system in its pneumatic control unit (PCU).00b = Off01b = On10b = Error11b = Not available";
CM_ SG_ 2633922814 PCUDriveSolenoidStatus "PCU Drive Solenoid Status: Current state of the drive solenoid used to implement a tire pressure control system in its pneumatic control unit (PCU).00b = Off01b = On10b = Error11b = Not available";
CM_ SG_ 2633922814 PCUSteerSolenoidStatus "PCU Steer Solenoid Status: Current state of the steer solenoid used to implement a tire pressure control system in its pneumatic control unit (PCU).00b = Off01b = On10b = Error11b = Not available";
CM_ SG_ 2633922814 PCUSupplySolenoidStatus "PCU Supply Solenoid Status: Current state of the supply solenoid used to implement a tire pressure control system in its pneumatic control unit (PCU).00b = Off01b = On10b = Error11b = Not available";
CM_ SG_ 2633922814 PCUTrlrTgrPshSlndStts "PCU Trailer, Tag or Push Solenoid Status: Current state of the trailer, tag, or push solenoid used to implement a tire pressure control system in its pneumatic control unit (PCU).00b = Off01b = On10b = Error11b = Not available";
CM_ SG_ 2633922814 SteerChannelMode "Steer Channel Mode: Indicates the functional mode of steer channel of the tire pressure control system. 0000b = Maintain0001b = Inflate0010b = Deflate0011b = Confirm0100b = Inflate Wait – System will inflate when conditions allow0101b = Deflate Wait ...";
CM_ SG_ 2633922814 TirePressureCheckInterval "Tire Pressure Check Interval: The interval at which the system will check the tire pressures (e.g., 5, 10, 15 min.).NOTE - A value of 0 indicates continuous (real time) pressure readings.";
CM_ SG_ 2633922814 TirePressureSupplySwitchStatus "Tire Pressure Supply Switch Status: Current state of an open/closed type switch used to determine if adequate pressure exists for system implementation.00b = Off01b = On10b = Error11b = Not available";
CM_ SG_ 2633922814 TrailertagChannelMode "Trailer/tag Channel Mode: Indicates the functional mode of trailer/tag channel of the tire pressure control system.0000b = Maintain0001b = Inflate0010b = Deflate0011b = Confirm0100b = Inflate Wait – System will inflate when conditions allow0101b = De...";
CM_ BO_ 2633923070 "Tire Pressure Control Unit Target Pressures";
CM_ SG_ 2633923070 DriveChannelTirePressureTarget "Drive Channel Tire Pressure Target: The tire pressure control system’s target gage pressure for the drive group of tires.";
CM_ SG_ 2633923070 SteerChannelTirePressureTarget "Steer Channel Tire Pressure Target: The tire pressure control system’s target gage pressure for the steer group of tires.";
CM_ SG_ 2633923070 TrlrTgOrPshChnnlTrPrssrTrgt "Trailer, Tag Or Push Channel Tire Pressure Target: The tire pressure control system’s target gage pressure for the trailer, tag, or push group of tires.";
CM_ BO_ 2633923326 "Tire Pressure Control Unit Current Pressures";
CM_ SG_ 2633923326 DriveChannelTirePressure "Drive Channel Tire Pressure: The latest gage pressure reading of the drive group of tires, as opposed to the pressure in each tire.";
CM_ SG_ 2633923326 SteerChannelTirePressure "Steer Channel Tire Pressure: The latest gage pressure reading of the steer group of tires, as opposed to the pressure in each tire.";
CM_ SG_ 2633923326 TrlrTgOrPshChnnlTrPrssr "Trailer, Tag Or Push Channel Tire Pressure: The latest gage pressure reading of the trailer, tag, or push group of tires, as opposed to the pressure in each tire.";
CM_ BO_ 2633923582 "Combustion Time 1";
CM_ SG_ 2633923582 EngineCylinder1CombustionTime "Engine Cylinder #1 Combustion Time: The amount of time from when the ignition of the fuel is initiated to when the fuel is completely ignited (i.e., the flame front has propagated across the cylinder).";
CM_ SG_ 2633923582 EngineCylinder2CombustionTime "Engine Cylinder #2 Combustion Time: The amount of time from when the ignition of the fuel is initiated to when the fuel is completely ignited (i.e., the flame front has propagated across the cylinder).";
CM_ SG_ 2633923582 EngineCylinder3CombustionTime "Engine Cylinder #3 Combustion Time: The amount of time from when the ignition of the fuel is initiated to when the fuel is completely ignited (i.e., the flame front has propagated across the cylinder).";
CM_ SG_ 2633923582 EngineCylinder4CombustionTime "Engine Cylinder #4 Combustion Time: The amount of time from when the ignition of the fuel is initiated to when the fuel is completely ignited (i.e., the flame front has propagated across the cylinder).";
CM_ BO_ 2633923838 "Combustion Time 2";
CM_ SG_ 2633923838 EngineCylinder5CombustionTime "Engine Cylinder #5 Combustion Time: The amount of time from when the ignition of the fuel is initiated to when the fuel is completely ignited (i.e., the flame front has propagated across the cylinder).";
CM_ SG_ 2633923838 EngineCylinder6CombustionTime "Engine Cylinder #6 Combustion Time: The amount of time from when the ignition of the fuel is initiated to when the fuel is completely ignited (i.e., the flame front has propagated across the cylinder).";
CM_ SG_ 2633923838 EngineCylinder7CombustionTime "Engine Cylinder #7 Combustion Time: The amount of time from when the ignition of the fuel is initiated to when the fuel is completely ignited (i.e., the flame front has propagated across the cylinder).";
CM_ SG_ 2633923838 EngineCylinder8CombustionTime "Engine Cylinder #8 Combustion Time: The amount of time from when the ignition of the fuel is initiated to when the fuel is completely ignited (i.e., the flame front has propagated across the cylinder).";
CM_ BO_ 2633924094 "Combustion Time 3";
CM_ SG_ 2633924094 EngineCylinder10CombustionTime "Engine Cylinder #10 Combustion Time: The amount of time from when the ignition of the fuel is initiated to when the fuel is completely ignited (i.e., the flame front has propagated across the cylinder).";
CM_ SG_ 2633924094 EngineCylinder11CombustionTime "Engine Cylinder #11 Combustion Time: The amount of time from when the ignition of the fuel is initiated to when the fuel is completely ignited (i.e., the flame front has propagated across the cylinder).";
CM_ SG_ 2633924094 EngineCylinder12CombustionTime "Engine Cylinder #12 Combustion Time: The amount of time from when the ignition of the fuel is initiated to when the fuel is completely ignited (i.e., the flame front has propagated across the cylinder).";
CM_ SG_ 2633924094 EngineCylinder9CombustionTime "Engine Cylinder #9 Combustion Time: The amount of time from when the ignition of the fuel is initiated to when the fuel is completely ignited (i.e., the flame front has propagated across the cylinder).";
CM_ BO_ 2633924350 "Combustion Time 4";
CM_ SG_ 2633924350 EngineCylinder13CombustionTime "Engine Cylinder #13 Combustion Time: The amount of time from when the ignition of the fuel is initiated to when the fuel is completely ignited (i.e., the flame front has propagated across the cylinder).";
CM_ SG_ 2633924350 EngineCylinder14CombustionTime "Engine Cylinder #14 Combustion Time: The amount of time from when the ignition of the fuel is initiated to when the fuel is completely ignited (i.e., the flame front has propagated across the cylinder).";
CM_ SG_ 2633924350 EngineCylinder15CombustionTime "Engine Cylinder #15 Combustion Time: The amount of time from when the ignition of the fuel is initiated to when the fuel is completely ignited (i.e., the flame front has propagated across the cylinder).";
CM_ SG_ 2633924350 EngineCylinder16CombustionTime "Engine Cylinder #16 Combustion Time: The amount of time from when the ignition of the fuel is initiated to when the fuel is completely ignited (i.e., the flame front has propagated across the cylinder).";
CM_ BO_ 2633924606 "Combustion Time 5";
CM_ SG_ 2633924606 EngineCylinder17CombustionTime "Engine Cylinder #17 Combustion Time: The amount of time from when the ignition of the fuel is initiated to when the fuel is completely ignited (i.e., the flame front has propagated across the cylinder).";
CM_ SG_ 2633924606 EngineCylinder18CombustionTime "Engine Cylinder #18 Combustion Time: The amount of time from when the ignition of the fuel is initiated to when the fuel is completely ignited (i.e., the flame front has propagated across the cylinder).";
CM_ SG_ 2633924606 EngineCylinder19CombustionTime "Engine Cylinder #19 Combustion Time: The amount of time from when the ignition of the fuel is initiated to when the fuel is completely ignited (i.e., the flame front has propagated across the cylinder).";
CM_ SG_ 2633924606 EngineCylinder20CombustionTime "Engine Cylinder #20 Combustion Time: The amount of time from when the ignition of the fuel is initiated to when the fuel is completely ignited (i.e., the flame front has propagated across the cylinder).";
CM_ BO_ 2633924862 "Combustion Time 6";
CM_ SG_ 2633924862 EngineAverageCombustionTime "Engine Average Combustion Time: The average combustion time of all cylinders of an engine.";
CM_ SG_ 2633924862 EngineDesiredCombustionTime "Engine Desired Combustion Time: The desired combustion time based upon engine load and speed lookup maps.";
CM_ BO_ 2633925118 "Fuel Information 2 (Gaseous)";
CM_ SG_ 2633925118 EngineFuelFlowRate1 "Engine Fuel Flow Rate 1: The rate at which the fuel is flowing through a fuel valve.";
CM_ SG_ 2633925118 EngineFuelFlowRate2 "Engine Fuel Flow Rate 2: The rate at which the fuel is flowing through a fuel valve.";
CM_ SG_ 2633925118 EngineFuelValve1Position "Engine Fuel Valve 1 Position: The position of a gaseous fuel valve that is metering the fuel flow to the engine.  0% indicates no fuel flow through valve and 100% means maximum fuel flow through valve.";
CM_ SG_ 2633925118 EngineFuelValve2Position "Engine Fuel Valve 2 Position: The position of a gaseous fuel valve that is metering the fuel flow to the engine.  0% indicates no fuel flow through valve and 100% means maximum fuel flow through valve.";
CM_ SG_ 2633925118 EngnFlVlv1CmmnddPstn "Engine Fuel Valve 1 Commanded Position: The commanded position of the first fuel valve that is metering the fuel flow to the engine.";
CM_ SG_ 2633925118 EngnFlVlv2CmmnddPstn "Engine Fuel Valve 2 Commanded Position: The commanded position of the second fuel valve that is metering the fuel flow to the engine.";
CM_ BO_ 2633925374 "Ignition Timing 1";
CM_ SG_ 2633925374 EngineCylinder1IgnitionTiming "Engine Cylinder 1 Ignition Timing: The ignition timing (SI engines) or main fuel injection timing (CI engines) of the cylinder. Positive values indicate an increasingly advanced timing from TDC.";
CM_ SG_ 2633925374 EngineCylinder2IgnitionTiming "Engine Cylinder 2 Ignition Timing: The ignition timing (SI engines) or main fuel injection timing (CI engines) of the cylinder. Positive values indicate an increasingly advanced timing from TDC.";
CM_ SG_ 2633925374 EngineCylinder3IgnitionTiming "Engine Cylinder 3 Ignition Timing: The ignition timing (SI engines) or main fuel injection timing (CI engines) of the cylinder. Positive values indicate an increasingly advanced timing from TDC.";
CM_ SG_ 2633925374 EngineCylinder4IgnitionTiming "Engine Cylinder 4 Ignition Timing: The ignition timing (SI engines) or main fuel injection timing (CI engines) of the cylinder. Positive values indicate an increasingly advanced timing from TDC.";
CM_ BO_ 2633925630 "Ignition Timing 2";
CM_ SG_ 2633925630 EngineCylinder5IgnitionTiming "Engine Cylinder 5 Ignition Timing: The ignition timing (SI engines) or main fuel injection timing (CI engines) of the cylinder. Positive values indicate an increasingly advanced timing from TDC.";
CM_ SG_ 2633925630 EngineCylinder6IgnitionTiming "Engine Cylinder 6 Ignition Timing: The ignition timing (SI engines) or main fuel injection timing (CI engines) of the cylinder. Positive values indicate an increasingly advanced timing from TDC.";
CM_ SG_ 2633925630 EngineCylinder7IgnitionTiming "Engine Cylinder 7 Ignition Timing: The ignition timing (SI engines) or main fuel injection timing (CI engines) of the cylinder. Positive values indicate an increasingly advanced timing from TDC.";
CM_ SG_ 2633925630 EngineCylinder8IgnitionTiming "Engine Cylinder 8 Ignition Timing: The ignition timing (SI engines) or main fuel injection timing (CI engines) of the cylinder. Positive values indicate an increasingly advanced timing from TDC.";
CM_ BO_ 2633925886 "Ignition Timing 3";
CM_ SG_ 2633925886 EngineCylinder10IgnitionTiming "Engine Cylinder 10 Ignition Timing: The ignition timing (SI engines) or main fuel injection timing (CI engines) of the cylinder. Positive values indicate an increasingly advanced timing from TDC.";
CM_ SG_ 2633925886 EngineCylinder11IgnitionTiming "Engine Cylinder 11 Ignition Timing: The ignition timing (SI engines) or main fuel injection timing (CI engines) of the cylinder. Positive values indicate an increasingly advanced timing from TDC.";
CM_ SG_ 2633925886 EngineCylinder12IgnitionTiming "Engine Cylinder 12 Ignition Timing: The ignition timing (SI engines) or main fuel injection timing (CI engines) of the cylinder. Positive values indicate an increasingly advanced timing from TDC.";
CM_ SG_ 2633925886 EngineCylinder9IgnitionTiming "Engine Cylinder 9 Ignition Timing: The ignition timing (SI engines) or main fuel injection timing (CI engines) of the cylinder. Positive values indicate an increasingly advanced timing from TDC.";
CM_ BO_ 2633926142 "Ignition Timing 4";
CM_ SG_ 2633926142 EngineCylinder13IgnitionTiming "Engine Cylinder 13 Ignition Timing: The ignition timing (SI engines) or main fuel injection timing (CI engines) of the cylinder. Positive values indicate an increasingly advanced timing from TDC.";
CM_ SG_ 2633926142 EngineCylinder14IgnitionTiming "Engine Cylinder 14 Ignition Timing: The ignition timing (SI engines) or main fuel injection timing (CI engines) of the cylinder. Positive values indicate an increasingly advanced timing from TDC.";
CM_ SG_ 2633926142 EngineCylinder15IgnitionTiming "Engine Cylinder 15 Ignition Timing: The ignition timing (SI engines) or main fuel injection timing (CI engines) of the cylinder. Positive values indicate an increasingly advanced timing from TDC.";
CM_ SG_ 2633926142 EngineCylinder16IgnitionTiming "Engine Cylinder 16 Ignition Timing: The ignition timing (SI engines) or main fuel injection timing (CI engines) of the cylinder. Positive values indicate an increasingly advanced timing from TDC.";
CM_ BO_ 2633926398 "Ignition Timing 5";
CM_ SG_ 2633926398 EngineCylinder17IgnitionTiming "Engine Cylinder 17 Ignition Timing: The ignition timing (SI engines) or main fuel injection timing (CI engines) of the cylinder. Positive values indicate an increasingly advanced timing from TDC.";
CM_ SG_ 2633926398 EngineCylinder18IgnitionTiming "Engine Cylinder 18 Ignition Timing: The ignition timing (SI engines) or main fuel injection timing (CI engines) of the cylinder. Positive values indicate an increasingly advanced timing from TDC.";
CM_ SG_ 2633926398 EngineCylinder19IgnitionTiming "Engine Cylinder 19 Ignition Timing: The ignition timing (SI engines) or main fuel injection timing (CI engines) of the cylinder. Positive values indicate an increasingly advanced timing from TDC.";
CM_ SG_ 2633926398 EngineCylinder20IgnitionTiming "Engine Cylinder 20 Ignition Timing: The ignition timing (SI engines) or main fuel injection timing (CI engines) of the cylinder. Positive values indicate an increasingly advanced timing from TDC.";
CM_ BO_ 2633926654 "Ignition Timing 6";
CM_ SG_ 2633926654 EngineActualIgnitionTiming "Engine Actual Ignition Timing: The actual ignition timing at the current engine conditions. This parameter may or may not be equal to one of the desired timing parameters (see SPNs 1433-1435), depending on the status of the engine. Positive values in...";
CM_ SG_ 2633926654 EngineDesiredIgnitionTiming1 "Engine Desired Ignition Timing 1: A programmable timing value specific to the engine’s application. Factors affecting this value include both fuel type and the nature of the load being driven. Positive values indicate an increasingly advanced timing ...";
CM_ SG_ 2633926654 EngineDesiredIgnitionTiming2 "Engine Desired Ignition Timing 2: A programmable timing value specific to the engine’s application. Factors affecting this value include both fuel type and the nature of the load being driven. Positive values indicate an increasingly advanced timing ...";
CM_ SG_ 2633926654 EngineDesiredIgnitionTiming3 "Engine Desired Ignition Timing 3: A programmable timing value specific to the engine’s application. Factors affecting this value include both fuel type and the nature of the load being driven. Positive values indicate an increasingly advanced timing ...";
CM_ BO_ 2633926910 "Ignition Transformer Secondary Output 1";
CM_ SG_ 2633926910 EngnClndr1IgntnTrnsfrmrSndrOtpt "Engine Cylinder 1 Ignition Transformer Secondary Output: This parameter indicates the relative intensity of the secondary output voltage of the ignition transformer.";
CM_ SG_ 2633926910 EngnClndr2IgntnTrnsfrmrSndrOtpt "Engine Cylinder 2 Ignition Transformer Secondary Output: This parameter indicates the relative intensity of the secondary output voltage of the ignition transformer.";
CM_ SG_ 2633926910 EngnClndr3IgntnTrnsfrmrSndrOtpt "Engine Cylinder 3 Ignition Transformer Secondary Output: This parameter indicates the relative intensity of the secondary output voltage of the ignition transformer.";
CM_ SG_ 2633926910 EngnClndr4IgntnTrnsfrmrSndrOtpt "Engine Cylinder 4 Ignition Transformer Secondary Output: This parameter indicates the relative intensity of the secondary output voltage of the ignition transformer.";
CM_ SG_ 2633926910 EngnClndr5IgntnTrnsfrmrSndrOtpt "Engine Cylinder 5 Ignition Transformer Secondary Output: This parameter indicates the relative intensity of the secondary output voltage of the ignition transformer.";
CM_ SG_ 2633926910 EngnClndr6IgntnTrnsfrmrSndrOtpt "Engine Cylinder 6 Ignition Transformer Secondary Output: This parameter indicates the relative intensity of the secondary output voltage of the ignition transformer.";
CM_ SG_ 2633926910 EngnClndr7IgntnTrnsfrmrSndrOtpt "Engine Cylinder 7 Ignition Transformer Secondary Output: This parameter indicates the relative intensity of the secondary output voltage of the ignition transformer.";
CM_ SG_ 2633926910 EngnClndr8IgntnTrnsfrmrSndrOtpt "Engine Cylinder 8 Ignition Transformer Secondary Output: This parameter indicates the relative intensity of the secondary output voltage of the ignition transformer.";
CM_ BO_ 2633927166 "Ignition Transformer Secondary Output 2";
CM_ SG_ 2633927166 ECd10ItTsSdOtpt "Engine Cylinder 10 Ignition Transformer Secondary Output: This parameter indicates the relative intensity of the secondary output voltage of the ignition transformer.";
CM_ SG_ 2633927166 ECd11ItTsSdOtpt "Engine Cylinder 11 Ignition Transformer Secondary Output: This parameter indicates the relative intensity of the secondary output voltage of the ignition transformer.";
CM_ SG_ 2633927166 ECd12ItTsSdOtpt "Engine Cylinder 12 Ignition Transformer Secondary Output: This parameter indicates the relative intensity of the secondary output voltage of the ignition transformer.";
CM_ SG_ 2633927166 ECd13ItTsSdOtpt "Engine Cylinder 13 Ignition Transformer Secondary Output: This parameter indicates the relative intensity of the secondary output voltage of the ignition transformer.";
CM_ SG_ 2633927166 ECd14ItTsSdOtpt "Engine Cylinder 14 Ignition Transformer Secondary Output: This parameter indicates the relative intensity of the secondary output voltage of the ignition transformer.";
CM_ SG_ 2633927166 ECd15ItTsSdOtpt "Engine Cylinder 15 Ignition Transformer Secondary Output: This parameter indicates the relative intensity of the secondary output voltage of the ignition transformer.";
CM_ SG_ 2633927166 ECd16ItTsSdOtpt "Engine Cylinder 16 Ignition Transformer Secondary Output: This parameter indicates the relative intensity of the secondary output voltage of the ignition transformer.";
CM_ SG_ 2633927166 EngnClndr9IgntnTrnsfrmrSndrOtpt "Engine Cylinder 9 Ignition Transformer Secondary Output: This parameter indicates the relative intensity of the secondary output voltage of the ignition transformer.";
CM_ BO_ 2633927422 "Ignition Transformer Secondary Output 3";
CM_ SG_ 2633927422 ECd17ItTsSdOtpt "Engine Cylinder 17 Ignition Transformer Secondary Output: This parameter indicates the relative intensity of the secondary output voltage of the ignition transformer.";
CM_ SG_ 2633927422 ECd18ItTsSdOtpt "Engine Cylinder 18 Ignition Transformer Secondary Output: This parameter indicates the relative intensity of the secondary output voltage of the ignition transformer.";
CM_ SG_ 2633927422 ECd19ItTsSdOtpt "Engine Cylinder 19 Ignition Transformer Secondary Output: This parameter indicates the relative intensity of the secondary output voltage of the ignition transformer.";
CM_ SG_ 2633927422 ECd20ItTsSdOtpt "Engine Cylinder 20 Ignition Transformer Secondary Output: This parameter indicates the relative intensity of the secondary output voltage of the ignition transformer.";
CM_ BO_ 2633927678 "Gaseous Fuel Pressure 1";
CM_ SG_ 2633927678 EngnArtFlDffrntlPrssr "Engine Air to Fuel Differential Pressure: The differential pressure between the gaseous fuel and the air intake manifold.";
CM_ SG_ 2633927678 EngnFlVlv1DffrntlPrssr "Engine Fuel Valve 1 Differential Pressure: The differential pressure between the intake and the outlet of the first or only gaseous fuel valve.See SPN 8494 for alternate range and resolution.";
CM_ SG_ 2633927678 EngnFlVlv1IntkAsltPrssr "Engine Fuel Valve 1 Intake Absolute Pressure: The absolute pressure of gas on the intake side of the first system control valve.  See SPN 3466 for Engine Fuel Valve 2, 7505 for Engine Fuel Valve 3 & 7506 for Engine Fuel Valve 4.";
CM_ SG_ 2633927678 EngnFlVlv1OtltAsltPrssr "Engine Fuel Valve 1 Outlet Absolute Pressure: Absolute Pressure of gas on outlet side of the first or only fuel system control valve.  See SPN 3469 for the second fuel control valve.";
CM_ BO_ 2633927934 "Auxiliary Analog Information";
CM_ SG_ 2633927934 AuxiliaryLevel "Auxiliary Level: Level measured by a sensor.";
CM_ SG_ 2633927934 AuxiliaryPressure1 "Auxiliary Pressure #1: Pressure measured by auxiliary pressure sensor #1.  Not to be used in place of existing SPs.";
CM_ SG_ 2633927934 AuxiliaryPressure2 "Auxiliary Pressure #2: Pressure measured by auxiliary pressure sensor #2.  Not to be used in place of existing SPs.";
CM_ SG_ 2633927934 AuxiliaryTemperature1 "Auxiliary Temperature 1: Temperature measured by auxiliary temperature sensor #1.  Not to be used in place of existing SPs.";
CM_ SG_ 2633927934 AuxiliaryTemperature2 "Auxiliary Temperature 2: Temperature measured by auxiliary temperature sensor #2.  Not to be used in place of existing SPs.";
CM_ SG_ 2633927934 RelativeHumidity "Relative Humidity: Measures humidity of combustion air prior to entry into turbocharger";
CM_ BO_ 2633928446 "Service 2";
CM_ SG_ 2633928446 ServiceComponentIdentification "Service Component Identification: Identification of component needing service.  See Table SPN911_A.";
CM_ SG_ 2633928446 TimeSinceLastService "Time Since Last Service: The vehicle operation time since the last service was performed.  The type of service information is identified by the service component identification number.";
CM_ BO_ 2633929214 "Fuel Leakage";
CM_ SG_ 2633929214 EngineFluidBundLevel "Engine Fluid Bund Level: Ratio of the volume of engine fluid within the bund containment frame to the maximum capacity of the bund containment frame. The bund containment frame is used to contain engine fluid leaks including, but not limited to, engi...";
CM_ SG_ 2633929214 EngineFuelLeakage1 "Engine Fuel Leakage 1: Status signal which indicates fuel leakage in the fuel rail of the engine. Location can be either before or after the fuel pump.  00b = no leakage detected01b = leakage detected10b = Error11b = Not available";
CM_ SG_ 2633929214 EngineFuelLeakage2 "Engine Fuel Leakage 2: Status signal which indicates fuel leakage in the fuel rail of the engine. Location can be either before or after the fuel pump.  00b = no leakage detected01b = leakage detected10b = Error11b = Not available";
BA_DEF_ SG_  "SPN" INT 0 524287;
BA_DEF_ BO_  "VFrameFormat" ENUM  "StandardCAN","ExtendedCAN","reserved","J1939PG";
BA_DEF_DEF_  "SPN" 0;
BA_DEF_DEF_  "VFrameFormat" "J1939PG";
BA_ "SPN" SG_ 2566848510 AtmtStrtRqstInhtIndtr 9373;
BA_ "SPN" SG_ 2566848510 DrvrWrnngSstmIndtrStts 5825;
BA_ "SPN" SG_ 2566848510 EmssnCntrlSstmOprtrIndmntSvrt 5826;
BA_ "SPN" SG_ 2566848510 EngineOverloadedIndicator 8612;
BA_ "SPN" SG_ 2566848510 FlSpplEstmtdRmnngDstn 8428;
BA_ "SPN" SG_ 2566848510 OperatorShiftPrompt 5675;
BA_ "SPN" SG_ 2566848510 WaterInFuelIndicator1 97;
BA_ "SPN" SG_ 2566848510 WaterinFuelIndicator2 6301;
BA_ "SPN" SG_ 2566848510 WtrInChrgArDtAftrChrgArClrIndtr 8611;
BA_ "SPN" SG_ 2566848510 EngineOilLifeRemaining 355;
BA_ "SPN" SG_ 2566848510 RecommendedNumberofGearstoShift 12959;
BA_ "SPN" SG_ 2624716542 CmmnddTrnsmtPGNRqstdStt 8598;
BA_ "SPN" SG_ 2624716542 CommandedTransmitPGN 8597;
BA_ "SPN" SG_ 2624716542 TransmitPGNsCommandedPort 8595;
BA_ "SPN" SG_ 2624716542 TransmitPGNsTransactionMode 8596;
BA_ "SPN" SG_ 2631728894 AntitheftComponentStatusStates 1196;
BA_ "SPN" SG_ 2631728894 AntitheftModifyPasswordStates 1197;
BA_ "SPN" SG_ 2631728894 AntitheftPasswordValidIndicator 1195;
BA_ "SPN" SG_ 2631728894 AntitheftRandomNumber 1198;
BA_ "SPN" SG_ 2631728894 AntthftEnrptnSdPrsntIndtr 1194;
BA_ "SPN" SG_ 2631794430 AntitheftCommandStates 1201;
BA_ "SPN" SG_ 2631794430 AntitheftDesiredExitModeStates 1200;
BA_ "SPN" SG_ 2631794430 AntitheftPasswordRepresentation 1202;
BA_ "SPN" SG_ 2631794430 AntthftEnrptnIndtrStts 1199;
BA_ "SPN" SG_ 2631859966 BinLiftCountReset 6898;
BA_ "SPN" SG_ 2631859966 EngineBuildHoursReset 1211;
BA_ "SPN" SG_ 2631859966 EngnIgntnCntrlMntnnHrsRst 6219;
BA_ "SPN" SG_ 2631859966 EngnSprkPlgSndrVltgTrkngRst 6218;
BA_ "SPN" SG_ 2631859966 ServiceComponentIdentification 1584;
BA_ "SPN" SG_ 2631859966 StrngStrghtAhdPstnRst 3600;
BA_ "SPN" SG_ 2631859966 TireConfigurationInformation 6985;
BA_ "SPN" SG_ 2631859966 TireSensorInformation 6986;
BA_ "SPN" SG_ 2631859966 TripGroup1 988;
BA_ "SPN" SG_ 2631859966 TripGroup2Proprietary 989;
BA_ "SPN" SG_ 2633734398 EngineActualExhaust2Oxygen 9367;
BA_ "SPN" SG_ 2633749502 WellStimulationPumpCycleCount 8659;
BA_ "SPN" SG_ 2633749502 WellStimulationPumpWorkingHours 8658;
BA_ "SPN" SG_ 2633749502 WllStmltnPmpFldEndWrkngHrs 8656;
BA_ "SPN" SG_ 2633749502 WllStmltnPmpPwrEndWrkngHrs 8657;
BA_ "SPN" SG_ 2633749758 WellStimulationPumpGearRatio 8654;
BA_ "SPN" SG_ 2633749758 WellStimulationPumpRatedSpeed 8655;
BA_ "SPN" SG_ 2633749758 WellStimulationPumpStrokeLength 8653;
BA_ "SPN" SG_ 2633749758 WllStmltnPmpPlngrDmtr 8652;
BA_ "SPN" SG_ 2633750526 CnfgrlTrnsmtPGNCrrntTrnsmtStts 8603;
BA_ "SPN" SG_ 2633750526 CnfgrlTrnsmtPGNMdfdStts 8605;
BA_ "SPN" SG_ 2633750526 CnfgrlTrnsmtPGNPndngChngStts 8604;
BA_ "SPN" SG_ 2633750526 ConfigurableTransmitPGN 8602;
BA_ "SPN" SG_ 2633750526 TransmitPGNsPort 8599;
BA_ "SPN" SG_ 2633750526 TransmitPGNsPortCommandStatus 8601;
BA_ "SPN" SG_ 2633750526 TrnsmtPGNsPrtPndngChngsStts 8600;
BA_ "SPN" SG_ 2633752830 AltrntrAftrlrClntOtltTmprtr 8471;
BA_ "SPN" SG_ 2633752830 AltrntrAftrlrClntPmpOtltPrssr 8472;
BA_ "SPN" SG_ 2633752830 AltrntrAftrlrClntPmpOtltTmprtr 8470;
BA_ "SPN" SG_ 2633752830 AltrntrOlClrClntIntkTmprtr 8468;
BA_ "SPN" SG_ 2633752830 AltrntrOlClrClntOtltTmprtr 8469;
BA_ "SPN" SG_ 2633752830 AltrntrOlClrOlIntkTmprtr 8466;
BA_ "SPN" SG_ 2633752830 AltrntrOlClrOlOtltTmprtr 8467;
BA_ "SPN" SG_ 2633752830 EngnOlClrClntOtltTmprtr 728;
BA_ "SPN" SG_ 2633753086 PowerRectifierDiode9Temperature 8459;
BA_ "SPN" SG_ 2633753086 PwrRtfrDd10Tmprtr 8460;
BA_ "SPN" SG_ 2633753086 PwrRtfrDd11Tmprtr 8461;
BA_ "SPN" SG_ 2633753086 PwrRtfrDd12Tmprtr 8462;
BA_ "SPN" SG_ 2633753342 PowerRectifierDiode1Temperature 8451;
BA_ "SPN" SG_ 2633753342 PowerRectifierDiode2Temperature 8452;
BA_ "SPN" SG_ 2633753342 PowerRectifierDiode3Temperature 8453;
BA_ "SPN" SG_ 2633753342 PowerRectifierDiode4Temperature 8454;
BA_ "SPN" SG_ 2633753342 PowerRectifierDiode5Temperature 8455;
BA_ "SPN" SG_ 2633753342 PowerRectifierDiode6Temperature 8456;
BA_ "SPN" SG_ 2633753342 PowerRectifierDiode7Temperature 8457;
BA_ "SPN" SG_ 2633753342 PowerRectifierDiode8Temperature 8458;
BA_ "SPN" SG_ 2633753598 AltrntrArClrArIntkTmprtr 8449;
BA_ "SPN" SG_ 2633753598 AltrntrArClrArOtltTmprtr 8450;
BA_ "SPN" SG_ 2633753598 EngnAltrntrWndng10Tmprtr 8446;
BA_ "SPN" SG_ 2633753598 EngnAltrntrWndng11Tmprtr 8447;
BA_ "SPN" SG_ 2633753598 EngnAltrntrWndng12Tmprtr 8448;
BA_ "SPN" SG_ 2633753598 EngnAltrntrWndng7Tmprtr 8443;
BA_ "SPN" SG_ 2633753598 EngnAltrntrWndng8Tmprtr 8444;
BA_ "SPN" SG_ 2633753598 EngnAltrntrWndng9Tmprtr 8445;
BA_ "SPN" SG_ 2633754622 Aftrtrtmnt1SCRIntkHghTmprtrTm 8327;
BA_ "SPN" SG_ 2633754622 SCROptIdtEOvdTtAtvtT 9179;
BA_ "SPN" SG_ 2633754878 AftrtrtmntTtlDslExhstFldUsd 8326;
BA_ "SPN" SG_ 2633754878 AttttDsExstFdUsdTsOptC 12748;
BA_ "SPN" SG_ 2633754878 DEFDosingMode 12749;
BA_ "SPN" SG_ 2633754878 HydrocarbonDoserDutyCycle 12743;
BA_ "SPN" SG_ 2633755390 DefaultGatewayOctet1 8278;
BA_ "SPN" SG_ 2633755390 DefaultGatewayOctet2 8279;
BA_ "SPN" SG_ 2633755390 DefaultGatewayOctet3 8280;
BA_ "SPN" SG_ 2633755390 DefaultGatewayOctet4 8281;
BA_ "SPN" SG_ 2633755390 DHCPStatus 8268;
BA_ "SPN" SG_ 2633755390 EthernetLinkStatus 8269;
BA_ "SPN" SG_ 2633755390 IPv4AddressOctet1 8270;
BA_ "SPN" SG_ 2633755390 IPv4AddressOctet2 8271;
BA_ "SPN" SG_ 2633755390 IPv4AddressOctet3 8272;
BA_ "SPN" SG_ 2633755390 IPv4AddressOctet4 8273;
BA_ "SPN" SG_ 2633755390 MACAddressOctet1 8282;
BA_ "SPN" SG_ 2633755390 MACAddressOctet2 8283;
BA_ "SPN" SG_ 2633755390 MACAddressOctet3 8284;
BA_ "SPN" SG_ 2633755390 MACAddressOctet4 8285;
BA_ "SPN" SG_ 2633755390 MACAddressOctet5 8286;
BA_ "SPN" SG_ 2633755390 MACAddressOctet6 8287;
BA_ "SPN" SG_ 2633755390 SubnetMaskOctet1 8274;
BA_ "SPN" SG_ 2633755390 SubnetMaskOctet2 8275;
BA_ "SPN" SG_ 2633755390 SubnetMaskOctet3 8276;
BA_ "SPN" SG_ 2633755390 SubnetMaskOctet4 8277;
BA_ "SPN" SG_ 2633764094 CanisterPurgeValveCommand 7834;
BA_ "SPN" SG_ 2633764094 CanisterVentValve 7833;
BA_ "SPN" SG_ 2633764094 GasolineFuelTankPressure 7835;
BA_ "SPN" SG_ 2633764350 FirePumpEngagementCycles 7826;
BA_ "SPN" SG_ 2633764350 FirePumpOperationTime 7825;
BA_ "SPN" SG_ 2633769726 EngnExhstFlwRtExtnddRng 7852;
BA_ "SPN" SG_ 2633769726 TotalEngineEnergy 7608;
BA_ "SPN" SG_ 2633773054 FireSuppressionWaterTankLevel 7347;
BA_ "SPN" SG_ 2633773054 FrSpprssnClssAFmTnkLvl 7348;
BA_ "SPN" SG_ 2633773054 FrSpprssnClssBFmTnkLvl 7349;
BA_ "SPN" SG_ 2633773054 FrSpprssnCmprssdArFmSstmArPrssr 7350;
BA_ "SPN" SG_ 2633773310 SCROprtrIndmntOvrrdMd 7342;
BA_ "SPN" SG_ 2633773310 SCROprtrIndmntOvrrdRnwlRqrd 7343;
BA_ "SPN" SG_ 2633773310 SCROptIdtEOvdTtRstOs 7341;
BA_ "SPN" SG_ 2633773310 SCROptIdtOvdTRExtddR 7344;
BA_ "SPN" SG_ 2633782014 BinInstance 6845;
BA_ "SPN" SG_ 2633782014 BinLiftCount 6840;
BA_ "SPN" SG_ 2633782014 BinWeighingErrorStatus 6842;
BA_ "SPN" SG_ 2633782014 NetBinWeight 6841;
BA_ "SPN" SG_ 2633785086 HVESSStateofHealth 8121;
BA_ "SPN" SG_ 2633785086 HVESSCnttrOpnUndrLdCnt 8122;
BA_ "SPN" SG_ 2633785086 HVESSTotalEnergyThroughput 8211;
BA_ "SPN" SG_ 2633785086 HVESSTotalAccumulatedCharge 8212;
BA_ "SPN" SG_ 2633785086 HVESSTotalLifetimeEnergyInput 13365;
BA_ "SPN" SG_ 2633785086 HVESSTotalLifetimeEnergyOutput 13366;
BA_ "SPN" SG_ 2633801982 EngnTtlHrsfDslFlOprtn 6320;
BA_ "SPN" SG_ 2633801982 EngnTtlHrsfGssFlOprtn 6319;
BA_ "SPN" SG_ 2633802238 EngineSparkPlug17MisfireRate 6286;
BA_ "SPN" SG_ 2633802238 EngineSparkPlug18MisfireRate 6287;
BA_ "SPN" SG_ 2633802238 EngineSparkPlug19MisfireRate 6288;
BA_ "SPN" SG_ 2633802238 EngineSparkPlug20MisfireRate 6289;
BA_ "SPN" SG_ 2633802238 EngineSparkPlug21MisfireRate 6290;
BA_ "SPN" SG_ 2633802238 EngineSparkPlug22MisfireRate 6291;
BA_ "SPN" SG_ 2633802238 EngineSparkPlug23MisfireRate 6292;
BA_ "SPN" SG_ 2633802238 EngineSparkPlug24MisfireRate 6293;
BA_ "SPN" SG_ 2633802494 EngineSparkPlug10MisfireRate 6279;
BA_ "SPN" SG_ 2633802494 EngineSparkPlug11MisfireRate 6280;
BA_ "SPN" SG_ 2633802494 EngineSparkPlug12MisfireRate 6281;
BA_ "SPN" SG_ 2633802494 EngineSparkPlug13MisfireRate 6282;
BA_ "SPN" SG_ 2633802494 EngineSparkPlug14MisfireRate 6283;
BA_ "SPN" SG_ 2633802494 EngineSparkPlug15MisfireRate 6284;
BA_ "SPN" SG_ 2633802494 EngineSparkPlug16MisfireRate 6285;
BA_ "SPN" SG_ 2633802494 EngineSparkPlug9MisfireRate 6278;
BA_ "SPN" SG_ 2633802750 EngineSparkPlug1MisfireRate 6270;
BA_ "SPN" SG_ 2633802750 EngineSparkPlug2MisfireRate 6271;
BA_ "SPN" SG_ 2633802750 EngineSparkPlug3MisfireRate 6272;
BA_ "SPN" SG_ 2633802750 EngineSparkPlug4MisfireRate 6273;
BA_ "SPN" SG_ 2633802750 EngineSparkPlug5MisfireRate 6274;
BA_ "SPN" SG_ 2633802750 EngineSparkPlug6MisfireRate 6275;
BA_ "SPN" SG_ 2633802750 EngineSparkPlug7MisfireRate 6276;
BA_ "SPN" SG_ 2633802750 EngineSparkPlug8MisfireRate 6277;
BA_ "SPN" SG_ 2633803006 EngineSparkPlug21MaximumVoltage 6266;
BA_ "SPN" SG_ 2633803006 EngineSparkPlug22MaximumVoltage 6267;
BA_ "SPN" SG_ 2633803006 EngineSparkPlug23MaximumVoltage 6268;
BA_ "SPN" SG_ 2633803006 EngineSparkPlug24MaximumVoltage 6269;
BA_ "SPN" SG_ 2633803262 EngineSparkPlug17MaximumVoltage 6262;
BA_ "SPN" SG_ 2633803262 EngineSparkPlug18MaximumVoltage 6263;
BA_ "SPN" SG_ 2633803262 EngineSparkPlug19MaximumVoltage 6264;
BA_ "SPN" SG_ 2633803262 EngineSparkPlug20MaximumVoltage 6265;
BA_ "SPN" SG_ 2633803518 EngineSparkPlug13MaximumVoltage 6258;
BA_ "SPN" SG_ 2633803518 EngineSparkPlug14MaximumVoltage 6259;
BA_ "SPN" SG_ 2633803518 EngineSparkPlug15MaximumVoltage 6260;
BA_ "SPN" SG_ 2633803518 EngineSparkPlug16MaximumVoltage 6261;
BA_ "SPN" SG_ 2633803774 EngineSparkPlug10MaximumVoltage 6255;
BA_ "SPN" SG_ 2633803774 EngineSparkPlug11MaximumVoltage 6256;
BA_ "SPN" SG_ 2633803774 EngineSparkPlug12MaximumVoltage 6257;
BA_ "SPN" SG_ 2633803774 EngineSparkPlug9MaximumVoltage 6254;
BA_ "SPN" SG_ 2633804030 EngineSparkPlug5MaximumVoltage 6250;
BA_ "SPN" SG_ 2633804030 EngineSparkPlug6MaximumVoltage 6251;
BA_ "SPN" SG_ 2633804030 EngineSparkPlug7MaximumVoltage 6252;
BA_ "SPN" SG_ 2633804030 EngineSparkPlug8MaximumVoltage 6253;
BA_ "SPN" SG_ 2633804286 EngineSparkPlug1MaximumVoltage 6246;
BA_ "SPN" SG_ 2633804286 EngineSparkPlug2MaximumVoltage 6247;
BA_ "SPN" SG_ 2633804286 EngineSparkPlug3MaximumVoltage 6248;
BA_ "SPN" SG_ 2633804286 EngineSparkPlug4MaximumVoltage 6249;
BA_ "SPN" SG_ 2633804542 EngineSparkPlug21MinimumVoltage 6242;
BA_ "SPN" SG_ 2633804542 EngineSparkPlug22MinimumVoltage 6243;
BA_ "SPN" SG_ 2633804542 EngineSparkPlug23MinimumVoltage 6244;
BA_ "SPN" SG_ 2633804542 EngineSparkPlug24MinimumVoltage 6245;
BA_ "SPN" SG_ 2633804798 EngineSparkPlug17MinimumVoltage 6238;
BA_ "SPN" SG_ 2633804798 EngineSparkPlug18MinimumVoltage 6239;
BA_ "SPN" SG_ 2633804798 EngineSparkPlug19MinimumVoltage 6240;
BA_ "SPN" SG_ 2633804798 EngineSparkPlug20MinimumVoltage 6241;
BA_ "SPN" SG_ 2633805054 EngineSparkPlug13MinimumVoltage 6234;
BA_ "SPN" SG_ 2633805054 EngineSparkPlug14MinimumVoltage 6235;
BA_ "SPN" SG_ 2633805054 EngineSparkPlug15MinimumVoltage 6236;
BA_ "SPN" SG_ 2633805054 EngineSparkPlug16MinimumVoltage 6237;
BA_ "SPN" SG_ 2633805310 EngineSparkPlug10MinimumVoltage 6231;
BA_ "SPN" SG_ 2633805310 EngineSparkPlug11MinimumVoltage 6232;
BA_ "SPN" SG_ 2633805310 EngineSparkPlug12MinimumVoltage 6233;
BA_ "SPN" SG_ 2633805310 EngineSparkPlug9MinimumVoltage 6230;
BA_ "SPN" SG_ 2633805566 EngineSparkPlug5MinimumVoltage 6226;
BA_ "SPN" SG_ 2633805566 EngineSparkPlug6MinimumVoltage 6227;
BA_ "SPN" SG_ 2633805566 EngineSparkPlug7MinimumVoltage 6228;
BA_ "SPN" SG_ 2633805566 EngineSparkPlug8MinimumVoltage 6229;
BA_ "SPN" SG_ 2633805822 EngineSparkPlug1MinimumVoltage 6222;
BA_ "SPN" SG_ 2633805822 EngineSparkPlug2MinimumVoltage 6223;
BA_ "SPN" SG_ 2633805822 EngineSparkPlug3MinimumVoltage 6224;
BA_ "SPN" SG_ 2633805822 EngineSparkPlug4MinimumVoltage 6225;
BA_ "SPN" SG_ 2633806078 EngnIgntnCntrlMdl1TmRmnng 6220;
BA_ "SPN" SG_ 2633806078 EngnIgntnCntrlMdl2TmRmnng 6221;
BA_ "SPN" SG_ 2633825022 EngnExhstGsRrltn2Vlv1Cntrl 5264;
BA_ "SPN" SG_ 2633825022 EngnExhstGsRrltn2Vlv1PstnErrr 5831;
BA_ "SPN" SG_ 2633825022 EngnExhstGsRrltn2Vlv2Cntrl 5265;
BA_ "SPN" SG_ 2633825022 EngnExhstGsRrltn2Vlv2PstnErrr 5832;
BA_ "SPN" SG_ 2633825534 EExstMdB1FwBVvAttCt 5276;
BA_ "SPN" SG_ 2633825534 EExstMdB2FwBVvAttCt 5278;
BA_ "SPN" SG_ 2633826046 EExstGsRt2CBpssAttPst 5261;
BA_ "SPN" SG_ 2633826046 EExstGsRt2CItGsAstPss 5259;
BA_ "SPN" SG_ 2633826046 EngnExhstGsRrltn2ClrEffn 5260;
BA_ "SPN" SG_ 2633826046 EngnExhstGsRrltn2ClrIntkPrssr 9380;
BA_ "SPN" SG_ 2633826046 EngnExhstGsRrltn2ClrIntkTmprtr 5258;
BA_ "SPN" SG_ 2633828606 EngineOilDensity 5056;
BA_ "SPN" SG_ 2633828606 EngineOilTemperature3 5925;
BA_ "SPN" SG_ 2633828606 EngineOilViscosity 5055;
BA_ "SPN" SG_ 2633828606 EngnOlRltvDltrtHghRsltn 5468;
BA_ "SPN" SG_ 2633832702 FrontalCollisionSensor1Type 4918;
BA_ "SPN" SG_ 2633832702 FrontalCollisionSensor2Type 4919;
BA_ "SPN" SG_ 2633832702 FrontalCollisionSensor3Type 4920;
BA_ "SPN" SG_ 2633832702 FrontalCollisionSensor4Type 4921;
BA_ "SPN" SG_ 2633832702 RearCollisionSensor1Type 4930;
BA_ "SPN" SG_ 2633832702 RearCollisionSensor2Type 4931;
BA_ "SPN" SG_ 2633832702 RearCollisionSensor3Type 4932;
BA_ "SPN" SG_ 2633832702 RearCollisionSensor4Type 4933;
BA_ "SPN" SG_ 2633832702 SdCllsnSnsrFrntLftTp 4922;
BA_ "SPN" SG_ 2633832702 SdCllsnSnsrFrntRghtTp 4926;
BA_ "SPN" SG_ 2633832702 SdCllsnSnsrMdFrntLftTp 4923;
BA_ "SPN" SG_ 2633832702 SdCllsnSnsrMdFrntRghtTp 4927;
BA_ "SPN" SG_ 2633832702 SdCllsnSnsrMdRrLftTp 4924;
BA_ "SPN" SG_ 2633832702 SdCllsnSnsrMdRrRghtTp 4928;
BA_ "SPN" SG_ 2633832702 SdCllsnSnsrRrRghtTp 4929;
BA_ "SPN" SG_ 2633832702 SideCollisionSensorRearLeftType 4925;
BA_ "SPN" SG_ 2633832958 DrvrArgIgntrLp1stStgRsstn 4818;
BA_ "SPN" SG_ 2633832958 DrvrArgIgntrLp2ndStgRsstn 4820;
BA_ "SPN" SG_ 2633832958 DrvrBltTnsnrIgntrLpRsstn 4822;
BA_ "SPN" SG_ 2633832958 PssngrArgIgntrLp1stStgRsstn 4819;
BA_ "SPN" SG_ 2633832958 PssngrArgIgntrLp2ndStgRsstn 4821;
BA_ "SPN" SG_ 2633832958 PssngrBltTnsnrIgntrLpRsstn 4823;
BA_ "SPN" SG_ 2633832958 SdBgIgntrLp1LftRsstn 4824;
BA_ "SPN" SG_ 2633832958 SdBgIgntrLp1RghtRsstn 4826;
BA_ "SPN" SG_ 2633832958 SdBgIgntrLp2LftRsstn 4825;
BA_ "SPN" SG_ 2633832958 SdBgIgntrLp2RghtRsstn 4827;
BA_ "SPN" SG_ 2633832958 SpecialIgnitorLoop10Resistance 4837;
BA_ "SPN" SG_ 2633832958 SpecialIgnitorLoop11Resistance 4838;
BA_ "SPN" SG_ 2633832958 SpecialIgnitorLoop12Resistance 4839;
BA_ "SPN" SG_ 2633832958 SpecialIgnitorLoop13Resistance 4840;
BA_ "SPN" SG_ 2633832958 SpecialIgnitorLoop14Resistance 4841;
BA_ "SPN" SG_ 2633832958 SpecialIgnitorLoop15Resistance 4842;
BA_ "SPN" SG_ 2633832958 SpecialIgnitorLoop16Resistance 4843;
BA_ "SPN" SG_ 2633832958 SpecialIgnitorLoop17Resistance 4844;
BA_ "SPN" SG_ 2633832958 SpecialIgnitorLoop18Resistance 4845;
BA_ "SPN" SG_ 2633832958 SpecialIgnitorLoop19Resistance 4846;
BA_ "SPN" SG_ 2633832958 SpecialIgnitorLoop1Resistance 4828;
BA_ "SPN" SG_ 2633832958 SpecialIgnitorLoop20Resistance 4847;
BA_ "SPN" SG_ 2633832958 SpecialIgnitorLoop21Resistance 4848;
BA_ "SPN" SG_ 2633832958 SpecialIgnitorLoop22Resistance 4849;
BA_ "SPN" SG_ 2633832958 SpecialIgnitorLoop23Resistance 4850;
BA_ "SPN" SG_ 2633832958 SpecialIgnitorLoop24Resistance 4851;
BA_ "SPN" SG_ 2633832958 SpecialIgnitorLoop25Resistance 4852;
BA_ "SPN" SG_ 2633832958 SpecialIgnitorLoop26Resistance 4853;
BA_ "SPN" SG_ 2633832958 SpecialIgnitorLoop27Resistance 4854;
BA_ "SPN" SG_ 2633832958 SpecialIgnitorLoop28Resistance 4855;
BA_ "SPN" SG_ 2633832958 SpecialIgnitorLoop29Resistance 4856;
BA_ "SPN" SG_ 2633832958 SpecialIgnitorLoop2Resistance 4829;
BA_ "SPN" SG_ 2633832958 SpecialIgnitorLoop30Resistance 4857;
BA_ "SPN" SG_ 2633832958 SpecialIgnitorLoop31Resistance 4858;
BA_ "SPN" SG_ 2633832958 SpecialIgnitorLoop32Resistance 4859;
BA_ "SPN" SG_ 2633832958 SpecialIgnitorLoop33Resistance 4860;
BA_ "SPN" SG_ 2633832958 SpecialIgnitorLoop34Resistance 4861;
BA_ "SPN" SG_ 2633832958 SpecialIgnitorLoop35Resistance 4862;
BA_ "SPN" SG_ 2633832958 SpecialIgnitorLoop36Resistance 4863;
BA_ "SPN" SG_ 2633832958 SpecialIgnitorLoop37Resistance 4864;
BA_ "SPN" SG_ 2633832958 SpecialIgnitorLoop38Resistance 4865;
BA_ "SPN" SG_ 2633832958 SpecialIgnitorLoop39Resistance 4866;
BA_ "SPN" SG_ 2633832958 SpecialIgnitorLoop3Resistance 4830;
BA_ "SPN" SG_ 2633832958 SpecialIgnitorLoop40Resistance 4867;
BA_ "SPN" SG_ 2633832958 SpecialIgnitorLoop41Resistance 4868;
BA_ "SPN" SG_ 2633832958 SpecialIgnitorLoop42Resistance 4869;
BA_ "SPN" SG_ 2633832958 SpecialIgnitorLoop43Resistance 4870;
BA_ "SPN" SG_ 2633832958 SpecialIgnitorLoop44Resistance 4871;
BA_ "SPN" SG_ 2633832958 SpecialIgnitorLoop45Resistance 4872;
BA_ "SPN" SG_ 2633832958 SpecialIgnitorLoop46Resistance 4873;
BA_ "SPN" SG_ 2633832958 SpecialIgnitorLoop47Resistance 4874;
BA_ "SPN" SG_ 2633832958 SpecialIgnitorLoop48Resistance 4875;
BA_ "SPN" SG_ 2633832958 SpecialIgnitorLoop49Resistance 4876;
BA_ "SPN" SG_ 2633832958 SpecialIgnitorLoop4Resistance 4831;
BA_ "SPN" SG_ 2633832958 SpecialIgnitorLoop50Resistance 4877;
BA_ "SPN" SG_ 2633832958 SpecialIgnitorLoop51Resistance 4878;
BA_ "SPN" SG_ 2633832958 SpecialIgnitorLoop52Resistance 4879;
BA_ "SPN" SG_ 2633832958 SpecialIgnitorLoop53Resistance 4880;
BA_ "SPN" SG_ 2633832958 SpecialIgnitorLoop54Resistance 4881;
BA_ "SPN" SG_ 2633832958 SpecialIgnitorLoop55Resistance 4882;
BA_ "SPN" SG_ 2633832958 SpecialIgnitorLoop56Resistance 4883;
BA_ "SPN" SG_ 2633832958 SpecialIgnitorLoop57Resistance 4884;
BA_ "SPN" SG_ 2633832958 SpecialIgnitorLoop58Resistance 4885;
BA_ "SPN" SG_ 2633832958 SpecialIgnitorLoop59Resistance 4886;
BA_ "SPN" SG_ 2633832958 SpecialIgnitorLoop5Resistance 4832;
BA_ "SPN" SG_ 2633832958 SpecialIgnitorLoop60Resistance 4887;
BA_ "SPN" SG_ 2633832958 SpecialIgnitorLoop61Resistance 4888;
BA_ "SPN" SG_ 2633832958 SpecialIgnitorLoop62Resistance 4889;
BA_ "SPN" SG_ 2633832958 SpecialIgnitorLoop63Resistance 4890;
BA_ "SPN" SG_ 2633832958 SpecialIgnitorLoop64Resistance 4891;
BA_ "SPN" SG_ 2633832958 SpecialIgnitorLoop65Resistance 4892;
BA_ "SPN" SG_ 2633832958 SpecialIgnitorLoop66Resistance 4893;
BA_ "SPN" SG_ 2633832958 SpecialIgnitorLoop67Resistance 4894;
BA_ "SPN" SG_ 2633832958 SpecialIgnitorLoop68Resistance 4895;
BA_ "SPN" SG_ 2633832958 SpecialIgnitorLoop69Resistance 4896;
BA_ "SPN" SG_ 2633832958 SpecialIgnitorLoop6Resistance 4833;
BA_ "SPN" SG_ 2633832958 SpecialIgnitorLoop70Resistance 4897;
BA_ "SPN" SG_ 2633832958 SpecialIgnitorLoop71Resistance 4898;
BA_ "SPN" SG_ 2633832958 SpecialIgnitorLoop72Resistance 4899;
BA_ "SPN" SG_ 2633832958 SpecialIgnitorLoop73Resistance 4900;
BA_ "SPN" SG_ 2633832958 SpecialIgnitorLoop74Resistance 4901;
BA_ "SPN" SG_ 2633832958 SpecialIgnitorLoop75Resistance 4902;
BA_ "SPN" SG_ 2633832958 SpecialIgnitorLoop76Resistance 4903;
BA_ "SPN" SG_ 2633832958 SpecialIgnitorLoop77Resistance 4904;
BA_ "SPN" SG_ 2633832958 SpecialIgnitorLoop78Resistance 4905;
BA_ "SPN" SG_ 2633832958 SpecialIgnitorLoop79Resistance 4906;
BA_ "SPN" SG_ 2633832958 SpecialIgnitorLoop7Resistance 4834;
BA_ "SPN" SG_ 2633832958 SpecialIgnitorLoop80Resistance 4907;
BA_ "SPN" SG_ 2633832958 SpecialIgnitorLoop81Resistance 4908;
BA_ "SPN" SG_ 2633832958 SpecialIgnitorLoop82Resistance 4909;
BA_ "SPN" SG_ 2633832958 SpecialIgnitorLoop83Resistance 4910;
BA_ "SPN" SG_ 2633832958 SpecialIgnitorLoop84Resistance 4911;
BA_ "SPN" SG_ 2633832958 SpecialIgnitorLoop85Resistance 4912;
BA_ "SPN" SG_ 2633832958 SpecialIgnitorLoop86Resistance 4913;
BA_ "SPN" SG_ 2633832958 SpecialIgnitorLoop87Resistance 4914;
BA_ "SPN" SG_ 2633832958 SpecialIgnitorLoop88Resistance 4915;
BA_ "SPN" SG_ 2633832958 SpecialIgnitorLoop89Resistance 4916;
BA_ "SPN" SG_ 2633832958 SpecialIgnitorLoop8Resistance 4835;
BA_ "SPN" SG_ 2633832958 SpecialIgnitorLoop90Resistance 4917;
BA_ "SPN" SG_ 2633832958 SpecialIgnitorLoop9Resistance 4836;
BA_ "SPN" SG_ 2633853438 AdditionalAxleGroupLocation 5936;
BA_ "SPN" SG_ 2633853438 AxleGroupEmptyWeightCalibration 408;
BA_ "SPN" SG_ 2633853438 AxleGroupFullWeightCalibration 407;
BA_ "SPN" SG_ 2633853438 AxleGroupLocation 4074;
BA_ "SPN" SG_ 2633861886 J2012DTC 3620;
BA_ "SPN" SG_ 2633861886 J2012DTCOccurrenceCount 3622;
BA_ "SPN" SG_ 2633861886 J2012DTCStatus 3621;
BA_ "SPN" SG_ 2633861886 NumberofJ2012DTCs 3619;
BA_ "SPN" SG_ 2633869310 VltgRgltrLdCmpnstnMd 3375;
BA_ "SPN" SG_ 2633869310 VltgRgltrUndrfrqnCmpnstnnld 3377;
BA_ "SPN" SG_ 2633869310 VltgRgltrVArPwrFtrprtngmd 3376;
BA_ "SPN" SG_ 2633869310 VoltageRegulatorEnabled 3379;
BA_ "SPN" SG_ 2633869310 VoltageRegulatorSoftStartState 3378;
BA_ "SPN" SG_ 2633878014 TtlCntfCnfgrtnChngsMd 2887;
BA_ "SPN" SG_ 2633880062 FMSstandardDiagnosticsSupported 2804;
BA_ "SPN" SG_ 2633880062 FMSstandardRequestsSupported 2805;
BA_ "SPN" SG_ 2633880062 FMSstandardSWversionsupported 2806;
BA_ "SPN" SG_ 2633883646 FrontWheelDriveActuatorStatus 2612;
BA_ "SPN" SG_ 2633911806 EngineTotalAverageFuelEconomy 1835;
BA_ "SPN" SG_ 2633911806 EngineTotalAverageFuelRate 1834;
BA_ "SPN" SG_ 2633922558 AuxiliaryGagePressureReading1 137;
BA_ "SPN" SG_ 2633922558 AuxiliaryVacuumPressureReading 136;
BA_ "SPN" SG_ 2633922558 AxlrAsltPrssrRdng 138;
BA_ "SPN" SG_ 2633922814 DriveChannelMode 1468;
BA_ "SPN" SG_ 2633922814 PCUControlSolenoidStatus 1473;
BA_ "SPN" SG_ 2633922814 PCUDeflateSolenoidStatus 1472;
BA_ "SPN" SG_ 2633922814 PCUDriveSolenoidStatus 1469;
BA_ "SPN" SG_ 2633922814 PCUSteerSolenoidStatus 1470;
BA_ "SPN" SG_ 2633922814 PCUSupplySolenoidStatus 1474;
BA_ "SPN" SG_ 2633922814 PCUTrlrTgrPshSlndStts 1475;
BA_ "SPN" SG_ 2633922814 SteerChannelMode 1466;
BA_ "SPN" SG_ 2633922814 TirePressureCheckInterval 39;
BA_ "SPN" SG_ 2633922814 TirePressureSupplySwitchStatus 1471;
BA_ "SPN" SG_ 2633922814 TrailertagChannelMode 1467;
BA_ "SPN" SG_ 2633923070 DriveChannelTirePressureTarget 142;
BA_ "SPN" SG_ 2633923070 SteerChannelTirePressureTarget 143;
BA_ "SPN" SG_ 2633923070 TrlrTgOrPshChnnlTrPrssrTrgt 141;
BA_ "SPN" SG_ 2633923326 DriveChannelTirePressure 145;
BA_ "SPN" SG_ 2633923326 SteerChannelTirePressure 146;
BA_ "SPN" SG_ 2633923326 TrlrTgOrPshChnnlTrPrssr 144;
BA_ "SPN" SG_ 2633923582 EngineCylinder1CombustionTime 1444;
BA_ "SPN" SG_ 2633923582 EngineCylinder2CombustionTime 1445;
BA_ "SPN" SG_ 2633923582 EngineCylinder3CombustionTime 1446;
BA_ "SPN" SG_ 2633923582 EngineCylinder4CombustionTime 1447;
BA_ "SPN" SG_ 2633923838 EngineCylinder5CombustionTime 1448;
BA_ "SPN" SG_ 2633923838 EngineCylinder6CombustionTime 1449;
BA_ "SPN" SG_ 2633923838 EngineCylinder7CombustionTime 1450;
BA_ "SPN" SG_ 2633923838 EngineCylinder8CombustionTime 1451;
BA_ "SPN" SG_ 2633924094 EngineCylinder10CombustionTime 1453;
BA_ "SPN" SG_ 2633924094 EngineCylinder11CombustionTime 1454;
BA_ "SPN" SG_ 2633924094 EngineCylinder12CombustionTime 1455;
BA_ "SPN" SG_ 2633924094 EngineCylinder9CombustionTime 1452;
BA_ "SPN" SG_ 2633924350 EngineCylinder13CombustionTime 1456;
BA_ "SPN" SG_ 2633924350 EngineCylinder14CombustionTime 1457;
BA_ "SPN" SG_ 2633924350 EngineCylinder15CombustionTime 1458;
BA_ "SPN" SG_ 2633924350 EngineCylinder16CombustionTime 1459;
BA_ "SPN" SG_ 2633924606 EngineCylinder17CombustionTime 1460;
BA_ "SPN" SG_ 2633924606 EngineCylinder18CombustionTime 1461;
BA_ "SPN" SG_ 2633924606 EngineCylinder19CombustionTime 1462;
BA_ "SPN" SG_ 2633924606 EngineCylinder20CombustionTime 1463;
BA_ "SPN" SG_ 2633924862 EngineAverageCombustionTime 1465;
BA_ "SPN" SG_ 2633924862 EngineDesiredCombustionTime 1464;
BA_ "SPN" SG_ 2633925118 EngineFuelFlowRate1 1440;
BA_ "SPN" SG_ 2633925118 EngineFuelFlowRate2 1441;
BA_ "SPN" SG_ 2633925118 EngineFuelValve1Position 1442;
BA_ "SPN" SG_ 2633925118 EngineFuelValve2Position 1443;
BA_ "SPN" SG_ 2633925118 EngnFlVlv1CmmnddPstn 1765;
BA_ "SPN" SG_ 2633925118 EngnFlVlv2CmmnddPstn 1766;
BA_ "SPN" SG_ 2633925374 EngineCylinder1IgnitionTiming 1413;
BA_ "SPN" SG_ 2633925374 EngineCylinder2IgnitionTiming 1414;
BA_ "SPN" SG_ 2633925374 EngineCylinder3IgnitionTiming 1415;
BA_ "SPN" SG_ 2633925374 EngineCylinder4IgnitionTiming 1416;
BA_ "SPN" SG_ 2633925630 EngineCylinder5IgnitionTiming 1417;
BA_ "SPN" SG_ 2633925630 EngineCylinder6IgnitionTiming 1418;
BA_ "SPN" SG_ 2633925630 EngineCylinder7IgnitionTiming 1419;
BA_ "SPN" SG_ 2633925630 EngineCylinder8IgnitionTiming 1420;
BA_ "SPN" SG_ 2633925886 EngineCylinder10IgnitionTiming 1422;
BA_ "SPN" SG_ 2633925886 EngineCylinder11IgnitionTiming 1423;
BA_ "SPN" SG_ 2633925886 EngineCylinder12IgnitionTiming 1424;
BA_ "SPN" SG_ 2633925886 EngineCylinder9IgnitionTiming 1421;
BA_ "SPN" SG_ 2633926142 EngineCylinder13IgnitionTiming 1425;
BA_ "SPN" SG_ 2633926142 EngineCylinder14IgnitionTiming 1426;
BA_ "SPN" SG_ 2633926142 EngineCylinder15IgnitionTiming 1427;
BA_ "SPN" SG_ 2633926142 EngineCylinder16IgnitionTiming 1428;
BA_ "SPN" SG_ 2633926398 EngineCylinder17IgnitionTiming 1429;
BA_ "SPN" SG_ 2633926398 EngineCylinder18IgnitionTiming 1430;
BA_ "SPN" SG_ 2633926398 EngineCylinder19IgnitionTiming 1431;
BA_ "SPN" SG_ 2633926398 EngineCylinder20IgnitionTiming 1432;
BA_ "SPN" SG_ 2633926654 EngineActualIgnitionTiming 1436;
BA_ "SPN" SG_ 2633926654 EngineDesiredIgnitionTiming1 1433;
BA_ "SPN" SG_ 2633926654 EngineDesiredIgnitionTiming2 1434;
BA_ "SPN" SG_ 2633926654 EngineDesiredIgnitionTiming3 1435;
BA_ "SPN" SG_ 2633926910 EngnClndr1IgntnTrnsfrmrSndrOtpt 1393;
BA_ "SPN" SG_ 2633926910 EngnClndr2IgntnTrnsfrmrSndrOtpt 1394;
BA_ "SPN" SG_ 2633926910 EngnClndr3IgntnTrnsfrmrSndrOtpt 1395;
BA_ "SPN" SG_ 2633926910 EngnClndr4IgntnTrnsfrmrSndrOtpt 1396;
BA_ "SPN" SG_ 2633926910 EngnClndr5IgntnTrnsfrmrSndrOtpt 1397;
BA_ "SPN" SG_ 2633926910 EngnClndr6IgntnTrnsfrmrSndrOtpt 1398;
BA_ "SPN" SG_ 2633926910 EngnClndr7IgntnTrnsfrmrSndrOtpt 1399;
BA_ "SPN" SG_ 2633926910 EngnClndr8IgntnTrnsfrmrSndrOtpt 1400;
BA_ "SPN" SG_ 2633927166 ECd10ItTsSdOtpt 1402;
BA_ "SPN" SG_ 2633927166 ECd11ItTsSdOtpt 1403;
BA_ "SPN" SG_ 2633927166 ECd12ItTsSdOtpt 1404;
BA_ "SPN" SG_ 2633927166 ECd13ItTsSdOtpt 1405;
BA_ "SPN" SG_ 2633927166 ECd14ItTsSdOtpt 1406;
BA_ "SPN" SG_ 2633927166 ECd15ItTsSdOtpt 1407;
BA_ "SPN" SG_ 2633927166 ECd16ItTsSdOtpt 1408;
BA_ "SPN" SG_ 2633927166 EngnClndr9IgntnTrnsfrmrSndrOtpt 1401;
BA_ "SPN" SG_ 2633927422 ECd17ItTsSdOtpt 1409;
BA_ "SPN" SG_ 2633927422 ECd18ItTsSdOtpt 1410;
BA_ "SPN" SG_ 2633927422 ECd19ItTsSdOtpt 1411;
BA_ "SPN" SG_ 2633927422 ECd20ItTsSdOtpt 1412;
BA_ "SPN" SG_ 2633927678 EngnArtFlDffrntlPrssr 1392;
BA_ "SPN" SG_ 2633927678 EngnFlVlv1DffrntlPrssr 1391;
BA_ "SPN" SG_ 2633927678 EngnFlVlv1IntkAsltPrssr 1390;
BA_ "SPN" SG_ 2633927678 EngnFlVlv1OtltAsltPrssr 2980;
BA_ "SPN" SG_ 2633927934 AuxiliaryLevel 3087;
BA_ "SPN" SG_ 2633927934 AuxiliaryPressure1 1387;
BA_ "SPN" SG_ 2633927934 AuxiliaryPressure2 1388;
BA_ "SPN" SG_ 2633927934 AuxiliaryTemperature1 441;
BA_ "SPN" SG_ 2633927934 AuxiliaryTemperature2 442;
BA_ "SPN" SG_ 2633927934 RelativeHumidity 354;
BA_ "SPN" SG_ 2633928446 ServiceComponentIdentification 1379;
BA_ "SPN" SG_ 2633928446 TimeSinceLastService 1350;
BA_ "SPN" SG_ 2633929214 EngineFluidBundLevel 7785;
BA_ "SPN" SG_ 2633929214 EngineFuelLeakage1 1239;
BA_ "SPN" SG_ 2633929214 EngineFuelLeakage2 1240;
VAL_ 2631728894 AntitheftComponentStatusStates 3 "NotDefined" 2 "BlckdThsSttIndctsThtALckUnlckCm" 1 "LckdThsSttIndctsThtCmpnntCnNOTB" 0 "UnlckdThsSttIndctsThtCmpnntCnBS" ;
VAL_ 2631794430 AntitheftDesiredExitModeStates 3 "NtAvlblThsSttIsIndctsThtOptnIsN" 2 "NotDefined" 1 "LckWhnKyffThsSttIsUsdTIndctThtC" 0 "LckUpnOprtrRqThsSttIsUsdTIndctT" ;
VAL_ 2631859966 TripGroup1 2 "Reserved" 3 "NotApplicable" 1 "Reset" 0 "TakeNoAction" ;
VAL_ 2631859966 TripGroup2Proprietary 2 "Reserved" 3 "NotApplicable" 1 "Reset" 0 "TakeNoAction" ;
VAL_ 2633832702 FrontalCollisionSensor1Type 15 "NotAvailable" 14 "ErrrTypOfSnsrCannotBeDetermined" 8 "1101Reserved" 7 "OpticalSensor" 6 "LidarSensor" 5 "RadarSensor" 4 "FiberopticSensor" 3 "SonicSensor" 2 "RollrateSensor" 1 "PressSensor" 0 "AccelerationSensor" ;
VAL_ 2633832702 FrontalCollisionSensor2Type 15 "NotAvailable" 14 "ErrrTypOfSnsrCannotBeDetermined" 8 "1101Reserved" 7 "OpticalSensor" 6 "LidarSensor" 5 "RadarSensor" 4 "FiberopticSensor" 3 "SonicSensor" 2 "RollrateSensor" 1 "PressSensor" 0 "AccelerationSensor" ;
VAL_ 2633832702 FrontalCollisionSensor3Type 15 "NotAvailable" 14 "ErrrTypOfSnsrCannotBeDetermined" 8 "1101Reserved" 7 "OpticalSensor" 6 "LidarSensor" 5 "RadarSensor" 4 "FiberopticSensor" 3 "SonicSensor" 2 "RollrateSensor" 1 "PressSensor" 0 "AccelerationSensor" ;
VAL_ 2633832702 FrontalCollisionSensor4Type 15 "NotAvailable" 14 "ErrrTypOfSnsrCannotBeDetermined" 8 "1101Reserved" 7 "OpticalSensor" 6 "LidarSensor" 5 "RadarSensor" 4 "FiberopticSensor" 3 "SonicSensor" 2 "RollrateSensor" 1 "PressSensor" 0 "AccelerationSensor" ;
VAL_ 2633832702 RearCollisionSensor1Type 15 "NotAvailable" 14 "ErrrTypOfSnsrCannotBeDetermined" 8 "1101Reserved" 7 "OpticalSensor" 6 "LidarSensor" 5 "RadarSensor" 4 "FiberopticSensor" 3 "SonicSensor" 2 "RollrateSensor" 1 "PressSensor" 0 "AccelerationSensor" ;
VAL_ 2633832702 RearCollisionSensor2Type 15 "NotAvailable" 14 "ErrrTypOfSnsrCannotBeDetermined" 8 "1101Reserved" 7 "OpticalSensor" 6 "LidarSensor" 5 "RadarSensor" 4 "FiberopticSensor" 3 "SonicSensor" 2 "RollrateSensor" 1 "PressSensor" 0 "AccelerationSensor" ;
VAL_ 2633832702 RearCollisionSensor3Type 15 "NotAvailable" 14 "ErrrTypOfSnsrCannotBeDetermined" 8 "1101Reserved" 7 "OpticalSensor" 6 "LidarSensor" 5 "RadarSensor" 4 "FiberopticSensor" 3 "SonicSensor" 2 "RollrateSensor" 1 "PressSensor" 0 "AccelerationSensor" ;
VAL_ 2633832702 RearCollisionSensor4Type 15 "NotAvailable" 14 "ErrrTypOfSnsrCannotBeDetermined" 8 "1101Reserved" 7 "OpticalSensor" 6 "LidarSensor" 5 "RadarSensor" 4 "FiberopticSensor" 3 "SonicSensor" 2 "RollrateSensor" 1 "PressSensor" 0 "AccelerationSensor" ;
VAL_ 2633832702 SideCollisionSensorRearLeftType 15 "NotAvailable" 14 "ErrrTypOfSnsrCannotBeDetermined" 8 "1101Reserved" 7 "OpticalSensor" 6 "LidarSensor" 5 "RadarSensor" 4 "FiberopticSensor" 3 "SonicSensor" 2 "RollrateSensor" 1 "PressSensor" 0 "AccelerationSensor" ;
VAL_ 2633853438 AxleGroupLocation 3 "TrailerFAxleGroup" 2 "TrailerEAxleGroup" 1 "SteerAxleGroup" 0 "Reserved" ;
VAL_ 2633861886 J2012DTCStatus 1 "DTCIsActive" 0 "DTCIsPreviouslyActive" ;
VAL_ 2633869310 VoltageRegulatorEnabled 3 "NotAvailable" 2 "Error" 1 "RegulatingVoltage" 0 "NtRegulatingVoltageUnitDisabled" ;
VAL_ 2633869310 VoltageRegulatorSoftStartState 3 "NotAvailable" 2 "Error" 1 "SoftStartIsActive" 0 "SoftStartIsInactive" ;
VAL_ 2633880062 FMSstandardDiagnosticsSupported 3 "DontCare" 2 "Reserved" 1 "DiagnosticsIsSupported" 0 "DiagnosticsIsNotSupported" ;
VAL_ 2633883646 FrontWheelDriveActuatorStatus 3 "NotAvailable" 2 "Error" 1 "FrontWheelDriveActuatorEngaged" 0 "FrntWhelDriveActuatorNotEngaged" ;
VAL_ 2633922814 DriveChannelMode 15 "NotAvailable" 14 "ErrorCondition" 7 "1101Reserved" 6 "PressCheck" 5 "DfltWtSystmWllDfltWhnCndtnsAllw" 4 "InfltWtSystmWllInfltWhnCndtnsAl" 3 "Confirm" 2 "Deflate" 1 "Inflate" 0 "Maintain" ;
VAL_ 2633922814 PCUDeflateSolenoidStatus 3 "NotAvailable" 2 "Error" 1 "On" 0 "Off" ;
VAL_ 2633922814 PCUDriveSolenoidStatus 3 "NotAvailable" 2 "Error" 1 "On" 0 "Off" ;
VAL_ 2633922814 PCUSteerSolenoidStatus 3 "NotAvailable" 2 "Error" 1 "On" 0 "Off" ;
VAL_ 2633922814 PCUSupplySolenoidStatus 3 "NotAvailable" 2 "Error" 1 "On" 0 "Off" ;
VAL_ 2633922814 SteerChannelMode 15 "NotAvailable" 14 "ErrorCondition" 7 "1101Reserved" 6 "PressCheck" 5 "DfltWtSystmWllDfltWhnCndtnsAllw" 4 "InfltWtSystmWllInfltWhnCndtnsAl" 3 "Confirm" 2 "Deflate" 1 "Inflate" 0 "Maintain" ;
VAL_ 2631728894 AntthftEnrptnSdPrsntIndtr 3 "NotAvailable" 2 "Error" 1 "RandomNumberIsPresent" 0 "RandomNumberIsNotPresent" ;
VAL_ 2631728894 AntitheftPasswordValidIndicator 3 "NotAvailable" 2 "Error" 1 "PwdIsAValidatedPassword" 0 "PwdIsNotAValidatedPassword" ;
VAL_ 2631728894 AntitheftModifyPasswordStates 3 "Notvalid" 2 "EmptyOfPwdsThsSttIndctsThtCmpnn" 1 "FullofPwds" 0 "OkThsSttIndctsThtRqWsSccssfllyP" ;
VAL_ 2631794430 AntthftEnrptnIndtrStts 3 "NtAvlblThsSttIsUsdTIndctThtARnd" 2 "NotDefined" 1 "EncryptdCdPrsntThsSttIsUsdTIndc" 0 "EncryptnSdRqThsSttRprsntsARqstT" ;
VAL_ 2631794430 AntitheftCommandStates 6 "111NotDefined" 5 "Login" 4 "ChckSttsThsSttRprsntsARqTChckTS" 3 "LockorUnlock" 2 "ChngPwdThsSttRprsntsARqTCmpnntT" 1 "DeletePwd" 0 "AddPwdThsSttRprsntsARqTCmpnntTA" ;
VAL_ 2631859966 EngineBuildHoursReset 2 "Reserved" 3 "TakeNoAction" 1 "Reset" 0 "DoNotReset" ;
VAL_ 2631859966 StrngStrghtAhdPstnRst 3 "NotApplicable" 2 "ReservedTakeNoAction" 1 "Reset" 0 "TakeNoActionDoNotReset" ;
VAL_ 2633832702 SdCllsnSnsrFrntLftTp 15 "NotAvailable" 14 "ErrrTypOfSnsrCannotBeDetermined" 8 "1101Reserved" 7 "OpticalSensor" 6 "LidarSensor" 5 "RadarSensor" 4 "FiberopticSensor" 3 "SonicSensor" 2 "RollrateSensor" 1 "PressSensor" 0 "AccelerationSensor" ;
VAL_ 2633832702 SdCllsnSnsrMdFrntLftTp 15 "NotAvailable" 14 "ErrrTypOfSnsrCannotBeDetermined" 8 "1101Reserved" 7 "OpticalSensor" 6 "LidarSensor" 5 "RadarSensor" 4 "FiberopticSensor" 3 "SonicSensor" 2 "RollrateSensor" 1 "PressSensor" 0 "AccelerationSensor" ;
VAL_ 2633832702 SdCllsnSnsrMdRrLftTp 15 "NotAvailable" 14 "ErrrTypOfSnsrCannotBeDetermined" 8 "1101Reserved" 7 "OpticalSensor" 6 "LidarSensor" 5 "RadarSensor" 4 "FiberopticSensor" 3 "SonicSensor" 2 "RollrateSensor" 1 "PressSensor" 0 "AccelerationSensor" ;
VAL_ 2633832702 SdCllsnSnsrFrntRghtTp 15 "NotAvailable" 14 "ErrrTypOfSnsrCannotBeDetermined" 8 "1101Reserved" 7 "OpticalSensor" 6 "LidarSensor" 5 "RadarSensor" 4 "FiberopticSensor" 3 "SonicSensor" 2 "RollrateSensor" 1 "PressSensor" 0 "AccelerationSensor" ;
VAL_ 2633832702 SdCllsnSnsrMdFrntRghtTp 15 "NotAvailable" 14 "ErrrTypOfSnsrCannotBeDetermined" 8 "1101Reserved" 7 "OpticalSensor" 6 "LidarSensor" 5 "RadarSensor" 4 "FiberopticSensor" 3 "SonicSensor" 2 "RollrateSensor" 1 "PressSensor" 0 "AccelerationSensor" ;
VAL_ 2633832702 SdCllsnSnsrMdRrRghtTp 15 "NotAvailable" 14 "ErrrTypOfSnsrCannotBeDetermined" 8 "1101Reserved" 7 "OpticalSensor" 6 "LidarSensor" 5 "RadarSensor" 4 "FiberopticSensor" 3 "SonicSensor" 2 "RollrateSensor" 1 "PressSensor" 0 "AccelerationSensor" ;
VAL_ 2633832702 SdCllsnSnsrRrRghtTp 15 "NotAvailable" 14 "ErrrTypOfSnsrCannotBeDetermined" 8 "1101Reserved" 7 "OpticalSensor" 6 "LidarSensor" 5 "RadarSensor" 4 "FiberopticSensor" 3 "SonicSensor" 2 "RollrateSensor" 1 "PressSensor" 0 "AccelerationSensor" ;
VAL_ 2633869310 VltgRgltrLdCmpnstnMd 7 "NotAvailable" 6 "Error" 5 "Reserved" 2 "IRLineDropCompensationEnabled" 1 "VoltageDroopCompensationEnabled" 0 "LoadCompensationDisabled" ;
VAL_ 2633869310 VltgRgltrVArPwrFtrprtngmd 7 "NotAvailable" 6 "Error" 5 "Reserved" 2 "VArRegulationEnabled" 1 "PowerFactorRegulationEnabled" 0 "VAr_PwrFactorRegulationDisabled" ;
VAL_ 2633869310 VltgRgltrUndrfrqnCmpnstnnld 3 "NotAvailable" 2 "Error" 1 "UndrfrquencyCompensationEnabled" 0 "UndrfrqencyCompensationDisabled" ;
VAL_ 2633880062 FMSstandardRequestsSupported 3 "DontCare" 2 "Reserved" 1 "OnRqModeIsSupported" 0 "OnRqModeIsNotSupported" ;
VAL_ 2633922814 TrailertagChannelMode 15 "NotAvailable" 14 "ErrorCondition" 7 "1101Reserved" 6 "PressCheck" 5 "DfltWtSystmWllDfltWhnCndtnsAllw" 4 "InfltWtSystmWllInfltWhnCndtnsAl" 3 "Confirm" 2 "Deflate" 1 "Inflate" 0 "Maintain" ;
VAL_ 2633922814 TirePressureSupplySwitchStatus 3 "NotAvailable" 2 "Error" 1 "On" 0 "Off" ;
VAL_ 2633922814 PCUControlSolenoidStatus 3 "NotAvailable" 2 "Error" 1 "On" 0 "Off" ;
VAL_ 2633922814 PCUTrlrTgrPshSlndStts 3 "NotAvailable" 2 "Error" 1 "On" 0 "Off" ;
VAL_ 2633929214 EngineFuelLeakage1 3 "NotAvailable" 2 "Error" 1 "LeakageDetected" 0 "NoLeakageDetected" ;
VAL_ 2633929214 EngineFuelLeakage2 3 "NotAvailable" 2 "Error" 1 "LeakageDetected" 0 "NoLeakageDetected" ;
VAL_ 2566848510 WaterInFuelIndicator1 3 "NotAvailable" 2 "Error" 1 "Yes" 0 "No" ;
